VERSION "HNNBNNNYNNNNNNNNNNNNNNNNNNNNNNNNNNNNNNNNNN/4/%%%/4/'%**4NNN///"

NS_ :

BS_:

BU_: ABT_1_MIB_ab_Gen3 ABT_1_MQB BAP_Tester BT_1_MQB DU_1_MQB DU_2 DU_3 DU_4 ExBox Kombi_TT3 LSR_1 SCC1 SCC2 SDC1 SDC2 SFA TVTuner_ab_Gen3_JPN WLC_01 WLC_02 ZR_Entry ZR_High ZR_High_Korea ZR_High_TT3 ZR_MIB_OPTION_ab_Gen3 ZR_MIB_TOP_ab_Gen3 ZR_Standard

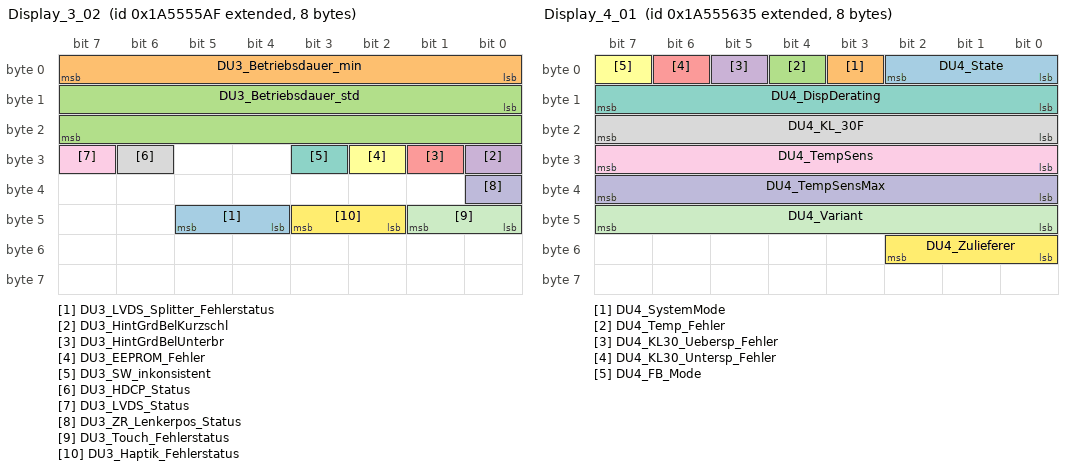
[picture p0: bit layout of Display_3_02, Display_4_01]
BO_ 2589283759 Display_3_02: 8 DU_3
 SG_ DU3_LVDS_Splitter_Fehlerstatus : 44|2@1+ (1,0) [0|3] ""  ZR_High,ZR_MIB_OPTION_ab_Gen3,ZR_MIB_TOP_ab_Gen3,ZR_Standard
 SG_ DU3_Betriebsdauer_min : 0|8@1+ (1,0) [0|59] "Unit_Minut"  ZR_High,ZR_MIB_TOP_ab_Gen3
 SG_ DU3_Betriebsdauer_std : 8|16@1+ (1,0) [0|65533] "Unit_Hours"  ZR_High,ZR_MIB_TOP_ab_Gen3
 SG_ DU3_HintGrdBelKurzschl : 24|1@1+ (1,0) [0|1] ""  ZR_High,ZR_MIB_TOP_ab_Gen3
 SG_ DU3_HintGrdBelUnterbr : 25|1@1+ (1,0) [0|1] ""  ZR_High,ZR_MIB_TOP_ab_Gen3
 SG_ DU3_EEPROM_Fehler : 26|1@1+ (1,0) [0|1] ""  ZR_High,ZR_MIB_TOP_ab_Gen3
 SG_ DU3_SW_inkonsistent : 27|1@1+ (1,0) [0|1] ""  ZR_High,ZR_MIB_TOP_ab_Gen3
 SG_ DU3_HDCP_Status : 30|1@1+ (1,0) [0|1] ""  ZR_High,ZR_MIB_TOP_ab_Gen3
 SG_ DU3_LVDS_Status : 31|1@1+ (1,0) [0|1] ""  ZR_High,ZR_MIB_TOP_ab_Gen3
 SG_ DU3_ZR_Lenkerpos_Status : 32|1@1+ (1,0) [0|1] ""  ZR_High,ZR_MIB_TOP_ab_Gen3
 SG_ DU3_Touch_Fehlerstatus : 40|2@1+ (1,0) [0|3] ""  ZR_High,ZR_MIB_TOP_ab_Gen3
 SG_ DU3_Haptik_Fehlerstatus : 42|2@1+ (1,0) [0|3] ""  ZR_High,ZR_MIB_TOP_ab_Gen3

BO_ 2589283893 Display_4_01: 8 DU_4
 SG_ DU4_State : 0|3@1+ (1,0) [0|7] ""  ZR_High,ZR_MIB_TOP_ab_Gen3
 SG_ DU4_SystemMode : 3|1@1+ (1,0) [0|1] ""  ZR_High,ZR_MIB_TOP_ab_Gen3
 SG_ DU4_Temp_Fehler : 4|1@1+ (1,0) [0|1] ""  ZR_High,ZR_MIB_TOP_ab_Gen3
 SG_ DU4_KL30_Uebersp_Fehler : 5|1@1+ (1,0) [0|1] ""  ZR_High,ZR_MIB_TOP_ab_Gen3
 SG_ DU4_KL30_Untersp_Fehler : 6|1@1+ (1,0) [0|1] ""  ZR_High,ZR_MIB_TOP_ab_Gen3
 SG_ DU4_FB_Mode : 7|1@1+ (1,0) [0|1] ""  ZR_High,ZR_MIB_TOP_ab_Gen3
 SG_ DU4_DispDerating : 8|8@1+ (1,0) [0|100] "Unit_PerCent"  ZR_High,ZR_MIB_TOP_ab_Gen3
 SG_ DU4_KL_30F : 16|8@1+ (0.1,0) [0|25.3] "Unit_Volt"  ZR_High,ZR_MIB_TOP_ab_Gen3
 SG_ DU4_TempSens : 24|8@1+ (1,-55) [-55|127] "Unit_DegreCelsi"  ZR_High,ZR_MIB_TOP_ab_Gen3
 SG_ DU4_TempSensMax : 32|8@1+ (1,-55) [-55|127] "Unit_DegreCelsi"  ZR_High,ZR_MIB_TOP_ab_Gen3
 SG_ DU4_Variant : 40|8@1+ (1,0) [0|253] ""  ZR_High,ZR_MIB_TOP_ab_Gen3
 SG_ DU4_Zulieferer : 48|3@1+ (1,0) [0|7] ""  ZR_High,ZR_MIB_TOP_ab_Gen3

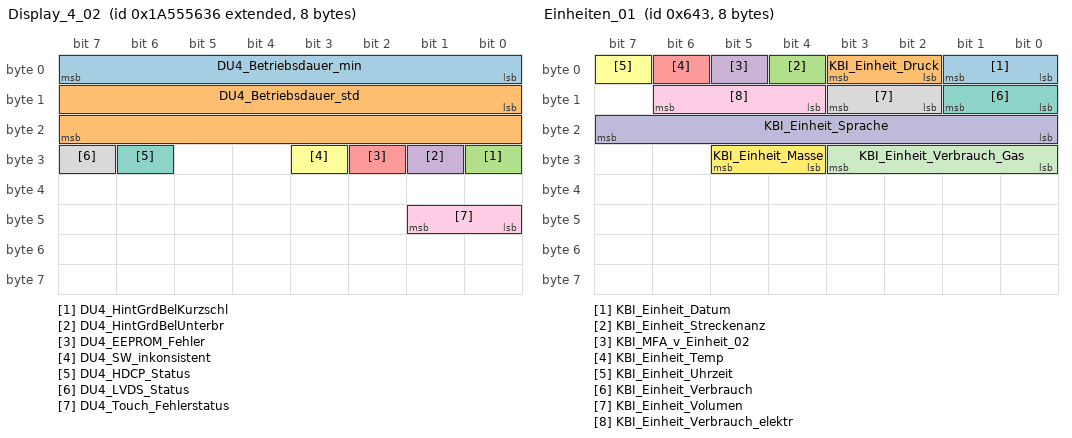
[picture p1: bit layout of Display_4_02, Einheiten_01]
BO_ 2589283894 Display_4_02: 8 DU_4
 SG_ DU4_Betriebsdauer_min : 0|8@1+ (1,0) [0|59] "Unit_Minut"  ZR_High,ZR_MIB_TOP_ab_Gen3
 SG_ DU4_Betriebsdauer_std : 8|16@1+ (1,0) [0|65533] "Unit_Hours"  ZR_High,ZR_MIB_TOP_ab_Gen3
 SG_ DU4_HintGrdBelKurzschl : 24|1@1+ (1,0) [0|1] ""  ZR_High,ZR_MIB_TOP_ab_Gen3
 SG_ DU4_HintGrdBelUnterbr : 25|1@1+ (1,0) [0|1] ""  ZR_High,ZR_MIB_TOP_ab_Gen3
 SG_ DU4_EEPROM_Fehler : 26|1@1+ (1,0) [0|1] ""  ZR_High,ZR_MIB_TOP_ab_Gen3
 SG_ DU4_SW_inkonsistent : 27|1@1+ (1,0) [0|1] ""  ZR_High,ZR_MIB_TOP_ab_Gen3
 SG_ DU4_HDCP_Status : 30|1@1+ (1,0) [0|1] ""  ZR_High,ZR_MIB_TOP_ab_Gen3
 SG_ DU4_LVDS_Status : 31|1@1+ (1,0) [0|1] ""  ZR_High,ZR_MIB_TOP_ab_Gen3
 SG_ DU4_Touch_Fehlerstatus : 40|2@1+ (1,0) [0|3] ""  ZR_High,ZR_MIB_TOP_ab_Gen3

BO_ 2583753221 DU_1_SWDL_Req: 8 DU_1_MQB
 SG_ DU_1_SWDL_Req_Data : 0|64@1+ (1,0) [0|1.84467440737096E+019] ""  ZR_Entry,ZR_High,ZR_High_Korea,ZR_High_TT3,ZR_MIB_OPTION_ab_Gen3,ZR_MIB_TOP_ab_Gen3,ZR_Standard

BO_ 2583884293 DU_1_SWDL_Resp: 8 ZR_Entry
 SG_ DU_1_SWDL_Resp_Data : 0|64@1+ (1,0) [0|1.84467440737096E+019] ""  DU_1_MQB

BO_ 2583753989 DU_2_SWDL_Req: 8 DU_2
 SG_ DU_2_SWDL_Req_Data : 0|64@1+ (1,0) [0|1.84467440737096E+019] ""  ZR_High,ZR_MIB_OPTION_ab_Gen3,ZR_MIB_TOP_ab_Gen3,ZR_Standard

BO_ 2583885061 DU_2_SWDL_Resp: 8 ZR_High
 SG_ DU_2_SWDL_Resp_Data : 0|64@1+ (1,0) [0|1.84467440737096E+019] ""  DU_2

BO_ 2583756293 DU_3_SWDL_Req: 8 DU_3
 SG_ DU_3_SWDL_Req_Data : 0|64@1+ (1,0) [0|1.84467440737096E+019] ""  ZR_High,ZR_MIB_TOP_ab_Gen3

BO_ 2583887365 DU_3_SWDL_Resp: 8 ZR_High
 SG_ DU_3_SWDL_Resp_Data : 0|64@1+ (1,0) [0|1.84467440737096E+019] ""  DU_3

BO_ 2583753733 DU_4_SWDL_Req: 8 DU_4
 SG_ DU_4_SWDL_Req_Data : 0|64@1+ (1,0) [0|1.84467440737096E+019] ""  ZR_High,ZR_MIB_TOP_ab_Gen3

BO_ 2583884805 DU_4_SWDL_Resp: 8 ZR_High
 SG_ DU_4_SWDL_Resp_Data : 0|64@1+ (1,0) [0|1.84467440737096E+019] ""  DU_4

BO_ 1603 Einheiten_01: 8 ZR_High_Korea
 SG_ KBI_Einheit_Datum : 0|2@1+ (1,0) [0|3] ""  ExBox
 SG_ KBI_Einheit_Druck : 2|2@1+ (1,0) [0|3] "" Vector__XXX
 SG_ KBI_Einheit_Streckenanz : 4|1@1+ (1,0) [0|1] ""  ExBox
 SG_ KBI_MFA_v_Einheit_02 : 5|1@1+ (1,0) [0|1] ""  ExBox
 SG_ KBI_Einheit_Temp : 6|1@1+ (1,0) [0|1] ""  ExBox
 SG_ KBI_Einheit_Uhrzeit : 7|1@1+ (1,0) [0|1] ""  ExBox
 SG_ KBI_Einheit_Verbrauch : 8|2@1+ (1,0) [0|3] ""  ExBox
 SG_ KBI_Einheit_Volumen : 10|2@1+ (1,0) [0|3] ""  ExBox
 SG_ KBI_Einheit_Verbrauch_elektr : 12|3@1+ (1,0) [0|7] "" Vector__XXX
 SG_ KBI_Einheit_Sprache : 16|8@1+ (1,0) [0|255] ""  ExBox
 SG_ KBI_Einheit_Verbrauch_Gas : 24|4@1+ (1,0) [0|15] "" Vector__XXX
 SG_ KBI_Einheit_Masse : 28|2@1+ (1,0) [0|3] "" Vector__XXX

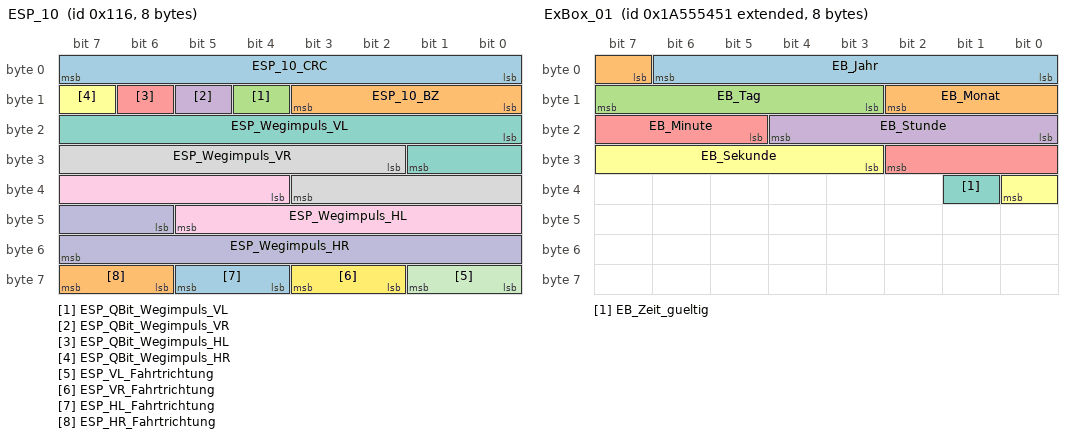
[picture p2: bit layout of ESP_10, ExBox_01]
BO_ 278 ESP_10: 8 ZR_High_Korea
 SG_ ESP_10_CRC : 0|8@1+ (1,0) [0|255] "" Vector__XXX
 SG_ ESP_10_BZ : 8|4@1+ (1,0) [0|15] ""  ExBox
 SG_ ESP_QBit_Wegimpuls_VL : 12|1@1+ (1,0) [0|1] ""  ExBox
 SG_ ESP_QBit_Wegimpuls_VR : 13|1@1+ (1,0) [0|1] ""  ExBox
 SG_ ESP_QBit_Wegimpuls_HL : 14|1@1+ (1,0) [0|1] ""  ExBox
 SG_ ESP_QBit_Wegimpuls_HR : 15|1@1+ (1,0) [0|1] ""  ExBox
 SG_ ESP_Wegimpuls_VL : 16|10@1+ (1,0) [0|1000] ""  ExBox
 SG_ ESP_Wegimpuls_VR : 26|10@1+ (1,0) [0|1000] ""  ExBox
 SG_ ESP_Wegimpuls_HL : 36|10@1+ (1,0) [0|1000] ""  ExBox
 SG_ ESP_Wegimpuls_HR : 46|10@1+ (1,0) [0|1000] ""  ExBox
 SG_ ESP_VL_Fahrtrichtung : 56|2@1+ (1,0) [0|3] ""  ExBox
 SG_ ESP_VR_Fahrtrichtung : 58|2@1+ (1,0) [0|3] ""  ExBox
 SG_ ESP_HL_Fahrtrichtung : 60|2@1+ (1,0) [0|3] ""  ExBox
 SG_ ESP_HR_Fahrtrichtung : 62|2@1+ (1,0) [0|3] ""  ExBox

BO_ 1629 ESP_20: 8 ZR_High_Korea
 SG_ ESP_20_CRC : 0|8@1+ (1,0) [0|255] "" Vector__XXX
 SG_ ESP_20_BZ : 8|4@1+ (1,0) [0|15] "" Vector__XXX
 SG_ BR_Systemart : 12|2@1+ (1,0) [0|3] "" Vector__XXX
 SG_ ESP_SpannungsAnf_02 : 14|2@1+ (1,0) [0|3] "" Vector__XXX
 SG_ ESP_Zaehnezahl : 16|8@1+ (1,0) [0|255] ""  ExBox
 SG_ ESP_Charisma_FahrPr : 24|4@1+ (1,0) [0|15] "" Vector__XXX
 SG_ ESP_Charisma_Status : 28|2@1+ (1,0) [0|3] "" Vector__XXX
 SG_ ESP_Wiederstart_Anz_01 : 30|1@1+ (1,0) [0|1] "" Vector__XXX
 SG_ ESP_Wiederstart_Anz_02 : 31|1@1+ (1,0) [0|1] "" Vector__XXX
 SG_ ESP_Wiederstart_Anz_03 : 32|1@1+ (1,0) [0|1] "" Vector__XXX
 SG_ ESP_Wiederstart_Anz_04 : 33|1@1+ (1,0) [0|1] "" Vector__XXX
 SG_ ESP_Stoppverbot_Anz_01 : 34|1@1+ (1,0) [0|1] "" Vector__XXX
 SG_ ESP_Stoppverbot_Anz_02 : 35|1@1+ (1,0) [0|1] "" Vector__XXX
 SG_ ESP_Stoppverbot_Anz_03 : 36|1@1+ (1,0) [0|1] "" Vector__XXX
 SG_ ESP_Stoppverbot_Anz_04 : 37|1@1+ (1,0) [0|1] "" Vector__XXX
 SG_ ESP_Stoppverbot_Anz_05 : 38|1@1+ (1,0) [0|1] "" Vector__XXX
 SG_ ESP_Stoppverbot_Anz_06 : 39|1@1+ (1,0) [0|1] "" Vector__XXX
 SG_ ESP_Stoppverbot_Anz_07 : 40|1@1+ (1,0) [0|1] "" Vector__XXX
 SG_ ESP_Stoppverbot_Anz_Std : 41|1@1+ (1,0) [0|1] "" Vector__XXX
 SG_ ESP_Dachrelingsensor : 42|2@1+ (1,0) [0|3] "" Vector__XXX
 SG_ ESP_Stoppverbot_Anz_08 : 44|1@1+ (1,0) [0|1] "" Vector__XXX
 SG_ HDC_Charisma_FahrPr : 45|4@1+ (1,0) [0|15] "" Vector__XXX
 SG_ HDC_Charisma_Status : 49|2@1+ (1,0) [0|3] "" Vector__XXX
 SG_ BR_QBit_Reifenumfang : 51|1@1+ (1,0) [0|1] "" Vector__XXX
 SG_ BR_Reifenumfang : 52|12@1+ (1,0) [0|4095] "Unit_MilliMeter" Vector__XXX

BO_ 795 ESP_24: 8 ZR_High_Korea
 SG_ ESP_24_CRC : 0|8@1+ (1,0) [0|255] "" Vector__XXX
 SG_ ESP_24_BZ : 8|4@1+ (1,0) [0|15] "" Vector__XXX
 SG_ ESP_Lampe : 12|1@1+ (1,0) [0|1] "" Vector__XXX
 SG_ ABS_Lampe : 13|1@1+ (1,0) [0|1] "" Vector__XXX
 SG_ BK_Lampe_02 : 14|2@1+ (1,0) [0|3] "" Vector__XXX
 SG_ TC_Lampe : 16|1@1+ (1,0) [0|1] "" Vector__XXX
 SG_ ESP_m_Raddrehz : 17|15@1+ (0.002,0) [0|65.278] "Unit_Hertz" Vector__XXX
 SG_ ESP_Textanzeigen_03 : 32|5@1+ (1,0) [0|31] "" Vector__XXX
 SG_ ESP_Meldungen : 37|3@1+ (1,0) [0|7] "" Vector__XXX
 SG_ ESP_Wegimp_VA : 40|11@1+ (1,0) [0|2047] ""  ExBox
 SG_ ESP_Fehlerstatus_Wegimp : 51|1@1+ (1,0) [0|1] ""  ExBox
 SG_ ESP_Wegimp_Ueberlauf : 52|1@1+ (1,0) [0|1] ""  ExBox
 SG_ ESP_QBit_Wegimp_VA : 53|1@1+ (1,0) [0|1] ""  ExBox
 SG_ ESP_HDC_FktLampe : 54|1@1+ (1,0) [0|1] "" Vector__XXX
 SG_ ESP_Off_Lampe : 55|1@1+ (1,0) [0|1] "" Vector__XXX
 SG_ ESP_HDC_Regelgeschw : 56|7@1+ (0.32,0) [0.32|39.68] "Unit_KiloMeterPerHour" Vector__XXX
 SG_ ESP_BKV_Warnung : 63|1@1+ (1,0) [0|1] "" Vector__XXX

BO_ 2589283409 ExBox_01: 8 ExBox
 SG_ EB_Jahr : 0|7@1+ (1,2000) [2000|2127] "Unit_Year"  ZR_High_Korea
 SG_ EB_Monat : 7|4@1+ (1,0) [1|12] "Unit_Month"  ZR_High_Korea
 SG_ EB_Tag : 11|5@1+ (1,0) [1|31] "Unit_Day"  ZR_High_Korea
 SG_ EB_Stunde : 16|5@1+ (1,0) [0|23] "Unit_Hours"  ZR_High_Korea
 SG_ EB_Minute : 21|6@1+ (1,0) [0|59] "Unit_Minut"  ZR_High_Korea
 SG_ EB_Sekunde : 27|6@1+ (1,0) [0|59] "Unit_Secon"  ZR_High_Korea
 SG_ EB_Zeit_gueltig : 33|1@1+ (1,0) [0|1] ""  ZR_High_Korea

BO_ 986 Gateway_71: 8 ZR_High_Korea
 SG_ ESP_05_alt : 0|1@1+ (1,0) [0|1] "" Vector__XXX
 SG_ EPB_01_alt : 1|1@1+ (1,0) [0|1] "" Vector__XXX
 SG_ ESP_21_alt : 2|1@1+ (1,0) [0|1] ""  ExBox
 SG_ LWI_01_alt : 3|1@1+ (1,0) [0|1] ""  ExBox
 SG_ Parkhilfe_01_alt : 4|1@1+ (1,0) [0|1] "" Vector__XXX
 SG_ Kamera_Status_alt : 5|1@1+ (1,0) [0|1] "" Vector__XXX
 SG_ ESP_HDC_Standby : 6|1@1+ (1,0) [0|1] "" Vector__XXX
 SG_ ECD_Bremslicht : 8|1@1+ (1,0) [0|1] "" Vector__XXX
 SG_ EPB_Status : 9|2@1+ (1,0) [0|3] "" Vector__XXX
 SG_ EPB_QBit_Pedalweg_Kuppl : 11|1@1+ (1,0) [0|1] "" Vector__XXX
 SG_ ESP_QBit_v_Signal : 12|1@1+ (1,0) [0|1] ""  ExBox
 SG_ ABS_Bremsung : 13|1@1+ (1,0) [0|1] "" Vector__XXX
 SG_ ESP_Eingriff : 14|1@1+ (1,0) [0|1] "" Vector__XXX
 SG_ Kamera_FSH_aktiv : 15|1@1+ (1,0) [0|1] "" Vector__XXX
 SG_ EPB_Pedalweg_Kuppl : 16|8@1+ (0.4,0) [8|92] "Unit_PerCent" Vector__XXX
 SG_ ESP_v_Signal : 24|16@1+ (0.01,0) [0|655.32] "Unit_KiloMeterPerHour"  ExBox
 SG_ LWI_QBit_Lenkradwinkel : 40|1@1+ (1,0) [0|1] ""  ExBox
 SG_ LWI_Sensorstatus : 41|1@1+ (1,0) [0|1] ""  ExBox
 SG_ LWI_VZ_Lenkradwinkel : 42|1@1+ (1,0) [0|1] ""  ExBox
 SG_ LWI_Lenkradwinkel : 43|13@1+ (0.1,0) [0|800] "Unit_DegreOfArc"  ExBox
 SG_ PH_Anf_Audioabsenkung : 56|1@1+ (1,0) [0|1] "" Vector__XXX
 SG_ PH_Systemzustand : 57|3@1+ (1,0) [0|7] "" Vector__XXX
 SG_ PH_Taster : 60|2@1+ (1,0) [0|3] "" Vector__XXX
 SG_ ESP_MKB_Abbruch_Geschw : 62|1@1+ (1,0) [0|1] "" Vector__XXX
 SG_ PLA_Anf_Aufschaltung_RVC : 63|1@1+ (1,0) [0|1] "" Vector__XXX

BO_ 987 Gateway_72: 8 ZR_High_Korea
 SG_ BCM_01_alt : 0|1@1+ (1,0) [0|1] "" Vector__XXX
 SG_ SMLS_01_alt : 1|1@1+ (1,0) [0|1] ""  ExBox
 SG_ ZV_02_alt : 2|1@1+ (1,0) [0|1] "" Vector__XXX
 SG_ Wischer_01_alt : 3|1@1+ (1,0) [0|1] "" Vector__XXX
 SG_ Anhaenger_01_alt : 4|1@1+ (1,0) [0|1] ""  ExBox
 SG_ Klima_Sensor_02_alt : 5|1@1+ (1,0) [0|1] "" Vector__XXX
 SG_ Verdeck_01_alt : 6|1@1+ (1,0) [0|1] "" Vector__XXX
 SG_ Klima_11_alt : 7|1@1+ (1,0) [0|1] "" Vector__XXX
 SG_ WFS_01_alt : 8|1@1+ (1,0) [0|1] "" Vector__XXX
 SG_ Licht_Anf_01_alt : 9|1@1+ (1,0) [0|1] ""  ExBox
 SG_ ZV_verriegelt_extern_soll : 10|1@1+ (1,0) [0|1] "" Vector__XXX
 SG_ BH_Lichthupe : 11|1@1+ (1,0) [0|1] "" Vector__XXX
 SG_ WFS_Klemmenfreigabe : 12|1@1+ (1,0) [0|1] "" Vector__XXX
 SG_ ZV_Tankklappe_offen : 13|1@1+ (1,0) [0|1] "" Vector__XXX
 SG_ AAG_Anhaenger_abgesteckt : 14|1@1+ (1,0) [0|1] "" Vector__XXX
 SG_ BCM1_LDS_Stellung : 15|3@1+ (1,0) [0|7] "" Vector__XXX
 SG_ VS_Verdeck_Anf : 18|1@1+ (1,0) [0|1] "" Vector__XXX
 SG_ VS_VD_entriegelt : 19|1@1+ (1,0) [0|1] "" Vector__XXX
 SG_ ZV_HFS_offen : 20|1@1+ (1,0) [0|1] "" Vector__XXX
 SG_ ZV_HBFS_offen : 21|1@1+ (1,0) [0|1] "" Vector__XXX
 SG_ VS_VD_offen_ver : 22|1@1+ (1,0) [0|1] "" Vector__XXX
 SG_ VS_VD_zu_ver : 23|1@1+ (1,0) [0|1] "" Vector__XXX
 SG_ ZV_BT_offen : 24|1@1+ (1,0) [0|1] "" Vector__XXX
 SG_ BCM1_Rueckfahrlicht_Schalter : 25|1@1+ (1,0) [0|1] "" Vector__XXX
 SG_ ZV_FT_offen : 26|1@1+ (1,0) [0|1] "" Vector__XXX
 SG_ Wischer_vorne_aktiv : 27|1@1+ (1,0) [0|1] "" Vector__XXX
 SG_ AAG_Anhaenger_erkannt : 28|1@1+ (1,0) [0|1] ""  ExBox
 SG_ BCM1_MH_Schalter : 29|1@1+ (1,0) [0|1] "" Vector__XXX
 SG_ ZV_HD_offen : 30|1@1+ (1,0) [0|1] "" Vector__XXX
 SG_ Waschen_vorne_aktiv : 31|1@1+ (1,0) [0|1] "" Vector__XXX
 SG_ KL_Thermomanagement : 32|2@1+ (1,0) [0|3] "" Vector__XXX
 SG_ WFS_Schluessel_Fahrberecht : 34|4@1+ (1,0) [0|15] "" Vector__XXX
 SG_ BCM_Rueckfahrlicht_Anf : 38|1@1+ (1,0) [0|1] ""  ExBox
 SG_ WWSs_01_alt : 39|1@1+ (1,0) [0|1] "" Vector__XXX
 SG_ BCM_Tankklappensteller_Fehler : 40|1@1+ (1,0) [0|1] "" Vector__XXX
 SG_ AAG_LED_aktiv : 41|1@1+ (1,0) [0|1] "" Vector__XXX
 SG_ ZV_verriegelt_soll : 42|2@1+ (1,0) [0|3] "" Vector__XXX
 SG_ ZV_Schluessel_Zugang : 44|4@1+ (1,0) [0|15] "" Vector__XXX
 SG_ WFS_ID_Geb_autorisiert_in_Kl15 : 48|1@1+ (1,0) [0|1] "" Vector__XXX
 SG_ BH_Fernlicht : 49|1@1+ (1,0) [0|1] "" Vector__XXX
 SG_ BH_Blinker_li : 50|1@1+ (1,0) [0|1] ""  ExBox
 SG_ BH_Blinker_re : 51|1@1+ (1,0) [0|1] ""  ExBox
 SG_ BCM1_OBD_FStatus_ATemp : 52|4@1+ (1,0) [0|15] "" Vector__XXX
 SG_ BCM1_Aussen_Temp_ungef : 56|8@1+ (0.5,-50) [-50|76] "Unit_DegreCelsi"  WLC_01,WLC_02

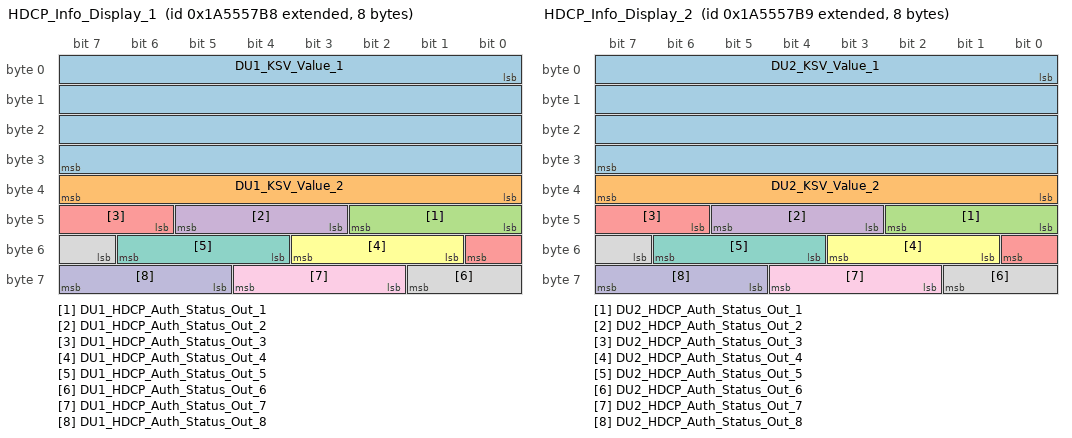
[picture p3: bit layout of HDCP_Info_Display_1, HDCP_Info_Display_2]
BO_ 2589284280 HDCP_Info_Display_1: 8 DU_1_MQB
 SG_ DU1_KSV_Value_1 : 0|32@1+ (1,0) [0|4294967295] ""  ZR_Entry,ZR_High,ZR_High_Korea,ZR_High_TT3,ZR_MIB_OPTION_ab_Gen3,ZR_MIB_TOP_ab_Gen3,ZR_Standard
 SG_ DU1_KSV_Value_2 : 32|8@1+ (1,0) [0|255] ""  ZR_Entry,ZR_High,ZR_High_Korea,ZR_High_TT3,ZR_MIB_OPTION_ab_Gen3,ZR_MIB_TOP_ab_Gen3,ZR_Standard
 SG_ DU1_HDCP_Auth_Status_Out_1 : 40|3@1+ (1,0) [0|7] ""  ZR_Entry,ZR_High,ZR_High_Korea,ZR_High_TT3,ZR_MIB_OPTION_ab_Gen3,ZR_MIB_TOP_ab_Gen3,ZR_Standard
 SG_ DU1_HDCP_Auth_Status_Out_2 : 43|3@1+ (1,0) [0|7] ""  ZR_Entry,ZR_High,ZR_High_Korea,ZR_High_TT3,ZR_MIB_OPTION_ab_Gen3,ZR_MIB_TOP_ab_Gen3,ZR_Standard
 SG_ DU1_HDCP_Auth_Status_Out_3 : 46|3@1+ (1,0) [0|7] ""  ZR_Entry,ZR_High,ZR_High_Korea,ZR_High_TT3,ZR_MIB_OPTION_ab_Gen3,ZR_MIB_TOP_ab_Gen3,ZR_Standard
 SG_ DU1_HDCP_Auth_Status_Out_4 : 49|3@1+ (1,0) [0|7] ""  ZR_Entry,ZR_High,ZR_High_Korea,ZR_High_TT3,ZR_MIB_OPTION_ab_Gen3,ZR_MIB_TOP_ab_Gen3,ZR_Standard
 SG_ DU1_HDCP_Auth_Status_Out_5 : 52|3@1+ (1,0) [0|7] ""  ZR_Entry,ZR_High,ZR_High_Korea,ZR_High_TT3,ZR_MIB_OPTION_ab_Gen3,ZR_MIB_TOP_ab_Gen3,ZR_Standard
 SG_ DU1_HDCP_Auth_Status_Out_6 : 55|3@1+ (1,0) [0|7] ""  ZR_Entry,ZR_High,ZR_High_Korea,ZR_High_TT3,ZR_MIB_OPTION_ab_Gen3,ZR_MIB_TOP_ab_Gen3,ZR_Standard
 SG_ DU1_HDCP_Auth_Status_Out_7 : 58|3@1+ (1,0) [0|7] ""  ZR_Entry,ZR_High,ZR_High_Korea,ZR_High_TT3,ZR_MIB_OPTION_ab_Gen3,ZR_MIB_TOP_ab_Gen3,ZR_Standard
 SG_ DU1_HDCP_Auth_Status_Out_8 : 61|3@1+ (1,0) [0|7] ""  ZR_Entry,ZR_High,ZR_High_Korea,ZR_High_TT3,ZR_MIB_OPTION_ab_Gen3,ZR_MIB_TOP_ab_Gen3,ZR_Standard

BO_ 2589284281 HDCP_Info_Display_2: 8 DU_2
 SG_ DU2_KSV_Value_1 : 0|32@1+ (1,0) [0|4294967295] ""  ZR_High,ZR_MIB_OPTION_ab_Gen3,ZR_MIB_TOP_ab_Gen3,ZR_Standard
 SG_ DU2_KSV_Value_2 : 32|8@1+ (1,0) [0|255] ""  ZR_High,ZR_MIB_OPTION_ab_Gen3,ZR_MIB_TOP_ab_Gen3,ZR_Standard
 SG_ DU2_HDCP_Auth_Status_Out_1 : 40|3@1+ (1,0) [0|7] ""  ZR_High,ZR_MIB_OPTION_ab_Gen3,ZR_MIB_TOP_ab_Gen3,ZR_Standard
 SG_ DU2_HDCP_Auth_Status_Out_2 : 43|3@1+ (1,0) [0|7] ""  ZR_High,ZR_MIB_OPTION_ab_Gen3,ZR_MIB_TOP_ab_Gen3,ZR_Standard
 SG_ DU2_HDCP_Auth_Status_Out_3 : 46|3@1+ (1,0) [0|7] ""  ZR_High,ZR_MIB_OPTION_ab_Gen3,ZR_MIB_TOP_ab_Gen3,ZR_Standard
 SG_ DU2_HDCP_Auth_Status_Out_4 : 49|3@1+ (1,0) [0|7] ""  ZR_High,ZR_MIB_OPTION_ab_Gen3,ZR_MIB_TOP_ab_Gen3,ZR_Standard
 SG_ DU2_HDCP_Auth_Status_Out_5 : 52|3@1+ (1,0) [0|7] ""  ZR_High,ZR_MIB_OPTION_ab_Gen3,ZR_MIB_TOP_ab_Gen3,ZR_Standard
 SG_ DU2_HDCP_Auth_Status_Out_6 : 55|3@1+ (1,0) [0|7] ""  ZR_High,ZR_MIB_OPTION_ab_Gen3,ZR_MIB_TOP_ab_Gen3,ZR_Standard
 SG_ DU2_HDCP_Auth_Status_Out_7 : 58|3@1+ (1,0) [0|7] ""  ZR_High,ZR_MIB_OPTION_ab_Gen3,ZR_MIB_TOP_ab_Gen3,ZR_Standard
 SG_ DU2_HDCP_Auth_Status_Out_8 : 61|3@1+ (1,0) [0|7] ""  ZR_High,ZR_MIB_OPTION_ab_Gen3,ZR_MIB_TOP_ab_Gen3,ZR_Standard

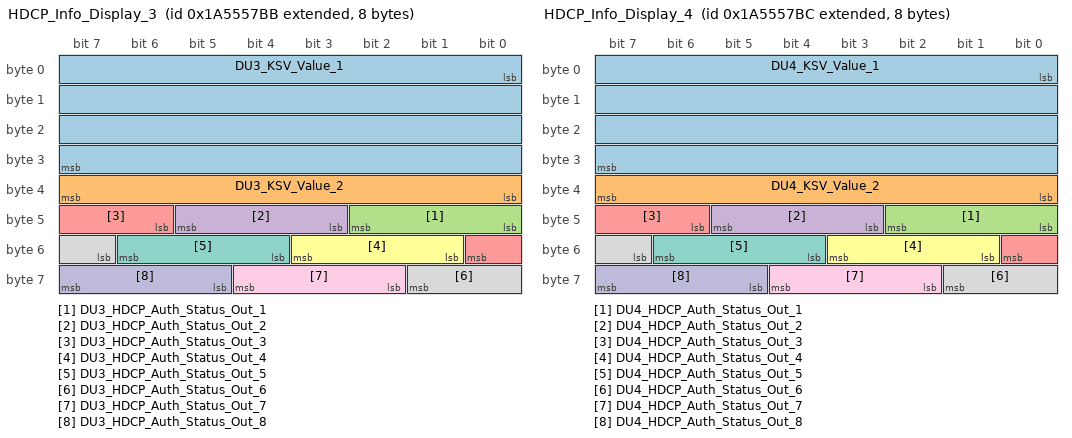
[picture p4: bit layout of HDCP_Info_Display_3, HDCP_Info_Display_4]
BO_ 2589284283 HDCP_Info_Display_3: 8 DU_3
 SG_ DU3_KSV_Value_1 : 0|32@1+ (1,0) [0|4294967295] ""  ZR_High,ZR_MIB_TOP_ab_Gen3
 SG_ DU3_KSV_Value_2 : 32|8@1+ (1,0) [0|255] ""  ZR_High,ZR_MIB_TOP_ab_Gen3
 SG_ DU3_HDCP_Auth_Status_Out_1 : 40|3@1+ (1,0) [0|7] ""  ZR_High,ZR_MIB_TOP_ab_Gen3
 SG_ DU3_HDCP_Auth_Status_Out_2 : 43|3@1+ (1,0) [0|7] ""  ZR_High,ZR_MIB_TOP_ab_Gen3
 SG_ DU3_HDCP_Auth_Status_Out_3 : 46|3@1+ (1,0) [0|7] ""  ZR_High,ZR_MIB_TOP_ab_Gen3
 SG_ DU3_HDCP_Auth_Status_Out_4 : 49|3@1+ (1,0) [0|7] ""  ZR_High,ZR_MIB_TOP_ab_Gen3
 SG_ DU3_HDCP_Auth_Status_Out_5 : 52|3@1+ (1,0) [0|7] ""  ZR_High,ZR_MIB_TOP_ab_Gen3
 SG_ DU3_HDCP_Auth_Status_Out_6 : 55|3@1+ (1,0) [0|7] ""  ZR_High,ZR_MIB_TOP_ab_Gen3
 SG_ DU3_HDCP_Auth_Status_Out_7 : 58|3@1+ (1,0) [0|7] ""  ZR_High,ZR_MIB_TOP_ab_Gen3
 SG_ DU3_HDCP_Auth_Status_Out_8 : 61|3@1+ (1,0) [0|7] ""  ZR_High,ZR_MIB_TOP_ab_Gen3

BO_ 2589284284 HDCP_Info_Display_4: 8 DU_4
 SG_ DU4_KSV_Value_1 : 0|32@1+ (1,0) [0|4294967295] ""  ZR_High,ZR_MIB_TOP_ab_Gen3
 SG_ DU4_KSV_Value_2 : 32|8@1+ (1,0) [0|255] ""  ZR_High,ZR_MIB_TOP_ab_Gen3
 SG_ DU4_HDCP_Auth_Status_Out_1 : 40|3@1+ (1,0) [0|7] ""  ZR_High,ZR_MIB_TOP_ab_Gen3
 SG_ DU4_HDCP_Auth_Status_Out_2 : 43|3@1+ (1,0) [0|7] ""  ZR_High,ZR_MIB_TOP_ab_Gen3
 SG_ DU4_HDCP_Auth_Status_Out_3 : 46|3@1+ (1,0) [0|7] ""  ZR_High,ZR_MIB_TOP_ab_Gen3
 SG_ DU4_HDCP_Auth_Status_Out_4 : 49|3@1+ (1,0) [0|7] ""  ZR_High,ZR_MIB_TOP_ab_Gen3
 SG_ DU4_HDCP_Auth_Status_Out_5 : 52|3@1+ (1,0) [0|7] ""  ZR_High,ZR_MIB_TOP_ab_Gen3
 SG_ DU4_HDCP_Auth_Status_Out_6 : 55|3@1+ (1,0) [0|7] ""  ZR_High,ZR_MIB_TOP_ab_Gen3
 SG_ DU4_HDCP_Auth_Status_Out_7 : 58|3@1+ (1,0) [0|7] ""  ZR_High,ZR_MIB_TOP_ab_Gen3
 SG_ DU4_HDCP_Auth_Status_Out_8 : 61|3@1+ (1,0) [0|7] ""  ZR_High,ZR_MIB_TOP_ab_Gen3

BO_ 2549674355 HID_ABT_1_ZR_Req: 8 ABT_1_MIB_ab_Gen3
 SG_ HID_ABT_1_ZR_Req_Data : 0|64@1+ (1,0) [0|1.84467440737096E+019] ""  ExBox,SFA,ZR_High,ZR_High_Korea,ZR_High_TT3,ZR_MIB_OPTION_ab_Gen3,ZR_MIB_TOP_ab_Gen3,ZR_Standard

BO_ 2549773297 HID_ABT_1_ZR_Resp: 8 ZR_High
 SG_ HID_ABT_1_ZR_Resp_Data : 0|64@1+ (1,0) [0|1.84467440737096E+019] ""  ABT_1_MIB_ab_Gen3,ABT_1_MQB

BO_ 2549674099 HID_BT_1_ZR_Req: 8 BT_1_MQB
 SG_ HID_BT_1_ZR_Req_Data : 0|64@1+ (1,0) [0|1.84467440737096E+019] ""  Kombi_TT3,ZR_Entry,ZR_High,ZR_High_Korea,ZR_High_TT3,ZR_MIB_OPTION_ab_Gen3,ZR_MIB_TOP_ab_Gen3,ZR_Standard

BO_ 2549773296 HID_BT_1_ZR_Resp: 8 ZR_Entry
 SG_ HID_BT_1_ZR_Resp_Data : 0|64@1+ (1,0) [0|1.84467440737096E+019] ""  BT_1_MQB

BO_ 2549674611 HID_DU_1_ZR_Req: 8 DU_1_MQB
 SG_ HID_DU_1_ZR_Req_Data : 0|64@1+ (1,0) [0|1.84467440737096E+019] ""  ZR_Entry,ZR_High,ZR_High_Korea,ZR_High_TT3,ZR_MIB_OPTION_ab_Gen3,ZR_MIB_TOP_ab_Gen3,ZR_Standard

BO_ 2549773298 HID_DU_1_ZR_Resp: 8 ZR_Entry
 SG_ HID_DU_1_ZR_Resp_Data : 0|64@1+ (1,0) [0|1.84467440737096E+019] ""  DU_1_MQB

BO_ 2549675379 HID_DU_2_ZR_Req: 8 DU_2
 SG_ HID_DU_2_ZR_Req_Data : 0|64@1+ (1,0) [0|1.84467440737096E+019] ""  ZR_High,ZR_MIB_OPTION_ab_Gen3,ZR_MIB_TOP_ab_Gen3,ZR_Standard

BO_ 2549773301 HID_DU_2_ZR_Resp: 8 ZR_High
 SG_ HID_DU_2_ZR_Resp_Data : 0|64@1+ (1,0) [0|1.84467440737096E+019] ""  DU_2

BO_ 2549677683 HID_DU_3_ZR_Req: 8 DU_3
 SG_ HID_DU_3_ZR_Req_Data : 0|64@1+ (1,0) [0|1.84467440737096E+019] ""  ZR_High,ZR_MIB_TOP_ab_Gen3

BO_ 2549808755 HID_DU_3_ZR_Resp: 8 ZR_High
 SG_ HID_DU_3_ZR_Resp_Data : 0|64@1+ (1,0) [0|1.84467440737096E+019] ""  DU_3

BO_ 2549675123 HID_DU_4_ZR_Req: 8 DU_4
 SG_ HID_DU_4_ZR_Req_Data : 0|64@1+ (1,0) [0|1.84467440737096E+019] ""  ZR_High,ZR_MIB_TOP_ab_Gen3

BO_ 2549773300 HID_DU_4_ZR_Resp: 8 ZR_High
 SG_ HID_DU_4_ZR_Resp_Data : 0|64@1+ (1,0) [0|1.84467440737096E+019] ""  DU_4

BO_ 2549675635 HID_LSR_1_ZR_Req: 8 LSR_1
 SG_ HID_LSR_1_ZR_Req : 0|64@1+ (1,0) [0|1.84467440737096E+019] ""  ZR_High,ZR_MIB_OPTION_ab_Gen3,ZR_MIB_TOP_ab_Gen3,ZR_Standard

BO_ 2549773302 HID_LSR_1_ZR_Resp: 8 ZR_High
 SG_ HID_LSR_1_ZR_Resp : 0|64@1+ (1,0) [0|1.84467440737096E+019] ""  LSR_1

BO_ 2549656179 HID_SCC1_ZR_Req: 8 SCC1
 SG_ HID_SCC1_ZR_Req_Data : 0|64@1+ (1,0) [0|1.84467440737096E+019] ""  ZR_High

BO_ 2549787251 HID_SCC1_ZR_Resp: 8 ZR_High
 SG_ HID_SCC1_ZR_Resp_Data : 0|64@1+ (1,0) [0|1.84467440737096E+019] ""  SCC1

BO_ 2549656435 HID_SCC2_ZR_Req: 8 SCC2
 SG_ HID_SCC2_ZR_Req_Data : 0|64@1+ (1,0) [0|1.84467440737096E+019] ""  ZR_High

BO_ 2549787507 HID_SCC2_ZR_Resp: 8 ZR_High
 SG_ HID_SCC2_ZR_Resp_Data : 0|64@1+ (1,0) [0|1.84467440737096E+019] ""  SCC2

BO_ 2549655411 HID_SDC1_ZR_Req: 8 SDC1
 SG_ HID_SDC1_ZR_Req_Data : 0|64@1+ (1,0) [0|1.84467440737096E+019] ""  ZR_High

BO_ 2549786483 HID_SDC1_ZR_Resp: 8 ZR_High
 SG_ HID_SDC1_ZR_Resp_Data : 0|64@1+ (1,0) [0|1.84467440737096E+019] ""  SDC1

BO_ 2549655667 HID_SDC2_ZR_Req: 8 SDC2
 SG_ HID_SDC2_ZR_Req_Data : 0|64@1+ (1,0) [0|1.84467440737096E+019] ""  ZR_High

BO_ 2549786739 HID_SDC2_ZR_Resp: 8 ZR_High
 SG_ HID_SDC2_ZR_Resp_Data : 0|64@1+ (1,0) [0|1.84467440737096E+019] ""  SDC2

BO_ 2549642225 HID_ZR_ABT_1_Req: 8 ZR_High
 SG_ HID_ZR_ABT_1_Req_Data : 0|64@1+ (1,0) [0|1.84467440737096E+019] ""  ABT_1_MIB_ab_Gen3,ABT_1_MQB

BO_ 2549805427 HID_ZR_ABT_1_Resp: 8 ABT_1_MIB_ab_Gen3
 SG_ HID_ZR_ABT_1_Resp_Data : 0|64@1+ (1,0) [0|1.84467440737096E+019] ""  ZR_High,ZR_High_Korea,ZR_High_TT3,ZR_MIB_OPTION_ab_Gen3,ZR_MIB_TOP_ab_Gen3,ZR_Standard

BO_ 2549642224 HID_ZR_BT_1_Req: 8 ZR_Entry
 SG_ HID_ZR_BT_1_Req_Data : 0|64@1+ (1,0) [0|1.84467440737096E+019] ""  BT_1_MQB

BO_ 2549805171 HID_ZR_BT_1_Resp: 8 BT_1_MQB
 SG_ HID_ZR_BT_1_Resp_Data : 0|64@1+ (1,0) [0|1.84467440737096E+019] ""  ZR_Entry,ZR_High,ZR_High_Korea,ZR_High_TT3,ZR_MIB_OPTION_ab_Gen3,ZR_MIB_TOP_ab_Gen3,ZR_Standard

BO_ 2549642226 HID_ZR_DU_1_Req: 8 ZR_Entry
 SG_ HID_ZR_DU_1_Req_Data : 0|64@1+ (1,0) [0|1.84467440737096E+019] ""  DU_1_MQB

BO_ 2549805683 HID_ZR_DU_1_Resp: 8 DU_1_MQB
 SG_ HID_ZR_DU_1_Resp_Data : 0|64@1+ (1,0) [0|1.84467440737096E+019] ""  ZR_Entry,ZR_High,ZR_High_Korea,ZR_High_TT3,ZR_MIB_OPTION_ab_Gen3,ZR_MIB_TOP_ab_Gen3,ZR_Standard

BO_ 2549642229 HID_ZR_DU_2_Req: 8 ZR_High
 SG_ HID_ZR_DU_2_Req_Data : 0|64@1+ (1,0) [0|1.84467440737096E+019] ""  DU_2

BO_ 2549806451 HID_ZR_DU_2_Resp: 8 DU_2
 SG_ HID_ZR_DU_2_Resp_Data : 0|64@1+ (1,0) [0|1.84467440737096E+019] ""  ZR_High,ZR_MIB_OPTION_ab_Gen3,ZR_MIB_TOP_ab_Gen3,ZR_Standard

BO_ 2549642238 HID_ZR_DU_3_Req: 8 ZR_High
 SG_ HID_ZR_DU_3_Req_Data : 0|64@1+ (1,0) [0|1.84467440737096E+019] ""  DU_3

BO_ 2549773310 HID_ZR_DU_3_Resp: 8 DU_3
 SG_ HID_ZR_DU_3_Resp_Data : 0|64@1+ (1,0) [0|1.84467440737096E+019] ""  ZR_High,ZR_MIB_TOP_ab_Gen3

BO_ 2549642228 HID_ZR_DU_4_Req: 8 ZR_High
 SG_ HID_ZR_DU_4_Req_Data : 0|64@1+ (1,0) [0|1.84467440737096E+019] ""  DU_4

BO_ 2549806195 HID_ZR_DU_4_Resp: 8 DU_4
 SG_ HID_ZR_DU_4_Resp_Data : 0|64@1+ (1,0) [0|1.84467440737096E+019] ""  ZR_High,ZR_MIB_TOP_ab_Gen3

BO_ 2549642230 HID_ZR_LSR_1_Req: 8 ZR_High
 SG_ HID_ZR_LSR_1_Req : 0|64@1+ (1,0) [0|1.84467440737096E+019] ""  LSR_1

BO_ 2549806707 HID_ZR_LSR_1_Resp: 8 LSR_1
 SG_ HID_ZR_LSR_1_Resp : 0|64@1+ (1,0) [0|1.84467440737096E+019] ""  ZR_High,ZR_MIB_OPTION_ab_Gen3,ZR_MIB_TOP_ab_Gen3,ZR_Standard

BO_ 2549642154 HID_ZR_SCC1_Req: 8 ZR_High
 SG_ HID_ZR_SCC_01_Req_Data : 0|64@1+ (1,0) [0|1.84467440737096E+019] ""  SCC1

BO_ 2549773226 HID_ZR_SCC1_Resp: 8 SCC1
 SG_ HID_ZR_SCC_01_Resp_Data : 0|64@1+ (1,0) [0|1.84467440737096E+019] ""  ZR_High

BO_ 2549642155 HID_ZR_SCC2_Req: 8 ZR_High
 SG_ HID_ZR_SCC_02_Req_Data : 0|64@1+ (1,0) [0|1.84467440737096E+019] ""  SCC2

BO_ 2549773227 HID_ZR_SCC2_Resp: 8 SCC2
 SG_ HID_ZR_SCC_02_Resp_Data : 0|64@1+ (1,0) [0|1.84467440737096E+019] ""  ZR_High

BO_ 2549642151 HID_ZR_SDC1_Req: 8 ZR_High
 SG_ HID_ZR_SDC1_Req_Data : 0|64@1+ (1,0) [0|1.84467440737096E+019] ""  SDC1

BO_ 2549773223 HID_ZR_SDC1_Resp: 8 SDC1
 SG_ HID_ZR_SDC1_Resp_Data : 0|64@1+ (1,0) [0|1.84467440737096E+019] ""  ZR_High

BO_ 2549642152 HID_ZR_SDC2_Req: 8 ZR_High
 SG_ HID_ZR_SDC2_Req_Data : 0|64@1+ (1,0) [0|1.84467440737096E+019] ""  SDC2

BO_ 2549773224 HID_ZR_SDC2_Resp: 8 SDC2
 SG_ HID_ZR_SDC2_Resp_Data : 0|64@1+ (1,0) [0|1.84467440737096E+019] ""  ZR_High

BO_ 1792 ISO_Funktionaler_Req_All: 8 ZR_Entry
 SG_ ISO_ALL_01_Req_Data : 0|64@1+ (1,0) [0|1.84467440737096E+019] ""  SCC1,SCC2,SDC1,SDC2,WLC_01,WLC_02

BO_ 2549874858 ISOx_SCC1_Req: 8 ZR_High
 SG_ ISOx_SCC1_Req_Data : 0|64@1+ (1,0) [0|1.84467440737096E+019] ""  SCC1

BO_ 2550005930 ISOx_SCC1_Resp: 8 SCC1
 SG_ ISOx_SCC1_Resp_Data : 0|64@1+ (1,0) [0|1.84467440737096E+019] ""  ZR_High

BO_ 2549874859 ISOx_SCC2_Req: 8 ZR_High
 SG_ ISOx_SCC2_Req_Data : 0|64@1+ (1,0) [0|1.84467440737096E+019] ""  SCC2

BO_ 2550005931 ISOx_SCC2_Resp: 8 SCC2
 SG_ ISOx_SCC2_Resp_Data : 0|64@1+ (1,0) [0|1.84467440737096E+019] ""  ZR_High

BO_ 2549874855 ISOx_SDC1_Req: 8 ZR_High
 SG_ ISOx_SDC1_Req_Data : 0|64@1+ (1,0) [0|1.84467440737096E+019] ""  SDC1

BO_ 2550005927 ISOx_SDC1_Resp: 8 SDC1
 SG_ ISOx_SDC1_Resp_Data : 0|64@1+ (1,0) [0|1.84467440737096E+019] ""  ZR_High

BO_ 2549874856 ISOx_SDC2_Req: 8 ZR_High
 SG_ ISOx_SDC2_Req_Data : 0|64@1+ (1,0) [0|1.84467440737096E+019] ""  SDC2

BO_ 2550005928 ISOx_SDC2_Resp: 8 SDC2
 SG_ ISOx_SDC2_Resp_Data : 0|64@1+ (1,0) [0|1.84467440737096E+019] ""  ZR_High

BO_ 2549874853 ISOx_WLC1_Req: 8 ZR_Entry
 SG_ ISOx_WLC1_Req_Data : 0|64@1+ (1,0) [0|1.84467440737096E+019] "Unit_None"  WLC_01

BO_ 2550005925 ISOx_WLC1_Resp: 8 WLC_01
 SG_ ISOx_WLC1_Resp_Data : 0|64@1+ (1,0) [0|1.84467440737096E+019] "Unit_None"  ZR_Entry,ZR_High,ZR_High_Korea,ZR_High_TT3,ZR_MIB_OPTION_ab_Gen3,ZR_MIB_TOP_ab_Gen3,ZR_Standard

BO_ 2549874854 ISOx_WLC2_Req: 8 ZR_High
 SG_ ISOx_WLC2_Req_Data : 0|64@1+ (1,0) [0|1.84467440737096E+019] "Unit_None"  WLC_02

BO_ 2550005926 ISOx_WLC2_Resp: 8 WLC_02
 SG_ ISOx_WLC2_Resp_Data : 0|64@1+ (1,0) [0|1.84467440737096E+019] "Unit_None"  ZR_High,ZR_High_Korea,ZR_MIB_OPTION_ab_Gen3,ZR_MIB_TOP_ab_Gen3,ZR_Standard

BO_ 960 Klemmen_Status_01: 4 ZR_Entry
 SG_ Klemmen_Status_01_CRC : 0|8@1+ (1,0) [0|255] "" Vector__XXX
 SG_ Klemmen_Status_01_BZ : 8|4@1+ (1,0) [0|15] "" Vector__XXX
 SG_ RSt_Fahrerhinweise : 12|4@1+ (1,0) [0|15] "" Vector__XXX
 SG_ ZAS_Kl_S : 16|1@1+ (1,0) [0|1] ""  ExBox,SCC1,SCC2,SDC1,SDC2,WLC_01,WLC_02
 SG_ ZAS_Kl_15 : 17|1@1+ (1,0) [0|1] ""  ABT_1_MIB_ab_Gen3,ABT_1_MQB,BT_1_MQB,DU_1_MQB,DU_2,DU_3,DU_4,ExBox,LSR_1,SCC1,SCC2,SDC1,SDC2,WLC_01,WLC_02
 SG_ ZAS_Kl_X : 18|1@1+ (1,0) [0|1] "" Vector__XXX
 SG_ ZAS_Kl_50_Startanforderung : 19|1@1+ (1,0) [0|1] ""  BT_1_MQB
 SG_ BCM_Remotestart_Betrieb : 20|1@1+ (1,0) [0|1] "" Vector__XXX
 SG_ ZAS_Kl_Infotainment : 21|1@1+ (1,0) [0|1] "" Vector__XXX
 SG_ BCM_Remotestart_KL15_Anf : 22|1@1+ (1,0) [0|1] "" Vector__XXX
 SG_ BCM_Remotestart_MO_Start : 23|1@1+ (1,0) [0|1] "" Vector__XXX
 SG_ KST_Warn_P1_ZST_def : 24|1@1+ (1,0) [0|1] "" Vector__XXX
 SG_ KST_Warn_P2_ZST_def : 25|1@1+ (1,0) [0|1] "" Vector__XXX
 SG_ KST_Fahrerhinweis_1 : 26|1@1+ (1,0) [0|1] "" Vector__XXX
 SG_ KST_Fahrerhinweis_2 : 27|1@1+ (1,0) [0|1] "" Vector__XXX
 SG_ BCM_Ausparken_Betrieb : 28|1@1+ (1,0) [0|1] "" Vector__XXX
 SG_ KST_Fahrerhinweis_4 : 29|1@1+ (1,0) [0|1] "" Vector__XXX
 SG_ KST_Fahrerhinweis_5 : 30|1@1+ (1,0) [0|1] "" Vector__XXX
 SG_ KST_Fahrerhinweis_6 : 31|1@1+ (1,0) [0|1] "" Vector__XXX

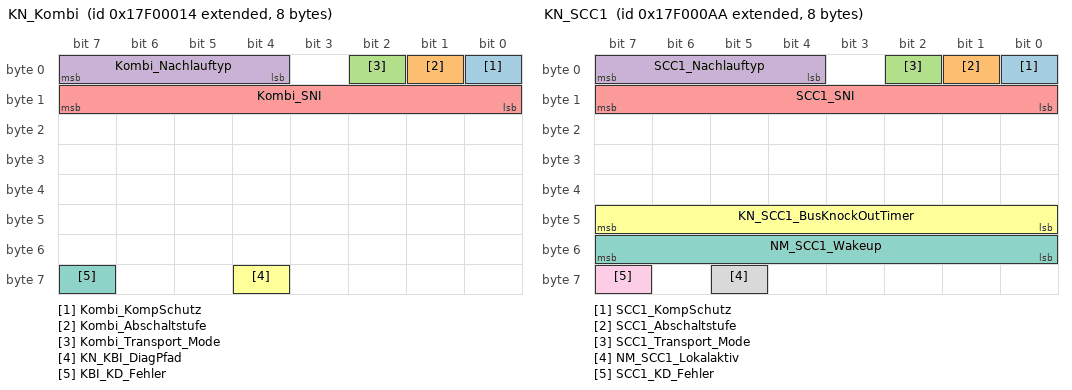
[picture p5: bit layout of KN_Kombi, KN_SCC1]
BO_ 2549088276 KN_Kombi: 8 Kombi_TT3
 SG_ Kombi_KompSchutz : 0|1@1+ (1,0) [0|1] "" Vector__XXX
 SG_ Kombi_Abschaltstufe : 1|1@1+ (1,0) [0|1] "" Vector__XXX
 SG_ Kombi_Transport_Mode : 2|1@1+ (1,0) [0|1] "" Vector__XXX
 SG_ Kombi_Nachlauftyp : 4|4@1+ (1,0) [0|15] "" Vector__XXX
 SG_ Kombi_SNI : 8|8@1+ (1,0) [0|255] "" Vector__XXX
 SG_ KN_KBI_DiagPfad : 60|1@1+ (1,0) [0|1] "" Vector__XXX
 SG_ KBI_KD_Fehler : 63|1@1+ (1,0) [0|1] ""  ZR_High_TT3

BO_ 2549088426 KN_SCC1: 8 SCC1
 SG_ SCC1_KompSchutz : 0|1@1+ (1,0) [0|1] "" Vector__XXX
 SG_ SCC1_Abschaltstufe : 1|1@1+ (1,0) [0|1] "" Vector__XXX
 SG_ SCC1_Transport_Mode : 2|1@1+ (1,0) [0|1] "" Vector__XXX
 SG_ SCC1_Nachlauftyp : 4|4@1+ (1,0) [0|15] ""  ZR_High
 SG_ SCC1_SNI : 8|8@1+ (1,0) [0|255] ""  ZR_High
 SG_ KN_SCC1_BusKnockOutTimer : 40|8@1+ (1,0) [0|254] "" Vector__XXX
 SG_ NM_SCC1_Wakeup : 48|8@1+ (1,0) [0|255] ""  ZR_High
 SG_ NM_SCC1_Lokalaktiv : 61|1@1+ (1,0) [0|1] ""  ZR_High
 SG_ SCC1_KD_Fehler : 63|1@1+ (1,0) [0|1] ""  ZR_High

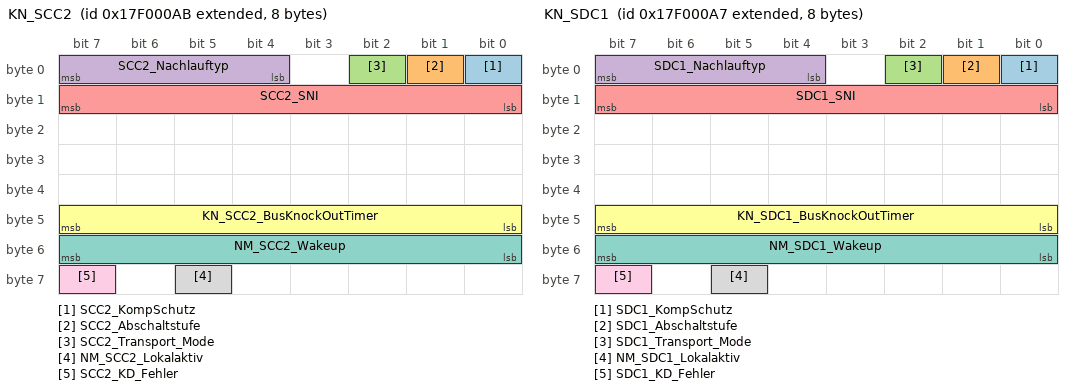
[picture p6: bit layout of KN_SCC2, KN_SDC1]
BO_ 2549088427 KN_SCC2: 8 SCC2
 SG_ SCC2_KompSchutz : 0|1@1+ (1,0) [0|1] "" Vector__XXX
 SG_ SCC2_Abschaltstufe : 1|1@1+ (1,0) [0|1] "" Vector__XXX
 SG_ SCC2_Transport_Mode : 2|1@1+ (1,0) [0|1] "" Vector__XXX
 SG_ SCC2_Nachlauftyp : 4|4@1+ (1,0) [0|15] ""  ZR_High
 SG_ SCC2_SNI : 8|8@1+ (1,0) [0|255] ""  ZR_High
 SG_ KN_SCC2_BusKnockOutTimer : 40|8@1+ (1,0) [0|254] "" Vector__XXX
 SG_ NM_SCC2_Wakeup : 48|8@1+ (1,0) [0|255] "" Vector__XXX
 SG_ NM_SCC2_Lokalaktiv : 61|1@1+ (1,0) [0|1] ""  ZR_High
 SG_ SCC2_KD_Fehler : 63|1@1+ (1,0) [0|1] ""  ZR_High

BO_ 2549088423 KN_SDC1: 8 SDC1
 SG_ SDC1_KompSchutz : 0|1@1+ (1,0) [0|1] "" Vector__XXX
 SG_ SDC1_Abschaltstufe : 1|1@1+ (1,0) [0|1] "" Vector__XXX
 SG_ SDC1_Transport_Mode : 2|1@1+ (1,0) [0|1] "" Vector__XXX
 SG_ SDC1_Nachlauftyp : 4|4@1+ (1,0) [0|15] ""  ZR_High
 SG_ SDC1_SNI : 8|8@1+ (1,0) [0|255] ""  ZR_High
 SG_ KN_SDC1_BusKnockOutTimer : 40|8@1+ (1,0) [0|254] "" Vector__XXX
 SG_ NM_SDC1_Wakeup : 48|8@1+ (1,0) [0|255] "" Vector__XXX
 SG_ NM_SDC1_Lokalaktiv : 61|1@1+ (1,0) [0|1] ""  ZR_High
 SG_ SDC1_KD_Fehler : 63|1@1+ (1,0) [0|1] ""  ZR_High

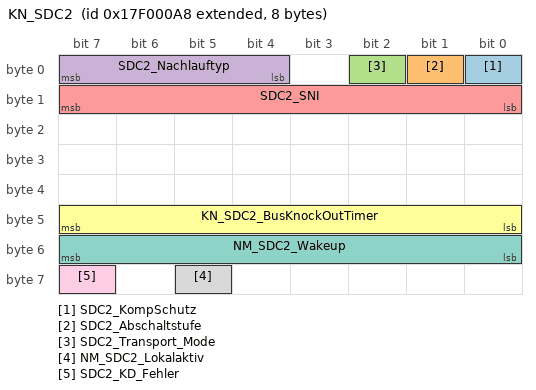
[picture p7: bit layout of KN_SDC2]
BO_ 2549088424 KN_SDC2: 8 SDC2
 SG_ SDC2_KompSchutz : 0|1@1+ (1,0) [0|1] "" Vector__XXX
 SG_ SDC2_Abschaltstufe : 1|1@1+ (1,0) [0|1] "" Vector__XXX
 SG_ SDC2_Transport_Mode : 2|1@1+ (1,0) [0|1] "" Vector__XXX
 SG_ SDC2_Nachlauftyp : 4|4@1+ (1,0) [0|15] ""  ZR_High
 SG_ SDC2_SNI : 8|8@1+ (1,0) [0|255] ""  ZR_High
 SG_ KN_SDC2_BusKnockOutTimer : 40|8@1+ (1,0) [0|254] "" Vector__XXX
 SG_ NM_SDC2_Wakeup : 48|8@1+ (1,0) [0|255] "" Vector__XXX
 SG_ NM_SDC2_Lokalaktiv : 61|1@1+ (1,0) [0|1] ""  ZR_High
 SG_ SDC2_KD_Fehler : 63|1@1+ (1,0) [0|1] ""  ZR_High

BO_TX_BU_ 2583884293 : ZR_Entry,ZR_High,ZR_High_Korea,ZR_High_TT3,ZR_MIB_OPTION_ab_Gen3,ZR_MIB_TOP_ab_Gen3,ZR_Standard;
BO_TX_BU_ 2583885061 : ZR_High,ZR_MIB_OPTION_ab_Gen3,ZR_MIB_TOP_ab_Gen3,ZR_Standard;
BO_TX_BU_ 2583887365 : ZR_High,ZR_MIB_TOP_ab_Gen3;
BO_TX_BU_ 987 : ZR_MIB_TOP_ab_Gen3,ZR_High,ZR_High_Korea;
BO_TX_BU_ 2549674355 : ABT_1_MIB_ab_Gen3,ABT_1_MQB;
BO_TX_BU_ 2549773297 : ZR_High,ZR_High_Korea,ZR_High_TT3,ZR_MIB_OPTION_ab_Gen3,ZR_MIB_TOP_ab_Gen3,ZR_Standard;
BO_TX_BU_ 2549773296 : ZR_Entry,ZR_High,ZR_High_Korea,ZR_High_TT3,ZR_MIB_OPTION_ab_Gen3,ZR_MIB_TOP_ab_Gen3,ZR_Standard;
BO_TX_BU_ 2549773298 : ZR_Entry,ZR_High,ZR_High_Korea,ZR_High_TT3,ZR_MIB_OPTION_ab_Gen3,ZR_MIB_TOP_ab_Gen3,ZR_Standard;
BO_TX_BU_ 2549773301 : ZR_High,ZR_MIB_OPTION_ab_Gen3,ZR_MIB_TOP_ab_Gen3,ZR_Standard;
BO_TX_BU_ 2549808755 : ZR_High,ZR_MIB_TOP_ab_Gen3;
BO_TX_BU_ 2549773302 : ZR_High,ZR_MIB_OPTION_ab_Gen3,ZR_MIB_TOP_ab_Gen3,ZR_Standard;
BO_TX_BU_ 2549642225 : ZR_High,ZR_High_Korea,ZR_High_TT3,ZR_MIB_OPTION_ab_Gen3,ZR_MIB_TOP_ab_Gen3,ZR_Standard;
BO_TX_BU_ 2549805427 : ABT_1_MIB_ab_Gen3,ABT_1_MQB;
BO_TX_BU_ 2549642224 : ZR_Entry,ZR_High,ZR_High_Korea,ZR_High_TT3,ZR_MIB_OPTION_ab_Gen3,ZR_MIB_TOP_ab_Gen3,ZR_Standard;
BO_TX_BU_ 2549642226 : ZR_Entry,ZR_High,ZR_High_Korea,ZR_High_TT3,ZR_MIB_OPTION_ab_Gen3,ZR_MIB_TOP_ab_Gen3,ZR_Standard;
BO_TX_BU_ 2549642229 : ZR_High,ZR_MIB_OPTION_ab_Gen3,ZR_MIB_TOP_ab_Gen3,ZR_Standard;
BO_TX_BU_ 2549642238 : ZR_High,ZR_MIB_TOP_ab_Gen3;
BO_TX_BU_ 2549642230 : ZR_High,ZR_MIB_OPTION_ab_Gen3,ZR_MIB_TOP_ab_Gen3,ZR_Standard;
BO_TX_BU_ 1792 : ZR_Entry,ZR_High,ZR_High_Korea,ZR_High_TT3,ZR_MIB_OPTION_ab_Gen3,ZR_MIB_TOP_ab_Gen3,ZR_Standard;
BO_TX_BU_ 2549874853 : ZR_Entry,ZR_High,ZR_High_Korea,ZR_High_TT3,ZR_MIB_OPTION_ab_Gen3,ZR_MIB_TOP_ab_Gen3,ZR_Standard;
BO_TX_BU_ 2549874854 : ZR_High,ZR_High_Korea,ZR_MIB_OPTION_ab_Gen3,ZR_MIB_TOP_ab_Gen3,ZR_Standard;
BO_TX_BU_ 960 : ZR_Entry,ZR_High,ZR_High_Korea,ZR_High_TT3,ZR_MIB_OPTION_ab_Gen3,ZR_MIB_TOP_ab_Gen3,ZR_Standard;
CM_ SG_ 2589283759 DU3_LVDS_Splitter_Fehlerstatus "LVDS_Splitter_Fehlerstatus = 0 kein Fehler erkannt
LVDS_Splitter_Fehlerstatus = 1 SW Fehler erkannt
LVDS_Splitter_Fehlerstatus = 2 HW Fehler erkannt";
CM_ SG_ 2589283759 DU3_Betriebsdauer_min "Display Betriebsdauer Minutenanteil";
CM_ SG_ 2589283759 DU3_Betriebsdauer_std "Display Betriebsdauer Stundenanteil";
CM_ SG_ 2589283759 DU3_HintGrdBelKurzschl "Hintergrundbeleuchtung hat einen Kurzschluß.";
CM_ SG_ 2589283759 DU3_HintGrdBelUnterbr "Ueber Strommessungen, mindestens ein LED Strang unterbrochen.";
CM_ SG_ 2589283759 DU3_EEPROM_Fehler "EEPROM Defekt erkannt.";
CM_ SG_ 2589283759 DU3_SW_inkonsistent "SW_inkonsistent= 1 SW Status ist inkonsistent - Fehler
SW_inkonsistent = 0 kien Fehler - SW ist konsistent";
CM_ SG_ 2589283759 DU3_HDCP_Status "Aktueller HDCP Status";
CM_ SG_ 2589283759 DU3_LVDS_Status "LVDS_Lock= 1 Statussignal in der DU Ein valides Videosignal zum Anzeigen liegt an 
LVDS_Unlocked = 0 kein Videosignal liegt an";
CM_ SG_ 2589283759 DU3_ZR_Lenkerpos_Status "Im ABT gespeicherte Lenkradposition. Die Lenkradposition wird wie im Signal ZR_Lenkerposition gesendet nach einer Qualifizierungszeit von voraussichtlich 10 Botschaften übernommen.";
CM_ SG_ 2589283759 DU3_Touch_Fehlerstatus "Touch_Fehlerstatus = 0 kein Fehler erkannt
Touch_Fehlerstatus = 1 SW Fehler erkannt
Touch_Fehlerstatus = 2 HW Fehler erkannt";
CM_ SG_ 2589283759 DU3_Haptik_Fehlerstatus "Haptik_Fehlerstatus = 0 kein Fehler erkannt
Haptik_Fehlerstatus = 1 SW Fehler erkannt
Haptik_Fehlerstatus = 2 HW Fehler erkannt";
CM_ SG_ 2583753221 DU_1_SWDL_Req_Data "Softwaredownload über ISO TP.";
CM_ SG_ 2583884293 DU_1_SWDL_Resp_Data "Softwaredownload über ISO TP.";
CM_ SG_ 2583753989 DU_2_SWDL_Req_Data "Softwaredownload über ISO TP.";
CM_ SG_ 2583885061 DU_2_SWDL_Resp_Data "Softwaredownload über ISO TP.";
CM_ SG_ 2583756293 DU_3_SWDL_Req_Data "Softwaredownload über ISO TP.";
CM_ SG_ 2583887365 DU_3_SWDL_Resp_Data "Softwaredownload über ISO TP.";
CM_ SG_ 2583753733 DU_4_SWDL_Req_Data "Softwaredownload über ISO TP.";
CM_ SG_ 2583884805 DU_4_SWDL_Resp_Data "Softwaredownload über ISO TP.";
CM_ BO_ 1603 "ab MQB mit 8 Byte";
CM_ SG_ 1603 KBI_Einheit_Datum "Anzeigevariante des Datums";
CM_ SG_ 1603 KBI_Einheit_Druck "Einheit des Druckes";
CM_ SG_ 1603 KBI_Einheit_Streckenanz "Einheit der Streckenanzeige";
CM_ SG_ 1603 KBI_MFA_v_Einheit_02 "Einheit der Geschwindigkeit, die vom Fahrer im Car-Menü gewählt wurde. Veränderliche Grösse, im Gegensatz zur Einheit des Tachokranzes.

Redundant in der Einheiten_01 Botschaft definiert, um Konsistenz zur BAP-Festlegung zu haben.";
CM_ SG_ 1603 KBI_Einheit_Temp "Einheit der Temperatur";
CM_ SG_ 1603 KBI_Einheit_Uhrzeit "Anzeigevariante der Uhrzeit";
CM_ SG_ 1603 KBI_Einheit_Verbrauch "Einheit der Verbrauchs";
CM_ SG_ 1603 KBI_Einheit_Volumen "Einheit des Volumens";
CM_ SG_ 1603 KBI_Einheit_Verbrauch_elektr "Einheit elektrischer Verbrauch";
CM_ SG_ 1603 KBI_Einheit_Sprache "Siehe BAP-Datenfestlegung UnitMaster";
CM_ SG_ 1603 KBI_Einheit_Verbrauch_Gas "Unterscheidung zwischen M3/h und kg/h für Komfortverbrauchsberechnung.";
CM_ SG_ 1603 KBI_Einheit_Masse "Einheit der Masse (Verwendung z.B. ASTA)";
CM_ SG_ 278 ESP_10_CRC "Für MLB:
'Berechnung siehe Lastenheft 'Kommunikationsabsicherung für FlexRay und CAN''

Ab MQB und MLBevo:
'Berechnung siehe Lastenheft 'End-to-End Kommunikationsabsicherung''

Endwerte siehe Begleitdokument 'S-PDU Kennungsfolgen'

Wird im Projekt";
CM_ SG_ 278 ESP_10_BZ "Botschaftszähler

																											

																		   
													 

																											

																		   
																		

																		   
																		

Wird im Projekt D4 und D4Hybrid nicht verwendet!  Wird im D4 PA verwendet";
CM_ SG_ 278 ESP_QBit_Wegimpuls_VL "Qualifizierungsbit Wegimpulszähler VL

Wird im Projekt D4 und D4Hybrid nicht verwendet!  Wird im D4 PA verwendet";
CM_ SG_ 278 ESP_QBit_Wegimpuls_VR "Qualifizierungsbit Wegimpulszähler VR

Wird im Projekt D4 und D4Hybrid nicht verwendet!  Wird im D4 PA verwendet";
CM_ SG_ 278 ESP_QBit_Wegimpuls_HL "Qualifizierungsbit Wegimpulszähler HL

																											

Wird im Projekt D4 und D4Hybrid nicht verwendet!  Wird im D4 PA verwendet";
CM_ SG_ 278 ESP_QBit_Wegimpuls_HR "Qualifizierungsbit Wegimpulszähler HR

																											

Wird im Projekt D4 und D4Hybrid nicht verwendet!  Wird im D4 PA verwendet";
CM_ SG_ 278 ESP_Wegimpuls_VL "Wegimpulszähler VL.
Anzahl der Wegimpulse Vorderrad links (steigende und fallende Flanke)
Zähler läuft grundsätzlich vorwärts, auch bei Rückwärtsfahrt.
Nach SG-Reset ist immer, ohne Ausnahme, 1mal der Init Wert 1021 zu senden.

Wird im Projekt D4 und";
CM_ SG_ 278 ESP_Wegimpuls_VR "Wegimpulszähler VR.
Anzahl der Wegimpulse Vorderrad rechts (steigende und fallende Flanke)
Zähler läuft grundsätzlich vorwärts, auch bei Rückwärtsfahrt.
Nach SG-Reset ist immer, ohne Ausnahme, 1mal der Init Wert 1021 zu senden.

Wird im Projekt D4 un";
CM_ SG_ 278 ESP_Wegimpuls_HL "Wegimpulszähler HL.
Anzahl der Wegimpulse Hinterrad links (steigende und fallende Flanke)
Zähler läuft grundsätzlich vorwärts, auch bei Rückwärtsfahrt.
Nach SG-Reset ist immer, ohne Ausnahme, 1mal der Init Wert 1021 zu senden.

Wird im Projekt D4 und";
CM_ SG_ 278 ESP_Wegimpuls_HR "Wegimpulszähler HR.
Anzahl der Wegimpulse Hinterrad rechts (steigende und fallende Flanke)
Zähler läuft grundsätzlich vorwärts, auch bei Rückwärtsfahrt.
Nach SG-Reset ist immer, ohne Ausnahme, 1mal der Init Wert 1021 zu senden.

Wird im Projekt D4 un";
CM_ SG_ 278 ESP_VL_Fahrtrichtung "Drehrichtung Rad VL

Weiterführende Informationen im Lastenheft spezifiziert und in der entsprechenden Fachabteilung zu erfragen.

Wird im Projekt D4 und D4Hybrid nicht verwendet!  Wird im D4 PA verwendet";
CM_ SG_ 278 ESP_VR_Fahrtrichtung "Drehrichtung Rad VR

Weiterführende Informationen im Lastenheft spezifiziert und in der entsprechenden Fachabteilung zu erfragen.

Wird im Projekt D4 und D4Hybrid nicht verwendet!  Wird im D4 PA verwendet";
CM_ SG_ 278 ESP_HL_Fahrtrichtung "Drehrichtung Rad HL

Weiterführende Informationen im Lastenheft spezifiziert und in der entsprechenden Fachabteilung zu erfragen.

Wird im Projekt D4 und D4Hybrid nicht verwendet!  Wird im D4 PA verwendet";
CM_ SG_ 278 ESP_HR_Fahrtrichtung "Drehrichtung Rad HR

Weiterführende Informationen im Lastenheft spezifiziert und in der entsprechenden Fachabteilung zu erfragen.
																	

Wird im Projekt D4 und D4Hybrid nicht verwendet!  Wird im D4 PA verwendet";
CM_ BO_ 1629 "neu im MQB";
CM_ SG_ 1629 ESP_20_CRC "Für MLB:
'Berechnung siehe Lastenheft 'Kommunikationsabsicherung für FlexRay und CAN''

Ab MQB und MLBevo:
'Berechnung siehe Lastenheft 'End-to-End Kommunikationsabsicherung''

Endwerte siehe Begleitdokument 'S-PDU Kennungsfolgen'";
CM_ SG_ 1629 BR_Systemart "Identifikation des verbauten Bremssystems

Dient dem Kombi zur Plausibilisierung";
CM_ SG_ 1629 ESP_SpannungsAnf_02 "Forderung des ESP-SG's zur Spannungsanhebung.";
CM_ SG_ 1629 ESP_Zaehnezahl "Konstanter Wert der Zähnezahl des verwendeten Impulsrades wird ausgegeben, jeder Empfänger der Wegimpulse muss die Zähnezahl einlesen, um eine volle Umdrehung des Rades zu erkennen. 

Weiterführende Informationen im Lastenheft spezifiziert und in der en";
CM_ SG_ 1629 ESP_Charisma_FahrPr "MLBevo: Aktuelles Fahrprogramm des Charisma-Teilnehmers (siehe Systemlastenheft Drive Select)
MQB: Istwert der Kennlinie (siehe Systemlastenheft MQB FPA)";
CM_ SG_ 1629 ESP_Charisma_Status "Systemstatus des Charismateilnehmers

Wert 0x3 ist nur für Fahrzeuge ab MQB relevant";
CM_ SG_ 1629 ESP_Wiederstart_Anz_01 "Dieses Signal gibt die detaillierte Begründung für einen Wiederstart vom Bremsensteuergerät an. ";
CM_ SG_ 1629 ESP_Wiederstart_Anz_02 "Dieses Signal gibt die detaillierte Begründung für einen Wiederstart vom Bremsensteuergerät an. ";
CM_ SG_ 1629 ESP_Wiederstart_Anz_03 "Dieses Signal gibt die detaillierte Begründung für einen Wiederstart vom Bremsensteuergerät an. ";
CM_ SG_ 1629 ESP_Wiederstart_Anz_04 "Dieses Signal gibt die detaillierte Begründung für einen Wiederstart vom Bremsensteuergerät an.";
CM_ SG_ 1629 ESP_Stoppverbot_Anz_01 "Dieses Signal gibt die detaillierte Begründung für ein Stoppverbot vom Bremsensteuergerät an.";
CM_ SG_ 1629 ESP_Stoppverbot_Anz_02 "Dieses Signal gibt die detaillierte Begründung für ein Stoppverbot vom Bremsensteuergerät an.";
CM_ SG_ 1629 ESP_Stoppverbot_Anz_03 "Dieses Signal gibt die detaillierte Begründung für ein Stoppverbot vom Bremsensteuergerät an.";
CM_ SG_ 1629 ESP_Stoppverbot_Anz_04 "Dieses Signal gibt die detaillierte Begründung für ein Stoppverbot vom Bremsensteuergerät an.";
CM_ SG_ 1629 ESP_Stoppverbot_Anz_05 "Dieses Signal gibt die detaillierte Begründung für ein Stoppverbot vom Bremsensteuergerät an.";
CM_ SG_ 1629 ESP_Stoppverbot_Anz_06 "Dieses Signal gibt die detaillierte Begründung für ein Stoppverbot vom Bremsensteuergerät an.";
CM_ SG_ 1629 ESP_Stoppverbot_Anz_07 "Dieses Signal gibt die detaillierte Begründung für ein Stoppverbot vom Bremsensteuergerät an.";
CM_ SG_ 1629 ESP_Stoppverbot_Anz_Std "Dieses Signal gibt die detaillierte Begründung für ein Stoppverbot vom Bremsensteuergerät an.";
CM_ SG_ 1629 ESP_Dachrelingsensor "Erkennung auf Verbau des Dachrelingsensors und Dachquerträger.";
CM_ SG_ 1629 ESP_Stoppverbot_Anz_08 "Dieses Signal gibt die detaillierte Begründung für ein Stoppverbot vom Bremsensteuergerät an.";
CM_ SG_ 1629 HDC_Charisma_FahrPr "MLBevo: Aktuelles Fahrprogramm des Charisma-Teilnehmers (siehe Systemlastenheft Drive Select)
MQB: Istwert der Kennlinie (siehe Systemlastenheft MQB FPA)";
CM_ SG_ 1629 HDC_Charisma_Status "Systemstatus des Charismateilnehmers

Wert 0x3 ist nur für Fahrzeuge ab MQB relevant";
CM_ SG_ 1629 BR_QBit_Reifenumfang "Gesetzt bei Ersatzwert, Init oder Fehler.";
CM_ SG_ 1629 BR_Reifenumfang "Mittlerer Radumfang gerechnet in Millimeter.
Von der Bremse plausibilisierter Wert (Kopie von KBI_Reifenumfang wenn dieser plausibel) oder Ersatzwert aus Bremse wenn KBI_Reifenumfang unplausibel. Bitte das QBit beachten!

Im MEB wird das Signal KBI_Rei";
CM_ BO_ 795 "neu für MQB wg. Absicherung
Entstanden aus ESP_04";
CM_ SG_ 795 ESP_24_CRC "Für MLB:
'Berechnung siehe Lastenheft 'Kommunikationsabsicherung für FlexRay und CAN''

Ab MQB und MLBevo:
'Berechnung siehe Lastenheft 'End-to-End Kommunikationsabsicherung''

Endwerte siehe Begleitdokument 'S-PDU Kennungsfolgen'";
CM_ SG_ 795 ESP_Lampe "Zustand der Fahrdynamikregelungslampe (MLB: ASR und/oder ESP, MQB: nur ESP)

Weiterführende Informationen im Lastenheft spezifiziert und in der entsprechenden Fachabteilung zu erfragen.";
CM_ SG_ 795 ABS_Lampe "Sicherheitswarnlampe

											
  
Weiterführende Informationen im Lastenheft spezifiziert und in der entsprechenden Fachabteilung zu erfragen.";
CM_ SG_ 795 BK_Lampe_02 "Sicherheitswarnlampe signalisiert EBV-Ausfall

MQB: wird auch bei HBV-Ausfall verwendet.

Weiterführende Informationen im Lastenheft spezifiziert und in der entsprechenden Fachabteilung zu erfragen.";
CM_ SG_ 795 TC_Lampe "M-ABS Lampe (separate Lampe für M-ABS-Systeme Markt Brasilien)
								   
																		   
				   
																			   
																		
									 
																								  

Weiterführende Informationen im Lastenheft spezifiziert und in der entsprechenden Fachabteilung zu erfragen.";
CM_ SG_ 795 ESP_m_Raddrehz "Radumdrehungen pro Sekunde sind Eingangsgröße für die Geschwindigkeitsberechnung im Kombi. Aus dieser Raddrehzahl und dem Radumfang wird die Fahrzeuggeschwindigkeit errechnet.

MLB: Exklusiver Empfänger ist das Kombiinstrument!
MQB: Bei Frontantrieb un";
CM_ SG_ 795 ESP_Textanzeigen_03 "Textanzeigen der Fahrdynamikregelung im Kombiinstrument

Weiterführende Informationen im Lastenheft spezifiziert und in der entsprechenden Fachabteilung zu erfragen.

Der Signalwert 24 wird nur im BY736 verwendet.";
CM_ SG_ 795 ESP_Meldungen "ESP sendet im Hinweis- /Störungsfall an das Kombi Informationen zum Anzeigen

Weiterführende Informationen im Lastenheft spezifiziert und in der entsprechenden Fachabteilung zu erfragen.
Ergänzender Hinweis:
1 = Autohold_Hinweis_1 (Anfahrassistent: nu";
CM_ SG_ 795 ESP_Wegimp_VA "Weiterführende Informationen im Lastenheft spezifiziert und in der entsprechenden Fachabteilung zu erfragen.

MLB: Die Wegimpulse Vorderachse sind die gemittelten Werte (reine mathematische Operation: Addition und Division durch zwei, keine Filterung) d";
CM_ SG_ 795 ESP_Fehlerstatus_Wegimp "Weiterführende Informationen im Lastenheft spezifiziert und in der entsprechenden Fachabteilung zu erfragen.
																		   
																						

MLB: Fehler wird gesetzt, wenn beide ESP-Drehzahlfühler an der Vorderachse defekt sind.

MQB: Fehler wird gesetzt, wenn beide Raddrehzahlfühl";
CM_ SG_ 795 ESP_Wegimp_Ueberlauf "Der Wegimpulszähler ist pro Zündungslauf mindestens einmal übergelaufen

Weiterführende Informationen im Lastenheft spezifiziert und in der entsprechenden Fachabteilung zu erfragen.";
CM_ SG_ 795 ESP_QBit_Wegimp_VA "Gesetzt bei Ersatzwert, Init oder Fehler.";
CM_ SG_ 795 ESP_HDC_FktLampe "Funktionslampe Bergabfahrassistent.
(Sender blinkt mit dem Bit 3,3Hz)";
CM_ SG_ 795 ESP_Off_Lampe "Bit zur Ansteuerung der separaten ESP-off-Lampe im Kombi (Gesetzesforderung USA)

MLB:
Verwendung/Bedienung ab D4";
CM_ SG_ 795 ESP_HDC_Regelgeschw "Verwendung/Bedienung nur im AU57x Allroad:
HDC-Geschwindigkeit
Dient der Anzeige der HDC-Geschwindigkeit und eines Bergabfahrsymbols im Kombi.
HDC-Standby wird gesetzt sobald der Fahrer den HDC-Taster aktiviert hat.
Bei HDC-Off oder während der Initia";
CM_ SG_ 795 ESP_BKV_Warnung "ESP sendet im Hinweis- /Störungsfall an das Kombi Informationen zum Anzeigen (Text + Akustik)

Im MQB wird dieses Signal nicht unterstützt!
";
CM_ BO_ 2589283409 "Statusbotschaft der ExBox.";
CM_ SG_ 2589283409 EB_Jahr "von der ExBox gesendete Jahresinformation";
CM_ SG_ 2589283409 EB_Monat "0x0D, 0xF =  Werte ungültig
0x0E = reserviert (nur VW)";
CM_ SG_ 2589283409 EB_Tag "0x0: reserviert bei VW";
CM_ SG_ 2589283409 EB_Stunde "0x18 - 0x1F = Werte ungültig";
CM_ SG_ 2589283409 EB_Minute "0x3C- 0x3f = Werte ungültig";
CM_ SG_ 2589283409 EB_Sekunde "0x3C- 0x3f = Werte ungültig";
CM_ SG_ 2589283409 EB_Zeit_gueltig "Gültigkeit der Zeitangabe vom GPS Empfänger";
CM_ BO_ 986 "Fahrwerk, Extended -> Komfort, Infotainment";
CM_ SG_ 986 ESP_HDC_Standby "Verwendung/Bedienung im MQB und AU57x Allroad:
Flag wird vom ESP gesetzt, wenn über den HDC-Taster die HDC-Funktion eingeschalten wurde";
CM_ SG_ 986 ECD_Bremslicht "Bremslichtansteuerung durch ECD-Funktion";
CM_ SG_ 986 EPB_Status "Gibt den Zustand der EPB-Aktuatoren an.

Nur VW526/PAG E2: Wert 0x3 bedeutet 'unbekannt'

";
CM_ SG_ 986 ESP_QBit_v_Signal "Geschwindigkeit wird vom ABS/ASR oder ESP aus Ersatzwerten errechnet, wenn Bit gesetzt ist. Güte des Signals ist verändert.";
CM_ SG_ 986 ABS_Bremsung "Antiblockiersystem, Bit zeigt auch Druckabbau an (z.B. ESP hat zuviel Druck aufgebaut oder ungebremste Regelung auf Bahnübergang)
Weiterführende Informationen im Lastenheft spezifiziert und in der entsprechenden Fachabteilung zu erfragen.";
CM_ SG_ 986 ESP_Eingriff "Eingriff des Fahrdynamikreglers";
CM_ SG_ 986 Kamera_FSH_aktiv "Bei aktivierter (lokaler) Frontscheibenheizung wird die Scheibentemperaturmessung des Klimafeuchtesensors beeinflusst. Über das Signal wird dem Klima-SG mitgeteilt, dass die lokale Scheibenheizung aktiviert ist, um entsprechende Korrekturwerte bei der Sch";
CM_ SG_ 986 EPB_Pedalweg_Kuppl "Signal entspricht Tastverhältnis des PWM. Gesamtweg Kupplungspedal 10% bis 90%, damit zu erwartende Werte 25 bis 225. 25 bei Kupplungspedal nicht getreten, 225 bei Kupplungspedal voll durchgetreten.
2% Toleranz wird im Wertebereich ermöglicht (8%-92%).
";
CM_ SG_ 986 ESP_v_Signal "Geschwindigkeitssignal vom ABS/ASR oder ESP. Mittelwert der angetriebenen Räder.
Bei MSR oder ABS Eingriffen wird die ABS-Referenzgeschwindigkeit für >= 200ms eingespiegelt (Zeit wird mit Aktiv-Flanke der Funktionsbits getriggert)

MQB: Bei Frontantrie";
CM_ SG_ 986 LWI_QBit_Lenkradwinkel "Das QBit wird auch bei nicht abgeglichenem Lenkradwinkelsensor gesetzt";
CM_ SG_ 986 LWI_VZ_Lenkradwinkel "Vorzeichen Lenkradwinkel gemäss DIN70000; 
Nullstellung = +0";
CM_ SG_ 986 LWI_Lenkradwinkel "Wertebereich = +/- 800 Grad
Auflösung = 0,1 Grad
ACHTUNG: spezifizierte Interne Auflösung des Sensors beträgt aber nur Schrittweite 0,5 Grad!

Hinweis:
MLB: Zusätzlich gestellte Winkel bei Dynamiklenkung beachten !
MQB: Nicht konstante Lenkübersetzu";
CM_ SG_ 986 PH_Anf_Audioabsenkung "Es gibt zwei unterschiedliche Nachlauftimer für dieses Bit:
1. normale Funktion
2. Demotonausgabe";
CM_ SG_ 986 PH_Systemzustand "Aktivierungsursache wird für die Dauer der Aktivierung gemeldet.
Im Fehlerfall bei atkviem System wechselt das Signal auf '7'
(siehe auch 'Abschaltursache')";
CM_ SG_ 986 PH_Taster "Taster Status (für RVC/TopView)";
CM_ SG_ 986 ESP_MKB_Abbruch_Geschw "Im Falle einer Multikollisionsbremsung teilt das ESP den Abbruch der MKB aufgrund der unteren Geschwindigkeitsschwelle mit.";
CM_ SG_ 986 PLA_Anf_Aufschaltung_RVC "Anforderung der Aufschaltung RVC durch PLA";
CM_ BO_ 987 "Komfort -> Antrieb, Extended, Fahrwerk, Infotainment";
CM_ SG_ 987 ZV_verriegelt_extern_soll "Sollzustand: Verriegelung Fahrzeug aussen
";
CM_ SG_ 987 BH_Lichthupe "Betaetigung Lichthupe
";
CM_ SG_ 987 WFS_Klemmenfreigabe "Freigabe von der WFS zum Einschalten der Klemme 15 und Klemme S";
CM_ SG_ 987 ZV_Tankklappe_offen "Öffnungsstatus der Tankklappe";
CM_ SG_ 987 AAG_Anhaenger_abgesteckt "Anhaenger wurde bei Kl. 15 aus abgesteckt";
CM_ SG_ 987 BCM1_LDS_Stellung "Das Signal wird vom AFS / LWR Steuergerät empfangen und dient der Verifizierung der Lichtdrehschalterstellung. Intelligente Lichtfunktionen wie dyn. KL und gleitende Leuchtweite (GLW) nur bei LDS = 'AUTO'.";
CM_ SG_ 987 VS_Verdeck_Anf "



																				 
														 
																								  
											
																				  
  
																																																											  
												  
																								  
  
															   
																																														 
																			 
																																						   
																								 
													  
  
													   
  
											   
";
CM_ SG_ 987 VS_VD_entriegelt "

";
CM_ SG_ 987 ZV_HFS_offen "gespiegeltes Bit HFS_Tuer_geoeffnet TSG_HFS_1 Botschaft";
CM_ SG_ 987 ZV_HBFS_offen "gespiegeltes Bit HBFS_Tuer_geoeffnet TSG_HBFS_1 Botschaft";
CM_ SG_ 987 VS_VD_offen_ver "Zustand des Verdecks verriegelt und offen";
CM_ SG_ 987 VS_VD_zu_ver "
";
CM_ SG_ 987 ZV_BT_offen "gespiegeltes Bit BT_Tuer_geoeffnet TSG_BT_1 Botschaft";
CM_ SG_ 987 BCM1_Rueckfahrlicht_Schalter "Rückfahrlichtschalter
ab MQB/ MLBevo: Die Ganginformation wird unentprellt übertragen, im AT-Getriebe wird evtl. kurzzeitig der R-Gang angezeigt. Eine Entprellung muß im Empfänger erfolgen (typisch 400ms).";
CM_ SG_ 987 ZV_FT_offen "gespiegeltes Bit FT_Tuer_geoeffnet TSG_FT_1 Botschaft";
CM_ SG_ 987 Wischer_vorne_aktiv "Status: Wischer vorne ";
CM_ SG_ 987 AAG_Anhaenger_erkannt "Erkennung Anhaenger ";
CM_ SG_ 987 BCM1_MH_Schalter "Motorhaubenkontakt";
CM_ SG_ 987 ZV_HD_offen "Status Heckdeckel
";
CM_ SG_ 987 Waschen_vorne_aktiv "Status: Waschen vorne aktiv 
";
CM_ SG_ 987 KL_Thermomanagement "Stufen des Thermomanagements;
Bei Klemme 15 AUS und erkannten Timeout zum Klimabedienteil (z.B. Klimabedienteil während des Motorsteuergeräte-Kommunikations-Nachlaufs bereits im NM-Zustand ¿Bus Sleep¿)
erfolgt keine Ansteuerung der Wasserpumpe durch die";
CM_ SG_ 987 WFS_Schluessel_Fahrberecht "Schlüsselnummer Fahrberechtigung
0 = ungueltig, xxxx = Schluessel-Nr.";
CM_ SG_ 987 BCM_Rueckfahrlicht_Anf "Anforderung Rückfahrlicht (Sollzustand). 
Das Signal wird entprellt (typisch 400ms) und bei KL15EIN gesendet. Das Signal ist unabhängig von der Position des Heckdeckels (kein Überhitzungsschutz).";
CM_ SG_ 987 WWSs_01_alt "Veraltet Bit für die LIN-Botschaft WWSs_01.

Betroffene Signale:

Wischer_vorne_aktiv";
CM_ SG_ 987 BCM_Tankklappensteller_Fehler "Fehler: nicht Funktionalität des Tankklappenstellers";
CM_ SG_ 987 AAG_LED_aktiv "Dieses Signal sendet der Beleuchtungsart des Anhängers (LED oder Lampe)
Bei LED aktiv erfolgt kein Kaltüberwachung";
CM_ SG_ 987 ZV_verriegelt_soll "Fahrzeug Gesamtverriegelungsstatus Sollzustand für Ladestecker- und Ladeklappenverriegelung. ";
CM_ SG_ 987 ZV_Schluessel_Zugang "aktuelle Funkschlüsselnummer";
CM_ SG_ 987 WFS_ID_Geb_autorisiert_in_Kl15 "Authorisierung des Schlüssels im aktiven Klemme-15-Zyklus";
CM_ SG_ 987 BH_Fernlicht "Betaetigung Fernlicht
";
CM_ SG_ 987 BH_Blinker_li "Blinkerhebel Richtung links
";
CM_ SG_ 987 BH_Blinker_re "Blinkerhebel Richtung rechts
";
CM_ SG_ 987 BCM1_OBD_FStatus_ATemp "Fehlerstatus Umgebungstemperatursensor (OBD relevanter Sensor)
";
CM_ SG_ 987 BCM1_Aussen_Temp_ungef "ungefilterter Wert des Aussentemperatursensors
																
																
																				
";
CM_ BO_ 2589284280 "HDCP Status Botschaft DU1";
CM_ SG_ 2589284280 DU1_KSV_Value_1 "Aktueller KSV Wert (Key selection vector)";
CM_ SG_ 2589284280 DU1_KSV_Value_2 "Aktueller KSV Wert (Key selection vector)";
CM_ SG_ 2589284280 DU1_HDCP_Auth_Status_Out_1 "Authentifizierungsstatus zwischen Sendegerät und angeschlossenes Gerät auf FPD Link Out 1";
CM_ SG_ 2589284280 DU1_HDCP_Auth_Status_Out_2 "Authentifizierungsstatus zwischen Sendegerät und angeschlossenes Gerät auf FPD Link Out 2";
CM_ SG_ 2589284280 DU1_HDCP_Auth_Status_Out_3 "Authentifizierungsstatus zwischen Sendegerät und angeschlossenes Gerät auf FPD Link Out 3";
CM_ SG_ 2589284280 DU1_HDCP_Auth_Status_Out_4 "Authentifizierungsstatus zwischen Sendegerät und angeschlossenes Gerät auf FPD Link Out 4";
CM_ SG_ 2589284280 DU1_HDCP_Auth_Status_Out_5 "Authentifizierungsstatus zwischen Sendegerät und angeschlossenes Gerät auf FPD Link Out 5";
CM_ SG_ 2589284280 DU1_HDCP_Auth_Status_Out_6 "Authentifizierungsstatus zwischen Sendegerät und angeschlossenes Gerät auf FPD Link Out 6";
CM_ SG_ 2589284280 DU1_HDCP_Auth_Status_Out_7 "Authentifizierungsstatus zwischen Sendegerät und angeschlossenes Gerät auf FPD Link Out 7";
CM_ SG_ 2589284280 DU1_HDCP_Auth_Status_Out_8 "Authentifizierungsstatus zwischen Sendegerät und angeschlossenes Gerät auf FPD Link Out 8";
CM_ BO_ 2589284281 "HDCP Status Botschaft DU2";
CM_ SG_ 2589284281 DU2_KSV_Value_1 "Aktueller KSV Wert (Key selection vector)";
CM_ SG_ 2589284281 DU2_KSV_Value_2 "Aktueller KSV Wert (Key selection vector)";
CM_ SG_ 2589284281 DU2_HDCP_Auth_Status_Out_1 "Authentifizierungsstatus zwischen Sendegerät und angeschlossenes Gerät auf FPD Link Out 1";
CM_ SG_ 2589284281 DU2_HDCP_Auth_Status_Out_2 "Authentifizierungsstatus zwischen Sendegerät und angeschlossenes Gerät auf FPD Link Out 2";
CM_ SG_ 2589284281 DU2_HDCP_Auth_Status_Out_3 "Authentifizierungsstatus zwischen Sendegerät und angeschlossenes Gerät auf FPD Link Out 3";
CM_ SG_ 2589284281 DU2_HDCP_Auth_Status_Out_4 "Authentifizierungsstatus zwischen Sendegerät und angeschlossenes Gerät auf FPD Link Out 4";
CM_ SG_ 2589284281 DU2_HDCP_Auth_Status_Out_5 "Authentifizierungsstatus zwischen Sendegerät und angeschlossenes Gerät auf FPD Link Out 5";
CM_ SG_ 2589284281 DU2_HDCP_Auth_Status_Out_6 "Authentifizierungsstatus zwischen Sendegerät und angeschlossenes Gerät auf FPD Link Out 6";
CM_ SG_ 2589284281 DU2_HDCP_Auth_Status_Out_7 "Authentifizierungsstatus zwischen Sendegerät und angeschlossenes Gerät auf FPD Link Out 7";
CM_ SG_ 2589284281 DU2_HDCP_Auth_Status_Out_8 "Authentifizierungsstatus zwischen Sendegerät und angeschlossenes Gerät auf FPD Link Out 8";
CM_ BO_ 2589284283 "HDCP Status Botschaft DU3";
CM_ SG_ 2589284283 DU3_KSV_Value_1 "Aktueller KSV Wert (Key selection vector). Teil 1";
CM_ SG_ 2589284283 DU3_KSV_Value_2 "Aktueller KSV Wert (Key selection vector). Teil 2";
CM_ SG_ 2589284283 DU3_HDCP_Auth_Status_Out_1 "Authentifizierungsstatus zwischen Sendegerät und angeschlossenes Gerät auf FPD Link Out 1";
CM_ SG_ 2589284283 DU3_HDCP_Auth_Status_Out_2 "Authentifizierungsstatus zwischen Sendegerät und angeschlossenes Gerät auf FPD Link Out 2";
CM_ SG_ 2589284283 DU3_HDCP_Auth_Status_Out_3 "Authentifizierungsstatus zwischen Sendegerät und angeschlossenes Gerät auf FPD Link Out 3";
CM_ SG_ 2589284283 DU3_HDCP_Auth_Status_Out_4 "Authentifizierungsstatus zwischen Sendegerät und angeschlossenes Gerät auf FPD Link Out 4";
CM_ SG_ 2589284283 DU3_HDCP_Auth_Status_Out_5 "Authentifizierungsstatus zwischen Sendegerät und angeschlossenes Gerät auf FPD Link Out 5";
CM_ SG_ 2589284283 DU3_HDCP_Auth_Status_Out_6 "Authentifizierungsstatus zwischen Sendegerät und angeschlossenes Gerät auf FPD Link Out 6";
CM_ SG_ 2589284283 DU3_HDCP_Auth_Status_Out_7 "Authentifizierungsstatus zwischen Sendegerät und angeschlossenes Gerät auf FPD Link Out 7";
CM_ SG_ 2589284283 DU3_HDCP_Auth_Status_Out_8 "Authentifizierungsstatus zwischen Sendegerät und angeschlossenes Gerät auf FPD Link Out 8";
CM_ SG_ 2549674355 HID_ABT_1_ZR_Req_Data "Human Interface Device Kommunikation über ISO TP";
CM_ SG_ 2549773297 HID_ABT_1_ZR_Resp_Data "Human Interface Device Kommunikation über ISO TP";
CM_ SG_ 2549674099 HID_BT_1_ZR_Req_Data "Human Interface Device Kommunikation über ISO TP.";
CM_ SG_ 2549773296 HID_BT_1_ZR_Resp_Data "Human Interface Device Kommunikation über ISO TP.";
CM_ SG_ 2549674611 HID_DU_1_ZR_Req_Data "Human Interface Device Kommunikation über ISO TP.";
CM_ SG_ 2549773298 HID_DU_1_ZR_Resp_Data "Human Interface Device Kommunikation über ISO TP.";
CM_ SG_ 2549675379 HID_DU_2_ZR_Req_Data "Human Interface Device Kommunikation über ISO TP.";
CM_ SG_ 2549773301 HID_DU_2_ZR_Resp_Data "Human Interface Device Kommunikation über ISO TP.";
CM_ SG_ 2549677683 HID_DU_3_ZR_Req_Data "Human Interface Device Kommunikation über ISO TP";
CM_ SG_ 2549808755 HID_DU_3_ZR_Resp_Data "Human Interface Device Kommunikation über ISO TP";
CM_ SG_ 2549675123 HID_DU_4_ZR_Req_Data "Human Interface Device Kommunikation über ISO TP";
CM_ SG_ 2549773300 HID_DU_4_ZR_Resp_Data "Human Interface Device Kommunikation über ISO TP";
CM_ SG_ 2549675635 HID_LSR_1_ZR_Req "Human Interface Device Kommunikation über ISO TP.";
CM_ SG_ 2549773302 HID_LSR_1_ZR_Resp "Human Interface Device Kommunikation über ISO TP.";
CM_ SG_ 2549656179 HID_SCC1_ZR_Req_Data "Human Interface Device Kommunikation über ISO TP.";
CM_ SG_ 2549787251 HID_SCC1_ZR_Resp_Data "Human Interface Device Kommunikation über ISO TP.";
CM_ SG_ 2549656435 HID_SCC2_ZR_Req_Data "Human Interface Device Kommunikation über ISO TP.";
CM_ SG_ 2549787507 HID_SCC2_ZR_Resp_Data "Human Interface Device Kommunikation über ISO TP.";
CM_ SG_ 2549655411 HID_SDC1_ZR_Req_Data "Human Interface Device Kommunikation über ISO TP.";
CM_ SG_ 2549786483 HID_SDC1_ZR_Resp_Data "Human Interface Device Kommunikation über ISO TP.";
CM_ SG_ 2549655667 HID_SDC2_ZR_Req_Data "Human Interface Device Kommunikation über ISO TP.";
CM_ SG_ 2549786739 HID_SDC2_ZR_Resp_Data "Human Interface Device Kommunikation über ISO TP.";
CM_ SG_ 2549642225 HID_ZR_ABT_1_Req_Data "Human Interface Device Kommunikation über ISO TP";
CM_ SG_ 2549805427 HID_ZR_ABT_1_Resp_Data "Human Interface Device Kommunikation über ISO TP";
CM_ SG_ 2549642224 HID_ZR_BT_1_Req_Data "Human Interface Device Kommunikation über ISO TP.";
CM_ SG_ 2549805171 HID_ZR_BT_1_Resp_Data "Human Interface Device Kommunikation über ISO TP.";
CM_ SG_ 2549642226 HID_ZR_DU_1_Req_Data "Human Interface Device Kommunikation über ISO TP.";
CM_ SG_ 2549805683 HID_ZR_DU_1_Resp_Data "Human Interface Device Kommunikation über ISO TP.";
CM_ SG_ 2549642229 HID_ZR_DU_2_Req_Data "Human Interface Device Kommunikation über ISO TP.";
CM_ SG_ 2549806451 HID_ZR_DU_2_Resp_Data "Human Interface Device Kommunikation über ISO TP.";
CM_ SG_ 2549642238 HID_ZR_DU_3_Req_Data "Human Interface Device Kommunikation über ISO TP";
CM_ SG_ 2549773310 HID_ZR_DU_3_Resp_Data "Human Interface Device Kommunikation über ISO TP";
CM_ SG_ 2549642228 HID_ZR_DU_4_Req_Data "Human Interface Device Kommunikation über ISO TP";
CM_ SG_ 2549806195 HID_ZR_DU_4_Resp_Data "Human Interface Device Kommunikation über ISO TP";
CM_ SG_ 2549642230 HID_ZR_LSR_1_Req "Human Interface Device Kommunikation über ISO TP.";
CM_ SG_ 2549806707 HID_ZR_LSR_1_Resp "Human Interface Device Kommunikation über ISO TP.";
CM_ SG_ 2549642154 HID_ZR_SCC_01_Req_Data "Human Interface Device Kommunikation über ISO TP.";
CM_ SG_ 2549773226 HID_ZR_SCC_01_Resp_Data "Human Interface Device Kommunikation über ISO TP.";
CM_ SG_ 2549642155 HID_ZR_SCC_02_Req_Data "Human Interface Device Kommunikation über ISO TP.";
CM_ SG_ 2549773227 HID_ZR_SCC_02_Resp_Data "Human Interface Device Kommunikation über ISO TP.";
CM_ SG_ 2549642151 HID_ZR_SDC1_Req_Data "Human Interface Device Kommunikation über ISO TP.";
CM_ SG_ 2549773223 HID_ZR_SDC1_Resp_Data "Human Interface Device Kommunikation über ISO TP.";
CM_ SG_ 2549642152 HID_ZR_SDC2_Req_Data "Human Interface Device Kommunikation über ISO TP.";
CM_ SG_ 2549773224 HID_ZR_SDC2_Resp_Data "Human Interface Device Kommunikation über ISO TP.";
CM_ SG_ 1792 ISO_ALL_01_Req_Data "Funktionaler Request ALL";
CM_ SG_ 2549874858 ISOx_SCC1_Req_Data "Diagnose Request SDC1";
CM_ SG_ 2550005930 ISOx_SCC1_Resp_Data "Diagnose Response SDC1";
CM_ SG_ 2549874859 ISOx_SCC2_Req_Data "Diagnose Request SDC1";
CM_ SG_ 2550005931 ISOx_SCC2_Resp_Data "Diagnose Response SDC1";
CM_ SG_ 2549874855 ISOx_SDC1_Req_Data "Diagnose Request SDC1";
CM_ SG_ 2550005927 ISOx_SDC1_Resp_Data "Diagnose Response SDC1";
CM_ SG_ 2549874856 ISOx_SDC2_Req_Data "Diagnose Request SDC2";
CM_ SG_ 2550005928 ISOx_SDC2_Resp_Data "Diagnose Response SDC2";
CM_ SG_ 2549874853 ISOx_WLC1_Req_Data "Diagnose über ISO TP zum WLC1";
CM_ SG_ 2550005925 ISOx_WLC1_Resp_Data "Diagnose über ISO TP zum WLC1";
CM_ SG_ 2549874854 ISOx_WLC2_Req_Data "Diagnose über ISO TP zum WLC2";
CM_ SG_ 2550005926 ISOx_WLC2_Resp_Data "Diagnose über ISO TP zum WLC2";
CM_ BO_ 960 "MQB";
CM_ SG_ 960 Klemmen_Status_01_CRC "Für MLB:
'Berechnung siehe Lastenheft 'Kommunikationsabsicherung für FlexRay und CAN''

Ab MQB und MLBevo:
'Berechnung siehe Lastenheft 'End-to-End Kommunikationsabsicherung''

Endwerte siehe Begleitdokument 'S-PDU Kennungsfolgen'";
CM_ SG_ 960 Klemmen_Status_01_BZ "4bit Botschaftszaehler; wird in jeder Sendebotschaft inkrementiert";
CM_ SG_ 960 RSt_Fahrerhinweise "Über das Signal fordert das BCM Fahrerhinweise im Kombi für die Funktion RemoteStart an.";
CM_ SG_ 960 ZAS_Kl_S "Klemme S: S-Kontakt (Schluessel steckt)
																
																																									 
																	 
									   
																	
				  
";
CM_ SG_ 960 ZAS_Kl_15 "Klemme 15: Zuendung (SW-Kl.15)
";
CM_ SG_ 960 ZAS_Kl_X "Klemme 75
";
CM_ SG_ 960 ZAS_Kl_50_Startanforderung "Klemme 50: Startwunsch Fahrer
";
CM_ SG_ 960 BCM_Remotestart_Betrieb "Zeigt den Status des RemoteStarts an, d.h. KL15_RSt ist aktiviert und der Motorlauf ist im RSt-Betrieb aktiv.";
CM_ SG_ 960 ZAS_Kl_Infotainment "Separate Klemmeninformation für das Infotainment. Signal entspricht im wesentlichen einer Klemme S Information, kann aber über einen Vor - bzw. Nachlauf zu Klemme S verfügen. 
Ein konkreter Anwendungsfall für einen Nachlauf ist die Abschaltung der Klemme";
CM_ SG_ 960 BCM_Remotestart_KL15_Anf "Zeigt den Status der Aktivierung der KL15_RST durch das BCM an.";
CM_ SG_ 960 BCM_Remotestart_MO_Start "Nachdem das BCM die Remotestart MSG Freigabe sicher erkannt hat, fordert das BCM wiederum über dieses Signal vom MSG einen Motorstart durchzuführen.";
CM_ SG_ 960 KST_Warn_P1_ZST_def "Kombi Prio Warnung Klemmensteuerung 
Zündschloß defekt, Service aufsuchen!";
CM_ SG_ 960 KST_Warn_P2_ZST_def "Kombi Prio Warnung Klemmensteuerung
Zündschloß defekt!
";
CM_ SG_ 960 KST_Fahrerhinweis_1 "Signalisierung Fahrerhinweis 1 der Klemmensteuerung an das Kombi";
CM_ SG_ 960 KST_Fahrerhinweis_2 "Signalisierung Fahrerhinweis 2 der Klemmensteuerung an das Kombi";
CM_ SG_ 960 BCM_Ausparken_Betrieb "Anforderung zur erneuten Lampenaufprüfung und Anzeige von Warnhinweisen nach einem pilotierten Ausparkvorgang (Trigger: fallende Flanke)";
CM_ SG_ 960 KST_Fahrerhinweis_4 "Signalisierung Fahrerhinweis 4 der Klemmensteuerung an das Kombi";
CM_ SG_ 960 KST_Fahrerhinweis_5 "Anzeigesignal für RemoteStart";
CM_ SG_ 960 KST_Fahrerhinweis_6 "Signal aktiviert die Kombi-Anzeigeinstrumente (Drehzahl, Tankinhalt, Kühlmitteltemperatur) während aktiviertem RemoteStart-Betrieb";
CM_ SG_ 2549088276 Kombi_KompSchutz "Funktionseinschränkung aufgrund Komponentenschutz aktiv";
CM_ SG_ 2549088276 Kombi_Abschaltstufe "Funktionseinschränkung aufgrund aktiver Abschaltstufe";
CM_ SG_ 2549088276 Kombi_Transport_Mode "Funktionseinschränkung aufgrund aktivem Transport Mode und/oder Transport Schutz";
CM_ SG_ 2549088276 Kombi_Nachlauftyp "Abgebildet wird die von der Hardware vorgegebene Möglichkeit, die Kommunikation nach Klemme 15 = AUS aufrecht zu erhalten. Es wird ein Init-Wert gesendet.
0 = Kommunikation nur bei KL15=EIN (kein Nachlauf, nicht weckfähig)
1 = Kommunikation nach KL15=AU";
CM_ SG_ 2549088276 Kombi_SNI "Das Signal beinhaltet den Source Node Identifier (Knotenadresse, die auch in der Abbildungsvorschrift zur CAN-ID für die NM-High Botschaft verwendet wird).";
CM_ SG_ 2549088276 KN_KBI_DiagPfad "Kennzeichnung der Diagnosefähigkeit des BusInterfaces eines Steuergerätes (Knoten)
Umfang LAH 80127

Bei Nutzung des Signal explizit pro angebundenem BusInterface zu setzen:

MLBevoGen1 auf I-CAN = 0 (aktiv)
MLBevoGen2 auf D-CAN = 0 (aktiv)
MQB auf";
CM_ SG_ 2549088426 SCC1_KompSchutz "Funktionseinschränkung aufgrund Komponentenschutz aktiv";
CM_ SG_ 2549088426 SCC1_Abschaltstufe "Funktionseinschränkung aufgrund aktiver Abschaltstufe";
CM_ SG_ 2549088426 SCC1_Transport_Mode "Funktionseinschränkung aufgrund aktivem Transport Mode und/oder Transport Schutz";
CM_ SG_ 2549088426 SCC1_Nachlauftyp "Abgebildet wird die von der Hardware vorgegebene Möglichkeit, die Kommunikation nach Klemme 15 = AUS aufrecht zu erhalten. Es wird ein Init-Wert gesendet.
0 = Kommunikation nur bei KL15=EIN (kein Nachlauf, nicht weckfähig)
1 = Kommunikation nach KL15=AU";
CM_ SG_ 2549088426 SCC1_SNI "Das Signal beinhaltet den Source Node Identifier (Knotenadresse, die auch in der Abbildungsvorschrift zur CAN-ID für die NM-High Botschaft verwendet wird).";
CM_ SG_ 2549088426 KN_SCC1_BusKnockOutTimer "Ausgabe des BusKnockOut-Timer in der Knotenbotschaft";
CM_ SG_ 2549088426 NM_SCC1_Wakeup "enthält die Weckursache; stehen mehrere Weckursachen parallel an, dann muss der kleinste Wert übertragen werden
  ";
CM_ SG_ 2549088426 NM_SCC1_Lokalaktiv "Zeigt an ob das SG nach Klemme15 AUS und nach entsprechender MAX Aktivzeit noch aktiv war";
CM_ SG_ 2549088427 SCC2_KompSchutz "Funktionseinschränkung aufgrund Komponentenschutz aktiv";
CM_ SG_ 2549088427 SCC2_Abschaltstufe "Funktionseinschränkung aufgrund aktiver Abschaltstufe";
CM_ SG_ 2549088427 SCC2_Transport_Mode "Funktionseinschränkung aufgrund aktivem Transport Mode und/oder Transport Schutz";
CM_ SG_ 2549088427 SCC2_Nachlauftyp "Abgebildet wird die von der Hardware vorgegebene Möglichkeit, die Kommunikation nach Klemme 15 = AUS aufrecht zu erhalten. Es wird ein Init-Wert gesendet.
0 = Kommunikation nur bei KL15=EIN (kein Nachlauf, nicht weckfähig)
1 = Kommunikation nach KL15=AU";
CM_ SG_ 2549088427 SCC2_SNI "Das Signal beinhaltet den Source Node Identifier (Knotenadresse, die auch in der Abbildungsvorschrift zur CAN-ID für die NM-High Botschaft verwendet wird).";
CM_ SG_ 2549088427 KN_SCC2_BusKnockOutTimer "Ausgabe des BusKnockOut-Timer in der Knotenbotschaft";
CM_ SG_ 2549088427 NM_SCC2_Wakeup "enthält die Weckursache; stehen mehrere Weckursachen parallel an, dann muss der kleinste Wert übertragen werden

																								   
																																  
								   
																				
												 
  ";
CM_ SG_ 2549088427 NM_SCC2_Lokalaktiv "Zeigt an ob das SG nach Klemme15 AUS und nach entsprechender MAX Aktivzeit noch aktiv war";
CM_ SG_ 2549088423 SDC1_KompSchutz "Funktionseinschränkung aufgrund Komponentenschutz aktiv";
CM_ SG_ 2549088423 SDC1_Abschaltstufe "Funktionseinschränkung aufgrund aktiver Abschaltstufe";
CM_ SG_ 2549088423 SDC1_Transport_Mode "Funktionseinschränkung aufgrund aktivem Transport Mode und/oder Transport Schutz";
CM_ SG_ 2549088423 SDC1_Nachlauftyp "Abgebildet wird die von der Hardware vorgegebene Möglichkeit, die Kommunikation nach Klemme 15 = AUS aufrecht zu erhalten. Es wird ein Init-Wert gesendet.
0 = Kommunikation nur bei KL15=EIN (kein Nachlauf, nicht weckfähig)
1 = Kommunikation nach KL15=AU";
CM_ SG_ 2549088423 SDC1_SNI "Das Signal beinhaltet den Source Node Identifier (Knotenadresse, die auch in der Abbildungsvorschrift zur CAN-ID für die NM-High Botschaft verwendet wird).";
CM_ SG_ 2549088423 KN_SDC1_BusKnockOutTimer "Ausgabe des BusKnockOut-Timer in der Knotenbotschaft";
CM_ SG_ 2549088423 NM_SDC1_Wakeup "
    enth&#228;lt die Weckursache; stehen mehrere Weckursachen parallel an, dann 
    muss der kleinste Wert &#252;bertragen werden
  ";
CM_ SG_ 2549088423 NM_SDC1_Lokalaktiv "Zeigt an ob das SG nach Klemme15 AUS und nach entsprechender MAX Aktivzeit noch aktiv war";
CM_ SG_ 2549088424 SDC2_KompSchutz "Funktionseinschränkung aufgrund Komponentenschutz aktiv";
CM_ SG_ 2549088424 SDC2_Abschaltstufe "Funktionseinschränkung aufgrund aktiver Abschaltstufe";
CM_ SG_ 2549088424 SDC2_Transport_Mode "Funktionseinschränkung aufgrund aktivem Transport Mode und/oder Transport Schutz";
CM_ SG_ 2549088424 SDC2_Nachlauftyp "Abgebildet wird die von der Hardware vorgegebene Möglichkeit, die Kommunikation nach Klemme 15 = AUS aufrecht zu erhalten. Es wird ein Init-Wert gesendet.
0 = Kommunikation nur bei KL15=EIN (kein Nachlauf, nicht weckfähig)
1 = Kommunikation nach KL15=AU";
CM_ SG_ 2549088424 SDC2_SNI "Das Signal beinhaltet den Source Node Identifier (Knotenadresse, die auch in der Abbildungsvorschrift zur CAN-ID für die NM-High Botschaft verwendet wird).";
CM_ SG_ 2549088424 KN_SDC2_BusKnockOutTimer "Ausgabe des BusKnockOut-Timer in der Knotenbotschaft";
CM_ SG_ 2549088424 NM_SDC2_Wakeup "enthält die Weckursache; stehen mehrere Weckursachen parallel an, dann muss der kleinste Wert übertragen werden";
CM_ SG_ 2549088424 NM_SDC2_Lokalaktiv "Zeigt an ob das SG nach Klemme15 AUS und nach entsprechender MAX Aktivzeit noch aktiv war";
BA_DEF_ BO_  "DiagRequest" ENUM  "No","Yes";
BA_DEF_ BO_  "DiagResponse" ENUM  "No","Yes";
BA_DEF_ BO_  "DiagState" ENUM  "No","Yes";
BA_DEF_ BO_  "GenMsgChkConstant" HEX 0 4095;
BA_DEF_ BO_  "GenMsgCycleTime" INT 0 65535;
BA_DEF_ BO_  "GenMsgCycleTimeFast" INT 0 65535;
BA_DEF_ BO_  "GenMsgDelayTime" INT 0 100000;
BA_DEF_ BO_  "GenMsgILSupport" ENUM  "No","Yes";
BA_DEF_ BO_  "GenMsgNrOfRepetition" INT 0 100;
BA_DEF_ BO_  "GenMsgPDUConstants" STRING ;
BA_DEF_ BO_  "GenMsgSendType" ENUM  "Cyclic","not_used","not_used","not_used","not_used","not_used","not_used","IfActive","NoMsgSendType";
BA_DEF_ BO_  "GenMsgStartDelayTime" INT 0 100000;
BA_DEF_ BO_  "NmMessage" ENUM  "No","Yes";
BA_DEF_ BO_  "NmhMessage" ENUM  "No","Yes";
BA_DEF_ BO_  "MsgType" ENUM  "Application","NM ","NMH","TP2.0","ISO-TP ","BAP","EID","KS";
BA_DEF_ BO_  "VAGTP20_API" HEX 0 255;
BA_DEF_ BO_  "VAGTP20_DynConnection" ENUM  "No","Yes";
BA_DEF_ BO_  "VAGTP20_DynSetup" ENUM  "No","Yes";
BA_DEF_ BO_  "VAGTP20_StatConnection" ENUM  "No","Yes";
BA_DEF_ SG_  "GenSigActiveRepetitions" INT -2147483648 2147483647;
BA_DEF_ SG_  "GenSigInactiveValue" INT -2147483648 2147483647;
BA_DEF_ SG_  "GenSigSendType" ENUM  "Cyclic","OnWrite","OnWriteWithRepetition","OnChange","OnChangeWithRepetition","IfActive","IfActiveWithRepetition","NoSigSendType","OnChangeAndIfActive","OnChangeAndIfActiveWithRepetition";
BA_DEF_ SG_  "GenSigStartValue" INT -2147483648 2147483647;
BA_DEF_ SG_  "NWM-WakeupAllowed" ENUM  "No","Yes";
BA_DEF_ SG_  "GenSigFuncType" ENUM  "NoFunction","MsgCounter","CRC-8","XOR","XOR-2","DatedBit","SW-Kl15","CHK","Constant","Protocol","CRC-8-SAE_J1850","CRC-32","DataLength","DataID","MsgCounter16","SOK-Signatur";
BA_DEF_ SG_  "GenSigSwitchedByIgnition" ENUM  "No","Yes";
BA_DEF_ SG_  "Fehlerwert" HEX 0 2147483647;
BA_DEF_ SG_  "GenSigMissingSourceValue" HEX 0 2147483647;
BA_DEF_REL_ BU_SG_REL_  "GenSigTimeoutTime" INT 0 65535;
BA_DEF_DEF_  "DiagRequest" "No";
BA_DEF_DEF_  "DiagResponse" "No";
BA_DEF_DEF_  "DiagState" "No";
BA_DEF_DEF_  "GenMsgChkConstant" 0;
BA_DEF_DEF_  "GenMsgCycleTime" 0;
BA_DEF_DEF_  "GenMsgCycleTimeFast" 0;
BA_DEF_DEF_  "GenMsgDelayTime" 0;
BA_DEF_DEF_  "GenMsgILSupport" "No";
BA_DEF_DEF_  "GenMsgNrOfRepetition" 0;
BA_DEF_DEF_  "GenMsgPDUConstants" "";
BA_DEF_DEF_  "GenMsgSendType" "NoMsgSendType";
BA_DEF_DEF_  "GenMsgStartDelayTime" 0;
BA_DEF_DEF_  "NmMessage" "No";
BA_DEF_DEF_  "NmhMessage" "No";
BA_DEF_DEF_  "MsgType" "Application";
BA_DEF_DEF_  "VAGTP20_API" 0;
BA_DEF_DEF_  "VAGTP20_DynConnection" "No";
BA_DEF_DEF_  "VAGTP20_DynSetup" "No";
BA_DEF_DEF_  "VAGTP20_StatConnection" "No";
BA_DEF_DEF_  "GenSigActiveRepetitions" 0;
BA_DEF_DEF_  "GenSigInactiveValue" 0;
BA_DEF_DEF_  "GenSigSendType" "NoSigSendType";
BA_DEF_DEF_  "GenSigStartValue" 0;
BA_DEF_DEF_  "NWM-WakeupAllowed" "No";
BA_DEF_DEF_  "GenSigFuncType" "NoFunction";
BA_DEF_DEF_  "GenSigSwitchedByIgnition" "Yes";
BA_DEF_DEF_  "Fehlerwert" 0;
BA_DEF_DEF_  "GenSigMissingSourceValue" 0;
BA_DEF_DEF_REL_ "GenSigTimeoutTime" 0;
BA_ "GenMsgSendType" BO_ 2589283759 0;
BA_ "GenMsgILSupport" BO_ 2589283759 1;
BA_ "GenMsgDelayTime" BO_ 2589283759 40;
BA_ "GenMsgCycleTime" BO_ 2589283759 1000;
BA_ "MsgType" BO_ 2583753221 4;
BA_ "MsgType" BO_ 2583884293 4;
BA_ "MsgType" BO_ 2583753989 4;
BA_ "MsgType" BO_ 2583885061 4;
BA_ "MsgType" BO_ 2583756293 4;
BA_ "MsgType" BO_ 2583887365 4;
BA_ "GenMsgSendType" BO_ 1603 0;
BA_ "GenMsgILSupport" BO_ 1603 1;
BA_ "GenMsgDelayTime" BO_ 1603 100;
BA_ "GenMsgCycleTime" BO_ 1603 1000;
BA_ "GenMsgSendType" BO_ 278 0;
BA_ "GenMsgPDUConstants" BO_ 278 "0xac,0xac,0xac,0xac,0xac,0xac,0xac,0xac,0xac,0xac,0xac,0xac,0xac,0xac,0xac,0xac";
BA_ "GenMsgILSupport" BO_ 278 1;
BA_ "GenMsgCycleTime" BO_ 278 200;
BA_ "GenMsgChkConstant" BO_ 278 172;
BA_ "GenMsgSendType" BO_ 1629 0;
BA_ "GenMsgPDUConstants" BO_ 1629 "0xac,0xb3,0xab,0xeb,0x7a,0xe1,0x3b,0xf7,0x73,0xba,0x7c,0x9e,0x06,0x5f,0x02,0xd9";
BA_ "GenMsgILSupport" BO_ 1629 1;
BA_ "GenMsgDelayTime" BO_ 1629 200;
BA_ "GenMsgCycleTime" BO_ 1629 1000;
BA_ "GenMsgSendType" BO_ 795 0;
BA_ "GenMsgPDUConstants" BO_ 795 "0x67,0x8a,0xae,0x22,0x4d,0xd0,0x51,0x80,0x5c,0xb9,0xce,0x1e,0xdf,0x02,0x2d,0xd4";
BA_ "GenMsgILSupport" BO_ 795 1;
BA_ "GenMsgCycleTime" BO_ 795 50;
BA_ "GenMsgSendType" BO_ 2589283409 0;
BA_ "GenMsgILSupport" BO_ 2589283409 1;
BA_ "GenMsgCycleTime" BO_ 2589283409 1000;
BA_ "GenMsgSendType" BO_ 986 0;
BA_ "GenMsgILSupport" BO_ 986 1;
BA_ "GenMsgDelayTime" BO_ 986 10;
BA_ "GenMsgCycleTime" BO_ 986 100;
BA_ "GenMsgSendType" BO_ 987 0;
BA_ "GenMsgILSupport" BO_ 987 1;
BA_ "GenMsgDelayTime" BO_ 987 10;
BA_ "GenMsgCycleTime" BO_ 987 100;
BA_ "GenMsgSendType" BO_ 2589284280 0;
BA_ "GenMsgILSupport" BO_ 2589284280 1;
BA_ "GenMsgDelayTime" BO_ 2589284280 100;
BA_ "GenMsgCycleTime" BO_ 2589284280 1000;
BA_ "GenMsgSendType" BO_ 2589284281 0;
BA_ "GenMsgILSupport" BO_ 2589284281 1;
BA_ "GenMsgDelayTime" BO_ 2589284281 100;
BA_ "GenMsgCycleTime" BO_ 2589284281 1000;
BA_ "GenMsgSendType" BO_ 2589284283 0;
BA_ "GenMsgILSupport" BO_ 2589284283 1;
BA_ "GenMsgDelayTime" BO_ 2589284283 100;
BA_ "GenMsgCycleTime" BO_ 2589284283 1000;
BA_ "MsgType" BO_ 2549674355 4;
BA_ "MsgType" BO_ 2549773297 4;
BA_ "MsgType" BO_ 2549674099 4;
BA_ "MsgType" BO_ 2549773296 4;
BA_ "MsgType" BO_ 2549674611 4;
BA_ "MsgType" BO_ 2549773298 4;
BA_ "MsgType" BO_ 2549675379 4;
BA_ "MsgType" BO_ 2549773301 4;
BA_ "MsgType" BO_ 2549677683 4;
BA_ "MsgType" BO_ 2549808755 4;
BA_ "MsgType" BO_ 2549675635 4;
BA_ "MsgType" BO_ 2549773302 4;
BA_ "MsgType" BO_ 2549656179 4;
BA_ "MsgType" BO_ 2549787251 4;
BA_ "MsgType" BO_ 2549656435 4;
BA_ "MsgType" BO_ 2549787507 4;
BA_ "MsgType" BO_ 2549655411 4;
BA_ "MsgType" BO_ 2549786483 4;
BA_ "MsgType" BO_ 2549655667 4;
BA_ "MsgType" BO_ 2549786739 4;
BA_ "MsgType" BO_ 2549642225 4;
BA_ "MsgType" BO_ 2549805427 4;
BA_ "MsgType" BO_ 2549642224 4;
BA_ "MsgType" BO_ 2549805171 4;
BA_ "MsgType" BO_ 2549642226 4;
BA_ "MsgType" BO_ 2549805683 4;
BA_ "MsgType" BO_ 2549642229 4;
BA_ "MsgType" BO_ 2549806451 4;
BA_ "MsgType" BO_ 2549642238 4;
BA_ "MsgType" BO_ 2549773310 4;
BA_ "MsgType" BO_ 2549642230 4;
BA_ "MsgType" BO_ 2549806707 4;
BA_ "MsgType" BO_ 2549642154 4;
BA_ "MsgType" BO_ 2549773226 4;
BA_ "MsgType" BO_ 2549642155 4;
BA_ "MsgType" BO_ 2549773227 4;
BA_ "MsgType" BO_ 2549642151 4;
BA_ "MsgType" BO_ 2549773223 4;
BA_ "MsgType" BO_ 2549642152 4;
BA_ "MsgType" BO_ 2549773224 4;
BA_ "MsgType" BO_ 1792 4;
BA_ "DiagState" BO_ 1792 1;
BA_ "MsgType" BO_ 2549874858 4;
BA_ "DiagRequest" BO_ 2549874858 1;
BA_ "MsgType" BO_ 2550005930 4;
BA_ "DiagResponse" BO_ 2550005930 1;
BA_ "MsgType" BO_ 2549874859 4;
BA_ "DiagRequest" BO_ 2549874859 1;
BA_ "MsgType" BO_ 2550005931 4;
BA_ "DiagResponse" BO_ 2550005931 1;
BA_ "MsgType" BO_ 2549874855 4;
BA_ "DiagRequest" BO_ 2549874855 1;
BA_ "MsgType" BO_ 2550005927 4;
BA_ "DiagResponse" BO_ 2550005927 1;
BA_ "MsgType" BO_ 2549874856 4;
BA_ "DiagRequest" BO_ 2549874856 1;
BA_ "MsgType" BO_ 2550005928 4;
BA_ "DiagResponse" BO_ 2550005928 1;
BA_ "MsgType" BO_ 2549874853 4;
BA_ "DiagRequest" BO_ 2549874853 1;
BA_ "MsgType" BO_ 2550005925 4;
BA_ "DiagResponse" BO_ 2550005925 1;
BA_ "MsgType" BO_ 2549874854 4;
BA_ "DiagRequest" BO_ 2549874854 1;
BA_ "MsgType" BO_ 2550005926 4;
BA_ "DiagResponse" BO_ 2550005926 1;
BA_ "GenMsgSendType" BO_ 960 0;
BA_ "GenMsgPDUConstants" BO_ 960 "0xc3,0xc3,0xc3,0xc3,0xc3,0xc3,0xc3,0xc3,0xc3,0xc3,0xc3,0xc3,0xc3,0xc3,0xc3,0xc3";
BA_ "GenMsgILSupport" BO_ 960 1;
BA_ "GenMsgDelayTime" BO_ 960 10;
BA_ "GenMsgCycleTime" BO_ 960 100;
BA_ "GenMsgChkConstant" BO_ 960 195;
BA_ "GenMsgSendType" BO_ 2549088276 0;
BA_ "GenMsgILSupport" BO_ 2549088276 1;
BA_ "GenMsgCycleTime" BO_ 2549088276 500;
BA_ "GenMsgSendType" BO_ 2549088426 0;
BA_ "GenMsgILSupport" BO_ 2549088426 1;
BA_ "GenMsgCycleTime" BO_ 2549088426 500;
BA_ "GenMsgSendType" BO_ 2549088427 0;
BA_ "GenMsgILSupport" BO_ 2549088427 1;
BA_ "GenMsgCycleTime" BO_ 2549088427 500;
BA_ "GenMsgSendType" BO_ 2549088423 0;
BA_ "GenMsgILSupport" BO_ 2549088423 1;
BA_ "GenMsgCycleTime" BO_ 2549088423 500;
BA_ "GenMsgSendType" BO_ 2549088424 0;
BA_ "GenMsgILSupport" BO_ 2549088424 1;
BA_ "GenMsgCycleTime" BO_ 2549088424 500;
BA_ "GenSigSendType" SG_ 2589283759 DU3_LVDS_Splitter_Fehlerstatus 0;
BA_ "GenSigSwitchedByIgnition" SG_ 2589283759 DU3_LVDS_Splitter_Fehlerstatus 0;
BA_ "Fehlerwert" SG_ 2589283759 DU3_Betriebsdauer_min 255;
BA_ "GenSigSwitchedByIgnition" SG_ 2589283759 DU3_Betriebsdauer_min 0;
BA_ "GenSigStartValue" SG_ 2589283759 DU3_Betriebsdauer_min 254;
BA_ "GenSigSendType" SG_ 2589283759 DU3_Betriebsdauer_min 0;
BA_ "Fehlerwert" SG_ 2589283759 DU3_Betriebsdauer_std 65535;
BA_ "GenSigSwitchedByIgnition" SG_ 2589283759 DU3_Betriebsdauer_std 0;
BA_ "GenSigStartValue" SG_ 2589283759 DU3_Betriebsdauer_std 65534;
BA_ "GenSigSendType" SG_ 2589283759 DU3_Betriebsdauer_std 0;
BA_ "Fehlerwert" SG_ 2589283759 DU3_HintGrdBelKurzschl 1;
BA_ "GenSigSwitchedByIgnition" SG_ 2589283759 DU3_HintGrdBelKurzschl 0;
BA_ "GenSigSendType" SG_ 2589283759 DU3_HintGrdBelKurzschl 3;
BA_ "Fehlerwert" SG_ 2589283759 DU3_HintGrdBelUnterbr 1;
BA_ "GenSigSwitchedByIgnition" SG_ 2589283759 DU3_HintGrdBelUnterbr 0;
BA_ "GenSigSendType" SG_ 2589283759 DU3_HintGrdBelUnterbr 3;
BA_ "Fehlerwert" SG_ 2589283759 DU3_EEPROM_Fehler 1;
BA_ "GenSigSwitchedByIgnition" SG_ 2589283759 DU3_EEPROM_Fehler 0;
BA_ "GenSigSendType" SG_ 2589283759 DU3_EEPROM_Fehler 3;
BA_ "Fehlerwert" SG_ 2589283759 DU3_SW_inkonsistent 1;
BA_ "GenSigSwitchedByIgnition" SG_ 2589283759 DU3_SW_inkonsistent 0;
BA_ "GenSigSendType" SG_ 2589283759 DU3_SW_inkonsistent 0;
BA_ "Fehlerwert" SG_ 2589283759 DU3_HDCP_Status 1;
BA_ "GenSigSwitchedByIgnition" SG_ 2589283759 DU3_HDCP_Status 0;
BA_ "GenSigSendType" SG_ 2589283759 DU3_HDCP_Status 3;
BA_ "GenSigSwitchedByIgnition" SG_ 2589283759 DU3_LVDS_Status 0;
BA_ "GenSigSendType" SG_ 2589283759 DU3_LVDS_Status 3;
BA_ "GenSigSwitchedByIgnition" SG_ 2589283759 DU3_ZR_Lenkerpos_Status 0;
BA_ "GenSigSendType" SG_ 2589283759 DU3_ZR_Lenkerpos_Status 0;
BA_ "GenSigSwitchedByIgnition" SG_ 2589283759 DU3_Touch_Fehlerstatus 0;
BA_ "GenSigSendType" SG_ 2589283759 DU3_Touch_Fehlerstatus 0;
BA_ "GenSigSwitchedByIgnition" SG_ 2589283759 DU3_Haptik_Fehlerstatus 0;
BA_ "GenSigSendType" SG_ 2589283759 DU3_Haptik_Fehlerstatus 0;
BA_ "GenSigSwitchedByIgnition" SG_ 2583753221 DU_1_SWDL_Req_Data 0;
BA_ "GenSigSwitchedByIgnition" SG_ 2583884293 DU_1_SWDL_Resp_Data 0;
BA_ "GenSigSwitchedByIgnition" SG_ 2583753989 DU_2_SWDL_Req_Data 0;
BA_ "GenSigSwitchedByIgnition" SG_ 2583885061 DU_2_SWDL_Resp_Data 0;
BA_ "GenSigSwitchedByIgnition" SG_ 2583756293 DU_3_SWDL_Req_Data 0;
BA_ "GenSigSwitchedByIgnition" SG_ 2583887365 DU_3_SWDL_Resp_Data 0;
BA_ "GenSigSwitchedByIgnition" SG_ 2583753733 DU_4_SWDL_Req_Data 0;
BA_ "GenSigSendType" SG_ 2583753733 DU_4_SWDL_Req_Data 3;
BA_ "GenSigSwitchedByIgnition" SG_ 2583884805 DU_4_SWDL_Resp_Data 0;
BA_ "GenSigSendType" SG_ 2583884805 DU_4_SWDL_Resp_Data 3;
BA_ "GenSigSwitchedByIgnition" SG_ 1603 KBI_Einheit_Datum 0;
BA_ "GenSigSendType" SG_ 1603 KBI_Einheit_Datum 3;
BA_ "GenSigSwitchedByIgnition" SG_ 1603 KBI_Einheit_Druck 0;
BA_ "GenSigSendType" SG_ 1603 KBI_Einheit_Druck 3;
BA_ "GenSigSwitchedByIgnition" SG_ 1603 KBI_Einheit_Streckenanz 0;
BA_ "GenSigSendType" SG_ 1603 KBI_Einheit_Streckenanz 3;
BA_ "GenSigSwitchedByIgnition" SG_ 1603 KBI_MFA_v_Einheit_02 0;
BA_ "GenSigSendType" SG_ 1603 KBI_MFA_v_Einheit_02 3;
BA_ "GenSigSwitchedByIgnition" SG_ 1603 KBI_Einheit_Temp 0;
BA_ "GenSigSendType" SG_ 1603 KBI_Einheit_Temp 3;
BA_ "GenSigSwitchedByIgnition" SG_ 1603 KBI_Einheit_Uhrzeit 0;
BA_ "GenSigSendType" SG_ 1603 KBI_Einheit_Uhrzeit 3;
BA_ "GenSigSwitchedByIgnition" SG_ 1603 KBI_Einheit_Verbrauch 0;
BA_ "GenSigSendType" SG_ 1603 KBI_Einheit_Verbrauch 3;
BA_ "GenSigSwitchedByIgnition" SG_ 1603 KBI_Einheit_Volumen 0;
BA_ "GenSigSendType" SG_ 1603 KBI_Einheit_Volumen 3;
BA_ "GenSigSwitchedByIgnition" SG_ 1603 KBI_Einheit_Verbrauch_elektr 0;
BA_ "GenSigSendType" SG_ 1603 KBI_Einheit_Verbrauch_elektr 3;
BA_ "GenSigSwitchedByIgnition" SG_ 1603 KBI_Einheit_Sprache 0;
BA_ "GenSigSendType" SG_ 1603 KBI_Einheit_Sprache 3;
BA_ "GenSigSwitchedByIgnition" SG_ 1603 KBI_Einheit_Verbrauch_Gas 0;
BA_ "GenSigSendType" SG_ 1603 KBI_Einheit_Verbrauch_Gas 3;
BA_ "GenSigSwitchedByIgnition" SG_ 1603 KBI_Einheit_Masse 0;
BA_ "GenSigSendType" SG_ 1603 KBI_Einheit_Masse 3;
BA_ "GenSigSwitchedByIgnition" SG_ 278 ESP_10_CRC 0;
BA_ "GenSigFuncType" SG_ 278 ESP_10_CRC 2;
BA_ "GenSigSendType" SG_ 278 ESP_10_CRC 0;
BA_ "GenSigSwitchedByIgnition" SG_ 278 ESP_10_BZ 0;
BA_ "GenSigFuncType" SG_ 278 ESP_10_BZ 1;
BA_ "GenSigSendType" SG_ 278 ESP_10_BZ 0;
BA_ "GenSigSwitchedByIgnition" SG_ 278 ESP_QBit_Wegimpuls_VL 0;
BA_ "GenSigStartValue" SG_ 278 ESP_QBit_Wegimpuls_VL 1;
BA_ "GenSigSendType" SG_ 278 ESP_QBit_Wegimpuls_VL 0;
BA_ "GenSigSwitchedByIgnition" SG_ 278 ESP_QBit_Wegimpuls_VR 0;
BA_ "GenSigStartValue" SG_ 278 ESP_QBit_Wegimpuls_VR 1;
BA_ "GenSigSendType" SG_ 278 ESP_QBit_Wegimpuls_VR 0;
BA_ "GenSigSwitchedByIgnition" SG_ 278 ESP_QBit_Wegimpuls_HL 0;
BA_ "GenSigStartValue" SG_ 278 ESP_QBit_Wegimpuls_HL 1;
BA_ "GenSigSendType" SG_ 278 ESP_QBit_Wegimpuls_HL 0;
BA_ "GenSigSwitchedByIgnition" SG_ 278 ESP_QBit_Wegimpuls_HR 0;
BA_ "GenSigStartValue" SG_ 278 ESP_QBit_Wegimpuls_HR 1;
BA_ "GenSigSendType" SG_ 278 ESP_QBit_Wegimpuls_HR 0;
BA_ "Fehlerwert" SG_ 278 ESP_Wegimpuls_VL 1023;
BA_ "GenSigSwitchedByIgnition" SG_ 278 ESP_Wegimpuls_VL 0;
BA_ "GenSigStartValue" SG_ 278 ESP_Wegimpuls_VL 1021;
BA_ "GenSigSendType" SG_ 278 ESP_Wegimpuls_VL 0;
BA_ "Fehlerwert" SG_ 278 ESP_Wegimpuls_VR 1023;
BA_ "GenSigSwitchedByIgnition" SG_ 278 ESP_Wegimpuls_VR 0;
BA_ "GenSigStartValue" SG_ 278 ESP_Wegimpuls_VR 1021;
BA_ "GenSigSendType" SG_ 278 ESP_Wegimpuls_VR 0;
BA_ "Fehlerwert" SG_ 278 ESP_Wegimpuls_HL 1023;
BA_ "GenSigSwitchedByIgnition" SG_ 278 ESP_Wegimpuls_HL 0;
BA_ "GenSigStartValue" SG_ 278 ESP_Wegimpuls_HL 1021;
BA_ "GenSigSendType" SG_ 278 ESP_Wegimpuls_HL 0;
BA_ "Fehlerwert" SG_ 278 ESP_Wegimpuls_HR 1023;
BA_ "GenSigSwitchedByIgnition" SG_ 278 ESP_Wegimpuls_HR 0;
BA_ "GenSigStartValue" SG_ 278 ESP_Wegimpuls_HR 1021;
BA_ "GenSigSendType" SG_ 278 ESP_Wegimpuls_HR 0;
BA_ "GenSigSwitchedByIgnition" SG_ 278 ESP_VL_Fahrtrichtung 0;
BA_ "GenSigStartValue" SG_ 278 ESP_VL_Fahrtrichtung 2;
BA_ "GenSigSendType" SG_ 278 ESP_VL_Fahrtrichtung 0;
BA_ "GenSigSwitchedByIgnition" SG_ 278 ESP_VR_Fahrtrichtung 0;
BA_ "GenSigStartValue" SG_ 278 ESP_VR_Fahrtrichtung 2;
BA_ "GenSigSendType" SG_ 278 ESP_VR_Fahrtrichtung 0;
BA_ "GenSigSwitchedByIgnition" SG_ 278 ESP_HL_Fahrtrichtung 0;
BA_ "GenSigStartValue" SG_ 278 ESP_HL_Fahrtrichtung 2;
BA_ "GenSigSendType" SG_ 278 ESP_HL_Fahrtrichtung 0;
BA_ "GenSigSwitchedByIgnition" SG_ 278 ESP_HR_Fahrtrichtung 0;
BA_ "GenSigStartValue" SG_ 278 ESP_HR_Fahrtrichtung 2;
BA_ "GenSigSendType" SG_ 278 ESP_HR_Fahrtrichtung 0;
BA_ "GenSigSwitchedByIgnition" SG_ 1629 ESP_20_CRC 0;
BA_ "GenSigFuncType" SG_ 1629 ESP_20_CRC 2;
BA_ "GenSigSendType" SG_ 1629 ESP_20_CRC 0;
BA_ "GenSigSwitchedByIgnition" SG_ 1629 ESP_20_BZ 0;
BA_ "GenSigFuncType" SG_ 1629 ESP_20_BZ 1;
BA_ "GenSigSendType" SG_ 1629 ESP_20_BZ 0;
BA_ "GenSigSwitchedByIgnition" SG_ 1629 BR_Systemart 0;
BA_ "GenSigFuncType" SG_ 1629 BR_Systemart 8;
BA_ "GenSigSendType" SG_ 1629 BR_Systemart 0;
BA_ "GenSigSwitchedByIgnition" SG_ 1629 ESP_SpannungsAnf_02 0;
BA_ "GenSigSendType" SG_ 1629 ESP_SpannungsAnf_02 3;
BA_ "GenSigSwitchedByIgnition" SG_ 1629 ESP_Zaehnezahl 0;
BA_ "GenSigFuncType" SG_ 1629 ESP_Zaehnezahl 8;
BA_ "GenSigSendType" SG_ 1629 ESP_Zaehnezahl 0;
BA_ "GenSigSwitchedByIgnition" SG_ 1629 ESP_Charisma_FahrPr 0;
BA_ "GenSigSendType" SG_ 1629 ESP_Charisma_FahrPr 3;
BA_ "GenSigSwitchedByIgnition" SG_ 1629 ESP_Charisma_Status 0;
BA_ "GenSigSendType" SG_ 1629 ESP_Charisma_Status 3;
BA_ "GenSigSwitchedByIgnition" SG_ 1629 ESP_Wiederstart_Anz_01 0;
BA_ "GenSigSendType" SG_ 1629 ESP_Wiederstart_Anz_01 3;
BA_ "GenSigSwitchedByIgnition" SG_ 1629 ESP_Wiederstart_Anz_02 0;
BA_ "GenSigSendType" SG_ 1629 ESP_Wiederstart_Anz_02 3;
BA_ "GenSigSwitchedByIgnition" SG_ 1629 ESP_Wiederstart_Anz_03 0;
BA_ "GenSigSendType" SG_ 1629 ESP_Wiederstart_Anz_03 3;
BA_ "GenSigSwitchedByIgnition" SG_ 1629 ESP_Wiederstart_Anz_04 0;
BA_ "GenSigSendType" SG_ 1629 ESP_Wiederstart_Anz_04 3;
BA_ "GenSigSwitchedByIgnition" SG_ 1629 ESP_Stoppverbot_Anz_01 0;
BA_ "GenSigSendType" SG_ 1629 ESP_Stoppverbot_Anz_01 3;
BA_ "GenSigSwitchedByIgnition" SG_ 1629 ESP_Stoppverbot_Anz_02 0;
BA_ "GenSigSendType" SG_ 1629 ESP_Stoppverbot_Anz_02 3;
BA_ "GenSigSwitchedByIgnition" SG_ 1629 ESP_Stoppverbot_Anz_03 0;
BA_ "GenSigSendType" SG_ 1629 ESP_Stoppverbot_Anz_03 3;
BA_ "GenSigSwitchedByIgnition" SG_ 1629 ESP_Stoppverbot_Anz_04 0;
BA_ "GenSigSendType" SG_ 1629 ESP_Stoppverbot_Anz_04 3;
BA_ "GenSigSwitchedByIgnition" SG_ 1629 ESP_Stoppverbot_Anz_05 0;
BA_ "GenSigSendType" SG_ 1629 ESP_Stoppverbot_Anz_05 3;
BA_ "GenSigSwitchedByIgnition" SG_ 1629 ESP_Stoppverbot_Anz_06 0;
BA_ "GenSigSendType" SG_ 1629 ESP_Stoppverbot_Anz_06 3;
BA_ "GenSigSwitchedByIgnition" SG_ 1629 ESP_Stoppverbot_Anz_07 0;
BA_ "GenSigSendType" SG_ 1629 ESP_Stoppverbot_Anz_07 3;
BA_ "GenSigSwitchedByIgnition" SG_ 1629 ESP_Stoppverbot_Anz_Std 0;
BA_ "GenSigSendType" SG_ 1629 ESP_Stoppverbot_Anz_Std 3;
BA_ "Fehlerwert" SG_ 1629 ESP_Dachrelingsensor 3;
BA_ "GenSigSwitchedByIgnition" SG_ 1629 ESP_Dachrelingsensor 0;
BA_ "GenSigSendType" SG_ 1629 ESP_Dachrelingsensor 0;
BA_ "GenSigSwitchedByIgnition" SG_ 1629 ESP_Stoppverbot_Anz_08 0;
BA_ "GenSigSendType" SG_ 1629 ESP_Stoppverbot_Anz_08 3;
BA_ "GenSigSwitchedByIgnition" SG_ 1629 HDC_Charisma_FahrPr 0;
BA_ "GenSigSendType" SG_ 1629 HDC_Charisma_FahrPr 3;
BA_ "GenSigSwitchedByIgnition" SG_ 1629 HDC_Charisma_Status 0;
BA_ "GenSigSendType" SG_ 1629 HDC_Charisma_Status 3;
BA_ "GenSigSwitchedByIgnition" SG_ 1629 BR_QBit_Reifenumfang 0;
BA_ "GenSigStartValue" SG_ 1629 BR_QBit_Reifenumfang 1;
BA_ "GenSigSendType" SG_ 1629 BR_QBit_Reifenumfang 0;
BA_ "GenSigSwitchedByIgnition" SG_ 1629 BR_Reifenumfang 0;
BA_ "GenSigSendType" SG_ 1629 BR_Reifenumfang 0;
BA_ "GenSigSwitchedByIgnition" SG_ 795 ESP_24_CRC 0;
BA_ "GenSigFuncType" SG_ 795 ESP_24_CRC 2;
BA_ "GenSigSendType" SG_ 795 ESP_24_CRC 0;
BA_ "GenSigSwitchedByIgnition" SG_ 795 ESP_24_BZ 0;
BA_ "GenSigFuncType" SG_ 795 ESP_24_BZ 1;
BA_ "GenSigSendType" SG_ 795 ESP_24_BZ 0;
BA_ "GenSigSwitchedByIgnition" SG_ 795 ESP_Lampe 0;
BA_ "GenSigStartValue" SG_ 795 ESP_Lampe 1;
BA_ "GenSigSendType" SG_ 795 ESP_Lampe 0;
BA_ "GenSigSwitchedByIgnition" SG_ 795 ABS_Lampe 0;
BA_ "GenSigStartValue" SG_ 795 ABS_Lampe 1;
BA_ "GenSigSendType" SG_ 795 ABS_Lampe 0;
BA_ "GenSigSwitchedByIgnition" SG_ 795 BK_Lampe_02 0;
BA_ "GenSigStartValue" SG_ 795 BK_Lampe_02 1;
BA_ "GenSigSendType" SG_ 795 BK_Lampe_02 0;
BA_ "GenSigSwitchedByIgnition" SG_ 795 TC_Lampe 0;
BA_ "GenSigSendType" SG_ 795 TC_Lampe 0;
BA_ "Fehlerwert" SG_ 795 ESP_m_Raddrehz 32767;
BA_ "GenSigSwitchedByIgnition" SG_ 795 ESP_m_Raddrehz 0;
BA_ "GenSigStartValue" SG_ 795 ESP_m_Raddrehz 32766;
BA_ "GenSigSendType" SG_ 795 ESP_m_Raddrehz 0;
BA_ "GenSigSwitchedByIgnition" SG_ 795 ESP_Textanzeigen_03 0;
BA_ "GenSigSendType" SG_ 795 ESP_Textanzeigen_03 0;
BA_ "GenSigSwitchedByIgnition" SG_ 795 ESP_Meldungen 0;
BA_ "GenSigSendType" SG_ 795 ESP_Meldungen 0;
BA_ "GenSigSwitchedByIgnition" SG_ 795 ESP_Wegimp_VA 0;
BA_ "GenSigSendType" SG_ 795 ESP_Wegimp_VA 0;
BA_ "GenSigSwitchedByIgnition" SG_ 795 ESP_Fehlerstatus_Wegimp 0;
BA_ "GenSigSendType" SG_ 795 ESP_Fehlerstatus_Wegimp 0;
BA_ "GenSigSwitchedByIgnition" SG_ 795 ESP_Wegimp_Ueberlauf 0;
BA_ "GenSigSendType" SG_ 795 ESP_Wegimp_Ueberlauf 0;
BA_ "GenSigSwitchedByIgnition" SG_ 795 ESP_QBit_Wegimp_VA 0;
BA_ "GenSigStartValue" SG_ 795 ESP_QBit_Wegimp_VA 1;
BA_ "GenSigSendType" SG_ 795 ESP_QBit_Wegimp_VA 0;
BA_ "GenSigSwitchedByIgnition" SG_ 795 ESP_HDC_FktLampe 0;
BA_ "GenSigSendType" SG_ 795 ESP_HDC_FktLampe 0;
BA_ "GenSigSwitchedByIgnition" SG_ 795 ESP_Off_Lampe 0;
BA_ "GenSigSendType" SG_ 795 ESP_Off_Lampe 0;
BA_ "Fehlerwert" SG_ 795 ESP_HDC_Regelgeschw 127;
BA_ "GenSigSwitchedByIgnition" SG_ 795 ESP_HDC_Regelgeschw 0;
BA_ "GenSigStartValue" SG_ 795 ESP_HDC_Regelgeschw 126;
BA_ "GenSigSendType" SG_ 795 ESP_HDC_Regelgeschw 0;
BA_ "GenSigSwitchedByIgnition" SG_ 795 ESP_BKV_Warnung 0;
BA_ "GenSigSendType" SG_ 795 ESP_BKV_Warnung 0;
BA_ "GenSigSwitchedByIgnition" SG_ 2589283409 EB_Jahr 0;
BA_ "GenSigSendType" SG_ 2589283409 EB_Jahr 0;
BA_ "Fehlerwert" SG_ 2589283409 EB_Monat 15;
BA_ "GenSigSwitchedByIgnition" SG_ 2589283409 EB_Monat 0;
BA_ "GenSigSendType" SG_ 2589283409 EB_Monat 0;
BA_ "GenSigSwitchedByIgnition" SG_ 2589283409 EB_Tag 0;
BA_ "GenSigSendType" SG_ 2589283409 EB_Tag 0;
BA_ "GenSigSwitchedByIgnition" SG_ 2589283409 EB_Stunde 0;
BA_ "GenSigSendType" SG_ 2589283409 EB_Stunde 0;
BA_ "GenSigSwitchedByIgnition" SG_ 2589283409 EB_Minute 0;
BA_ "GenSigSendType" SG_ 2589283409 EB_Minute 0;
BA_ "GenSigSwitchedByIgnition" SG_ 2589283409 EB_Sekunde 0;
BA_ "GenSigSendType" SG_ 2589283409 EB_Sekunde 0;
BA_ "GenSigSwitchedByIgnition" SG_ 2589283409 EB_Zeit_gueltig 0;
BA_ "GenSigSendType" SG_ 2589283409 EB_Zeit_gueltig 0;
BA_ "GenSigSwitchedByIgnition" SG_ 986 ESP_05_alt 0;
BA_ "GenSigFuncType" SG_ 986 ESP_05_alt 5;
BA_ "GenSigStartValue" SG_ 986 ESP_05_alt 1;
BA_ "GenSigSendType" SG_ 986 ESP_05_alt 0;
BA_ "GenSigSwitchedByIgnition" SG_ 986 EPB_01_alt 0;
BA_ "GenSigFuncType" SG_ 986 EPB_01_alt 5;
BA_ "GenSigStartValue" SG_ 986 EPB_01_alt 1;
BA_ "GenSigSendType" SG_ 986 EPB_01_alt 0;
BA_ "GenSigSwitchedByIgnition" SG_ 986 ESP_21_alt 0;
BA_ "GenSigFuncType" SG_ 986 ESP_21_alt 5;
BA_ "GenSigStartValue" SG_ 986 ESP_21_alt 1;
BA_ "GenSigSendType" SG_ 986 ESP_21_alt 0;
BA_ "GenSigSwitchedByIgnition" SG_ 986 LWI_01_alt 0;
BA_ "GenSigFuncType" SG_ 986 LWI_01_alt 5;
BA_ "GenSigStartValue" SG_ 986 LWI_01_alt 1;
BA_ "GenSigSendType" SG_ 986 LWI_01_alt 0;
BA_ "GenSigSwitchedByIgnition" SG_ 986 Parkhilfe_01_alt 0;
BA_ "GenSigFuncType" SG_ 986 Parkhilfe_01_alt 5;
BA_ "GenSigStartValue" SG_ 986 Parkhilfe_01_alt 1;
BA_ "GenSigSendType" SG_ 986 Parkhilfe_01_alt 0;
BA_ "GenSigSwitchedByIgnition" SG_ 986 Kamera_Status_alt 0;
BA_ "GenSigFuncType" SG_ 986 Kamera_Status_alt 5;
BA_ "GenSigStartValue" SG_ 986 Kamera_Status_alt 1;
BA_ "GenSigSendType" SG_ 986 Kamera_Status_alt 0;
BA_ "GenSigSwitchedByIgnition" SG_ 986 ESP_HDC_Standby 0;
BA_ "GenSigSwitchedByIgnition" SG_ 986 ECD_Bremslicht 0;
BA_ "GenSigSendType" SG_ 986 ECD_Bremslicht 3;
BA_ "GenSigSwitchedByIgnition" SG_ 986 EPB_Status 0;
BA_ "GenSigSendType" SG_ 986 EPB_Status 0;
BA_ "GenSigSwitchedByIgnition" SG_ 986 EPB_QBit_Pedalweg_Kuppl 0;
BA_ "GenSigStartValue" SG_ 986 EPB_QBit_Pedalweg_Kuppl 1;
BA_ "GenSigSendType" SG_ 986 EPB_QBit_Pedalweg_Kuppl 0;
BA_ "GenSigSwitchedByIgnition" SG_ 986 ESP_QBit_v_Signal 0;
BA_ "GenSigStartValue" SG_ 986 ESP_QBit_v_Signal 1;
BA_ "GenSigSendType" SG_ 986 ESP_QBit_v_Signal 0;
BA_ "GenSigSwitchedByIgnition" SG_ 986 ABS_Bremsung 0;
BA_ "GenSigSendType" SG_ 986 ABS_Bremsung 0;
BA_ "GenSigSwitchedByIgnition" SG_ 986 ESP_Eingriff 0;
BA_ "GenSigSendType" SG_ 986 ESP_Eingriff 0;
BA_ "GenSigSendType" SG_ 986 Kamera_FSH_aktiv 0;
BA_ "Fehlerwert" SG_ 986 EPB_Pedalweg_Kuppl 255;
BA_ "GenSigSwitchedByIgnition" SG_ 986 EPB_Pedalweg_Kuppl 0;
BA_ "GenSigSendType" SG_ 986 EPB_Pedalweg_Kuppl 0;
BA_ "GenSigMissingSourceValue" SG_ 986 ESP_v_Signal 65534;
BA_ "Fehlerwert" SG_ 986 ESP_v_Signal 65535;
BA_ "GenSigSwitchedByIgnition" SG_ 986 ESP_v_Signal 0;
BA_ "GenSigStartValue" SG_ 986 ESP_v_Signal 65534;
BA_ "GenSigSendType" SG_ 986 ESP_v_Signal 0;
BA_ "GenSigStartValue" SG_ 986 LWI_QBit_Lenkradwinkel 1;
BA_ "GenSigSendType" SG_ 986 LWI_QBit_Lenkradwinkel 0;
BA_ "GenSigSendType" SG_ 986 LWI_Sensorstatus 0;
BA_ "GenSigSendType" SG_ 986 LWI_VZ_Lenkradwinkel 0;
BA_ "Fehlerwert" SG_ 986 LWI_Lenkradwinkel 8191;
BA_ "GenSigStartValue" SG_ 986 LWI_Lenkradwinkel 8190;
BA_ "GenSigSendType" SG_ 986 LWI_Lenkradwinkel 0;
BA_ "GenSigSendType" SG_ 986 PH_Anf_Audioabsenkung 0;
BA_ "GenSigSendType" SG_ 986 PH_Systemzustand 0;
BA_ "Fehlerwert" SG_ 986 PH_Taster 3;
BA_ "GenSigSendType" SG_ 986 PH_Taster 3;
BA_ "GenSigSwitchedByIgnition" SG_ 986 ESP_MKB_Abbruch_Geschw 0;
BA_ "GenSigSendType" SG_ 986 ESP_MKB_Abbruch_Geschw 3;
BA_ "GenSigSendType" SG_ 986 PLA_Anf_Aufschaltung_RVC 3;
BA_ "GenSigSwitchedByIgnition" SG_ 987 BCM_01_alt 0;
BA_ "GenSigFuncType" SG_ 987 BCM_01_alt 5;
BA_ "GenSigStartValue" SG_ 987 BCM_01_alt 1;
BA_ "GenSigSendType" SG_ 987 BCM_01_alt 0;
BA_ "GenSigSwitchedByIgnition" SG_ 987 SMLS_01_alt 0;
BA_ "GenSigFuncType" SG_ 987 SMLS_01_alt 5;
BA_ "GenSigStartValue" SG_ 987 SMLS_01_alt 1;
BA_ "GenSigSendType" SG_ 987 SMLS_01_alt 0;
BA_ "GenSigSwitchedByIgnition" SG_ 987 ZV_02_alt 0;
BA_ "GenSigFuncType" SG_ 987 ZV_02_alt 5;
BA_ "GenSigStartValue" SG_ 987 ZV_02_alt 1;
BA_ "GenSigSendType" SG_ 987 ZV_02_alt 0;
BA_ "GenSigSwitchedByIgnition" SG_ 987 Wischer_01_alt 0;
BA_ "GenSigFuncType" SG_ 987 Wischer_01_alt 5;
BA_ "GenSigStartValue" SG_ 987 Wischer_01_alt 1;
BA_ "GenSigSendType" SG_ 987 Wischer_01_alt 0;
BA_ "GenSigSwitchedByIgnition" SG_ 987 Anhaenger_01_alt 0;
BA_ "GenSigFuncType" SG_ 987 Anhaenger_01_alt 5;
BA_ "GenSigStartValue" SG_ 987 Anhaenger_01_alt 1;
BA_ "GenSigSendType" SG_ 987 Anhaenger_01_alt 0;
BA_ "GenSigSwitchedByIgnition" SG_ 987 Klima_Sensor_02_alt 0;
BA_ "GenSigFuncType" SG_ 987 Klima_Sensor_02_alt 5;
BA_ "GenSigStartValue" SG_ 987 Klima_Sensor_02_alt 1;
BA_ "GenSigSendType" SG_ 987 Klima_Sensor_02_alt 0;
BA_ "GenSigSwitchedByIgnition" SG_ 987 Verdeck_01_alt 0;
BA_ "GenSigFuncType" SG_ 987 Verdeck_01_alt 5;
BA_ "GenSigStartValue" SG_ 987 Verdeck_01_alt 1;
BA_ "GenSigSendType" SG_ 987 Verdeck_01_alt 0;
BA_ "GenSigSwitchedByIgnition" SG_ 987 Klima_11_alt 0;
BA_ "GenSigFuncType" SG_ 987 Klima_11_alt 5;
BA_ "GenSigStartValue" SG_ 987 Klima_11_alt 1;
BA_ "GenSigSendType" SG_ 987 Klima_11_alt 0;
BA_ "GenSigSwitchedByIgnition" SG_ 987 WFS_01_alt 0;
BA_ "GenSigFuncType" SG_ 987 WFS_01_alt 5;
BA_ "GenSigStartValue" SG_ 987 WFS_01_alt 1;
BA_ "GenSigSendType" SG_ 987 WFS_01_alt 0;
BA_ "GenSigSwitchedByIgnition" SG_ 987 Licht_Anf_01_alt 0;
BA_ "GenSigFuncType" SG_ 987 Licht_Anf_01_alt 5;
BA_ "GenSigStartValue" SG_ 987 Licht_Anf_01_alt 1;
BA_ "GenSigSendType" SG_ 987 Licht_Anf_01_alt 0;
BA_ "GenSigSwitchedByIgnition" SG_ 987 ZV_verriegelt_extern_soll 0;
BA_ "GenSigSendType" SG_ 987 ZV_verriegelt_extern_soll 0;
BA_ "GenSigSwitchedByIgnition" SG_ 987 BH_Lichthupe 0;
BA_ "GenSigSendType" SG_ 987 BH_Lichthupe 3;
BA_ "GenSigSwitchedByIgnition" SG_ 987 WFS_Klemmenfreigabe 0;
BA_ "GenSigSendType" SG_ 987 WFS_Klemmenfreigabe 0;
BA_ "GenSigSwitchedByIgnition" SG_ 987 ZV_Tankklappe_offen 0;
BA_ "GenSigSendType" SG_ 987 ZV_Tankklappe_offen 0;
BA_ "GenSigSwitchedByIgnition" SG_ 987 AAG_Anhaenger_abgesteckt 0;
BA_ "GenSigSendType" SG_ 987 AAG_Anhaenger_abgesteckt 0;
BA_ "Fehlerwert" SG_ 987 BCM1_LDS_Stellung 7;
BA_ "GenSigSwitchedByIgnition" SG_ 987 BCM1_LDS_Stellung 0;
BA_ "GenSigSendType" SG_ 987 BCM1_LDS_Stellung 3;
BA_ "GenSigSwitchedByIgnition" SG_ 987 VS_Verdeck_Anf 0;
BA_ "GenSigSendType" SG_ 987 VS_Verdeck_Anf 0;
BA_ "GenSigSwitchedByIgnition" SG_ 987 VS_VD_entriegelt 0;
BA_ "GenSigSendType" SG_ 987 VS_VD_entriegelt 0;
BA_ "GenSigSwitchedByIgnition" SG_ 987 ZV_HFS_offen 0;
BA_ "GenSigSendType" SG_ 987 ZV_HFS_offen 3;
BA_ "GenSigSwitchedByIgnition" SG_ 987 ZV_HBFS_offen 0;
BA_ "GenSigSendType" SG_ 987 ZV_HBFS_offen 3;
BA_ "GenSigSwitchedByIgnition" SG_ 987 VS_VD_offen_ver 0;
BA_ "GenSigSendType" SG_ 987 VS_VD_offen_ver 0;
BA_ "GenSigSwitchedByIgnition" SG_ 987 VS_VD_zu_ver 0;
BA_ "GenSigSendType" SG_ 987 VS_VD_zu_ver 0;
BA_ "GenSigSwitchedByIgnition" SG_ 987 ZV_BT_offen 0;
BA_ "GenSigSendType" SG_ 987 ZV_BT_offen 3;
BA_ "GenSigSwitchedByIgnition" SG_ 987 BCM1_Rueckfahrlicht_Schalter 0;
BA_ "GenSigSendType" SG_ 987 BCM1_Rueckfahrlicht_Schalter 3;
BA_ "GenSigSwitchedByIgnition" SG_ 987 ZV_FT_offen 0;
BA_ "GenSigSendType" SG_ 987 ZV_FT_offen 3;
BA_ "GenSigSwitchedByIgnition" SG_ 987 Wischer_vorne_aktiv 0;
BA_ "GenSigSendType" SG_ 987 Wischer_vorne_aktiv 3;
BA_ "GenSigSwitchedByIgnition" SG_ 987 AAG_Anhaenger_erkannt 0;
BA_ "NWM-WakeupAllowed" SG_ 987 AAG_Anhaenger_erkannt 1;
BA_ "GenSigSendType" SG_ 987 AAG_Anhaenger_erkannt 0;
BA_ "GenSigSwitchedByIgnition" SG_ 987 BCM1_MH_Schalter 0;
BA_ "GenSigSendType" SG_ 987 BCM1_MH_Schalter 3;
BA_ "GenSigSwitchedByIgnition" SG_ 987 ZV_HD_offen 0;
BA_ "GenSigSendType" SG_ 987 ZV_HD_offen 3;
BA_ "GenSigSwitchedByIgnition" SG_ 987 Waschen_vorne_aktiv 0;
BA_ "GenSigSendType" SG_ 987 Waschen_vorne_aktiv 3;
BA_ "GenSigSwitchedByIgnition" SG_ 987 KL_Thermomanagement 0;
BA_ "GenSigSendType" SG_ 987 KL_Thermomanagement 0;
BA_ "GenSigSwitchedByIgnition" SG_ 987 WFS_Schluessel_Fahrberecht 0;
BA_ "GenSigSendType" SG_ 987 WFS_Schluessel_Fahrberecht 0;
BA_ "GenSigSwitchedByIgnition" SG_ 987 BCM_Rueckfahrlicht_Anf 0;
BA_ "GenSigSendType" SG_ 987 BCM_Rueckfahrlicht_Anf 0;
BA_ "GenSigSwitchedByIgnition" SG_ 987 WWSs_01_alt 0;
BA_ "GenSigFuncType" SG_ 987 WWSs_01_alt 5;
BA_ "GenSigStartValue" SG_ 987 WWSs_01_alt 1;
BA_ "GenSigSendType" SG_ 987 WWSs_01_alt 3;
BA_ "Fehlerwert" SG_ 987 BCM_Tankklappensteller_Fehler 1;
BA_ "GenSigSwitchedByIgnition" SG_ 987 BCM_Tankklappensteller_Fehler 0;
BA_ "GenSigSendType" SG_ 987 BCM_Tankklappensteller_Fehler 0;
BA_ "GenSigSwitchedByIgnition" SG_ 987 AAG_LED_aktiv 0;
BA_ "GenSigSwitchedByIgnition" SG_ 987 ZV_verriegelt_soll 0;
BA_ "GenSigSwitchedByIgnition" SG_ 987 ZV_Schluessel_Zugang 0;
BA_ "GenSigSendType" SG_ 987 ZV_Schluessel_Zugang 0;
BA_ "GenSigSwitchedByIgnition" SG_ 987 WFS_ID_Geb_autorisiert_in_Kl15 0;
BA_ "GenSigSendType" SG_ 987 WFS_ID_Geb_autorisiert_in_Kl15 0;
BA_ "GenSigSwitchedByIgnition" SG_ 987 BH_Fernlicht 0;
BA_ "GenSigSendType" SG_ 987 BH_Fernlicht 3;
BA_ "GenSigSwitchedByIgnition" SG_ 987 BH_Blinker_li 0;
BA_ "GenSigSendType" SG_ 987 BH_Blinker_li 3;
BA_ "GenSigSwitchedByIgnition" SG_ 987 BH_Blinker_re 0;
BA_ "GenSigSendType" SG_ 987 BH_Blinker_re 3;
BA_ "GenSigSwitchedByIgnition" SG_ 987 BCM1_OBD_FStatus_ATemp 0;
BA_ "GenSigSendType" SG_ 987 BCM1_OBD_FStatus_ATemp 0;
BA_ "Fehlerwert" SG_ 987 BCM1_Aussen_Temp_ungef 255;
BA_ "GenSigSwitchedByIgnition" SG_ 987 BCM1_Aussen_Temp_ungef 0;
BA_ "GenSigStartValue" SG_ 987 BCM1_Aussen_Temp_ungef 254;
BA_ "GenSigSendType" SG_ 987 BCM1_Aussen_Temp_ungef 0;
BA_ "GenSigSwitchedByIgnition" SG_ 2589284280 DU1_KSV_Value_1 0;
BA_ "GenSigSendType" SG_ 2589284280 DU1_KSV_Value_1 3;
BA_ "GenSigSwitchedByIgnition" SG_ 2589284280 DU1_KSV_Value_2 0;
BA_ "GenSigSendType" SG_ 2589284280 DU1_KSV_Value_2 3;
BA_ "Fehlerwert" SG_ 2589284280 DU1_HDCP_Auth_Status_Out_1 5;
BA_ "GenSigSwitchedByIgnition" SG_ 2589284280 DU1_HDCP_Auth_Status_Out_1 0;
BA_ "GenSigStartValue" SG_ 2589284280 DU1_HDCP_Auth_Status_Out_1 7;
BA_ "GenSigSendType" SG_ 2589284280 DU1_HDCP_Auth_Status_Out_1 3;
BA_ "Fehlerwert" SG_ 2589284280 DU1_HDCP_Auth_Status_Out_2 5;
BA_ "GenSigSwitchedByIgnition" SG_ 2589284280 DU1_HDCP_Auth_Status_Out_2 0;
BA_ "GenSigStartValue" SG_ 2589284280 DU1_HDCP_Auth_Status_Out_2 7;
BA_ "GenSigSendType" SG_ 2589284280 DU1_HDCP_Auth_Status_Out_2 3;
BA_ "Fehlerwert" SG_ 2589284280 DU1_HDCP_Auth_Status_Out_3 5;
BA_ "GenSigSwitchedByIgnition" SG_ 2589284280 DU1_HDCP_Auth_Status_Out_3 0;
BA_ "GenSigStartValue" SG_ 2589284280 DU1_HDCP_Auth_Status_Out_3 7;
BA_ "GenSigSendType" SG_ 2589284280 DU1_HDCP_Auth_Status_Out_3 3;
BA_ "Fehlerwert" SG_ 2589284280 DU1_HDCP_Auth_Status_Out_4 5;
BA_ "GenSigSwitchedByIgnition" SG_ 2589284280 DU1_HDCP_Auth_Status_Out_4 0;
BA_ "GenSigStartValue" SG_ 2589284280 DU1_HDCP_Auth_Status_Out_4 7;
BA_ "GenSigSendType" SG_ 2589284280 DU1_HDCP_Auth_Status_Out_4 3;
BA_ "Fehlerwert" SG_ 2589284280 DU1_HDCP_Auth_Status_Out_5 5;
BA_ "GenSigSwitchedByIgnition" SG_ 2589284280 DU1_HDCP_Auth_Status_Out_5 0;
BA_ "GenSigStartValue" SG_ 2589284280 DU1_HDCP_Auth_Status_Out_5 7;
BA_ "GenSigSendType" SG_ 2589284280 DU1_HDCP_Auth_Status_Out_5 3;
BA_ "Fehlerwert" SG_ 2589284280 DU1_HDCP_Auth_Status_Out_6 5;
BA_ "GenSigSwitchedByIgnition" SG_ 2589284280 DU1_HDCP_Auth_Status_Out_6 0;
BA_ "GenSigStartValue" SG_ 2589284280 DU1_HDCP_Auth_Status_Out_6 7;
BA_ "GenSigSendType" SG_ 2589284280 DU1_HDCP_Auth_Status_Out_6 3;
BA_ "Fehlerwert" SG_ 2589284280 DU1_HDCP_Auth_Status_Out_7 5;
BA_ "GenSigSwitchedByIgnition" SG_ 2589284280 DU1_HDCP_Auth_Status_Out_7 0;
BA_ "GenSigStartValue" SG_ 2589284280 DU1_HDCP_Auth_Status_Out_7 7;
BA_ "GenSigSendType" SG_ 2589284280 DU1_HDCP_Auth_Status_Out_7 3;
BA_ "Fehlerwert" SG_ 2589284280 DU1_HDCP_Auth_Status_Out_8 5;
BA_ "GenSigSwitchedByIgnition" SG_ 2589284280 DU1_HDCP_Auth_Status_Out_8 0;
BA_ "GenSigStartValue" SG_ 2589284280 DU1_HDCP_Auth_Status_Out_8 7;
BA_ "GenSigSendType" SG_ 2589284280 DU1_HDCP_Auth_Status_Out_8 3;
BA_ "GenSigSwitchedByIgnition" SG_ 2589284281 DU2_KSV_Value_1 0;
BA_ "GenSigSendType" SG_ 2589284281 DU2_KSV_Value_1 3;
BA_ "GenSigSwitchedByIgnition" SG_ 2589284281 DU2_KSV_Value_2 0;
BA_ "GenSigSendType" SG_ 2589284281 DU2_KSV_Value_2 3;
BA_ "Fehlerwert" SG_ 2589284281 DU2_HDCP_Auth_Status_Out_1 5;
BA_ "GenSigSwitchedByIgnition" SG_ 2589284281 DU2_HDCP_Auth_Status_Out_1 0;
BA_ "GenSigStartValue" SG_ 2589284281 DU2_HDCP_Auth_Status_Out_1 7;
BA_ "GenSigSendType" SG_ 2589284281 DU2_HDCP_Auth_Status_Out_1 3;
BA_ "Fehlerwert" SG_ 2589284281 DU2_HDCP_Auth_Status_Out_2 5;
BA_ "GenSigSwitchedByIgnition" SG_ 2589284281 DU2_HDCP_Auth_Status_Out_2 0;
BA_ "GenSigStartValue" SG_ 2589284281 DU2_HDCP_Auth_Status_Out_2 7;
BA_ "GenSigSendType" SG_ 2589284281 DU2_HDCP_Auth_Status_Out_2 3;
BA_ "Fehlerwert" SG_ 2589284281 DU2_HDCP_Auth_Status_Out_3 5;
BA_ "GenSigSwitchedByIgnition" SG_ 2589284281 DU2_HDCP_Auth_Status_Out_3 0;
BA_ "GenSigStartValue" SG_ 2589284281 DU2_HDCP_Auth_Status_Out_3 7;
BA_ "GenSigSendType" SG_ 2589284281 DU2_HDCP_Auth_Status_Out_3 3;
BA_ "Fehlerwert" SG_ 2589284281 DU2_HDCP_Auth_Status_Out_4 5;
BA_ "GenSigSwitchedByIgnition" SG_ 2589284281 DU2_HDCP_Auth_Status_Out_4 0;
BA_ "GenSigStartValue" SG_ 2589284281 DU2_HDCP_Auth_Status_Out_4 7;
BA_ "GenSigSendType" SG_ 2589284281 DU2_HDCP_Auth_Status_Out_4 3;
BA_ "Fehlerwert" SG_ 2589284281 DU2_HDCP_Auth_Status_Out_5 5;
BA_ "GenSigSwitchedByIgnition" SG_ 2589284281 DU2_HDCP_Auth_Status_Out_5 0;
BA_ "GenSigStartValue" SG_ 2589284281 DU2_HDCP_Auth_Status_Out_5 7;
BA_ "GenSigSendType" SG_ 2589284281 DU2_HDCP_Auth_Status_Out_5 3;
BA_ "Fehlerwert" SG_ 2589284281 DU2_HDCP_Auth_Status_Out_6 5;
BA_ "GenSigSwitchedByIgnition" SG_ 2589284281 DU2_HDCP_Auth_Status_Out_6 0;
BA_ "GenSigStartValue" SG_ 2589284281 DU2_HDCP_Auth_Status_Out_6 7;
BA_ "GenSigSendType" SG_ 2589284281 DU2_HDCP_Auth_Status_Out_6 3;
BA_ "Fehlerwert" SG_ 2589284281 DU2_HDCP_Auth_Status_Out_7 5;
BA_ "GenSigSwitchedByIgnition" SG_ 2589284281 DU2_HDCP_Auth_Status_Out_7 0;
BA_ "GenSigStartValue" SG_ 2589284281 DU2_HDCP_Auth_Status_Out_7 7;
BA_ "GenSigSendType" SG_ 2589284281 DU2_HDCP_Auth_Status_Out_7 3;
BA_ "Fehlerwert" SG_ 2589284281 DU2_HDCP_Auth_Status_Out_8 5;
BA_ "GenSigSwitchedByIgnition" SG_ 2589284281 DU2_HDCP_Auth_Status_Out_8 0;
BA_ "GenSigStartValue" SG_ 2589284281 DU2_HDCP_Auth_Status_Out_8 7;
BA_ "GenSigSendType" SG_ 2589284281 DU2_HDCP_Auth_Status_Out_8 3;
BA_ "GenSigSwitchedByIgnition" SG_ 2589284283 DU3_KSV_Value_1 0;
BA_ "GenSigSendType" SG_ 2589284283 DU3_KSV_Value_1 3;
BA_ "GenSigSwitchedByIgnition" SG_ 2589284283 DU3_KSV_Value_2 0;
BA_ "GenSigSendType" SG_ 2589284283 DU3_KSV_Value_2 3;
BA_ "Fehlerwert" SG_ 2589284283 DU3_HDCP_Auth_Status_Out_1 5;
BA_ "GenSigSwitchedByIgnition" SG_ 2589284283 DU3_HDCP_Auth_Status_Out_1 0;
BA_ "GenSigStartValue" SG_ 2589284283 DU3_HDCP_Auth_Status_Out_1 7;
BA_ "GenSigSendType" SG_ 2589284283 DU3_HDCP_Auth_Status_Out_1 3;
BA_ "Fehlerwert" SG_ 2589284283 DU3_HDCP_Auth_Status_Out_2 5;
BA_ "GenSigSwitchedByIgnition" SG_ 2589284283 DU3_HDCP_Auth_Status_Out_2 0;
BA_ "GenSigStartValue" SG_ 2589284283 DU3_HDCP_Auth_Status_Out_2 7;
BA_ "GenSigSendType" SG_ 2589284283 DU3_HDCP_Auth_Status_Out_2 3;
BA_ "Fehlerwert" SG_ 2589284283 DU3_HDCP_Auth_Status_Out_3 5;
BA_ "GenSigSwitchedByIgnition" SG_ 2589284283 DU3_HDCP_Auth_Status_Out_3 0;
BA_ "GenSigStartValue" SG_ 2589284283 DU3_HDCP_Auth_Status_Out_3 7;
BA_ "GenSigSendType" SG_ 2589284283 DU3_HDCP_Auth_Status_Out_3 3;
BA_ "Fehlerwert" SG_ 2589284283 DU3_HDCP_Auth_Status_Out_4 5;
BA_ "GenSigSwitchedByIgnition" SG_ 2589284283 DU3_HDCP_Auth_Status_Out_4 0;
BA_ "GenSigStartValue" SG_ 2589284283 DU3_HDCP_Auth_Status_Out_4 7;
BA_ "GenSigSendType" SG_ 2589284283 DU3_HDCP_Auth_Status_Out_4 3;
BA_ "Fehlerwert" SG_ 2589284283 DU3_HDCP_Auth_Status_Out_5 5;
BA_ "GenSigSwitchedByIgnition" SG_ 2589284283 DU3_HDCP_Auth_Status_Out_5 0;
BA_ "GenSigStartValue" SG_ 2589284283 DU3_HDCP_Auth_Status_Out_5 7;
BA_ "GenSigSendType" SG_ 2589284283 DU3_HDCP_Auth_Status_Out_5 3;
BA_ "Fehlerwert" SG_ 2589284283 DU3_HDCP_Auth_Status_Out_6 5;
BA_ "GenSigSwitchedByIgnition" SG_ 2589284283 DU3_HDCP_Auth_Status_Out_6 0;
BA_ "GenSigStartValue" SG_ 2589284283 DU3_HDCP_Auth_Status_Out_6 7;
BA_ "GenSigSendType" SG_ 2589284283 DU3_HDCP_Auth_Status_Out_6 3;
BA_ "Fehlerwert" SG_ 2589284283 DU3_HDCP_Auth_Status_Out_7 5;
BA_ "GenSigSwitchedByIgnition" SG_ 2589284283 DU3_HDCP_Auth_Status_Out_7 0;
BA_ "GenSigStartValue" SG_ 2589284283 DU3_HDCP_Auth_Status_Out_7 7;
BA_ "GenSigSendType" SG_ 2589284283 DU3_HDCP_Auth_Status_Out_7 3;
BA_ "Fehlerwert" SG_ 2589284283 DU3_HDCP_Auth_Status_Out_8 5;
BA_ "GenSigSwitchedByIgnition" SG_ 2589284283 DU3_HDCP_Auth_Status_Out_8 0;
BA_ "GenSigStartValue" SG_ 2589284283 DU3_HDCP_Auth_Status_Out_8 7;
BA_ "GenSigSendType" SG_ 2589284283 DU3_HDCP_Auth_Status_Out_8 3;
BA_ "GenSigSwitchedByIgnition" SG_ 2549674355 HID_ABT_1_ZR_Req_Data 0;
BA_ "GenSigSendType" SG_ 2549674355 HID_ABT_1_ZR_Req_Data 3;
BA_ "GenSigSwitchedByIgnition" SG_ 2549773297 HID_ABT_1_ZR_Resp_Data 0;
BA_ "GenSigSendType" SG_ 2549773297 HID_ABT_1_ZR_Resp_Data 3;
BA_ "GenSigSwitchedByIgnition" SG_ 2549674099 HID_BT_1_ZR_Req_Data 0;
BA_ "GenSigSendType" SG_ 2549674099 HID_BT_1_ZR_Req_Data 3;
BA_ "GenSigSwitchedByIgnition" SG_ 2549773296 HID_BT_1_ZR_Resp_Data 0;
BA_ "GenSigFuncType" SG_ 2549773296 HID_BT_1_ZR_Resp_Data 9;
BA_ "GenSigSendType" SG_ 2549773296 HID_BT_1_ZR_Resp_Data 3;
BA_ "GenSigSwitchedByIgnition" SG_ 2549674611 HID_DU_1_ZR_Req_Data 0;
BA_ "GenSigSendType" SG_ 2549674611 HID_DU_1_ZR_Req_Data 3;
BA_ "GenSigSwitchedByIgnition" SG_ 2549773298 HID_DU_1_ZR_Resp_Data 0;
BA_ "GenSigFuncType" SG_ 2549773298 HID_DU_1_ZR_Resp_Data 9;
BA_ "GenSigSendType" SG_ 2549773298 HID_DU_1_ZR_Resp_Data 3;
BA_ "GenSigSwitchedByIgnition" SG_ 2549675379 HID_DU_2_ZR_Req_Data 0;
BA_ "GenSigSwitchedByIgnition" SG_ 2549773301 HID_DU_2_ZR_Resp_Data 0;
BA_ "GenSigFuncType" SG_ 2549773301 HID_DU_2_ZR_Resp_Data 9;
BA_ "GenSigSwitchedByIgnition" SG_ 2549677683 HID_DU_3_ZR_Req_Data 0;
BA_ "GenSigSwitchedByIgnition" SG_ 2549808755 HID_DU_3_ZR_Resp_Data 0;
BA_ "GenSigSwitchedByIgnition" SG_ 2549675123 HID_DU_4_ZR_Req_Data 0;
BA_ "GenSigSendType" SG_ 2549675123 HID_DU_4_ZR_Req_Data 3;
BA_ "GenSigSwitchedByIgnition" SG_ 2549773300 HID_DU_4_ZR_Resp_Data 0;
BA_ "GenSigSendType" SG_ 2549773300 HID_DU_4_ZR_Resp_Data 3;
BA_ "GenSigSwitchedByIgnition" SG_ 2549675635 HID_LSR_1_ZR_Req 0;
BA_ "GenSigSwitchedByIgnition" SG_ 2549773302 HID_LSR_1_ZR_Resp 0;
BA_ "GenSigSwitchedByIgnition" SG_ 2549656179 HID_SCC1_ZR_Req_Data 0;
BA_ "GenSigSendType" SG_ 2549656179 HID_SCC1_ZR_Req_Data 3;
BA_ "GenSigSwitchedByIgnition" SG_ 2549787251 HID_SCC1_ZR_Resp_Data 0;
BA_ "GenSigSendType" SG_ 2549787251 HID_SCC1_ZR_Resp_Data 3;
BA_ "GenSigSwitchedByIgnition" SG_ 2549656435 HID_SCC2_ZR_Req_Data 0;
BA_ "GenSigSendType" SG_ 2549656435 HID_SCC2_ZR_Req_Data 3;
BA_ "GenSigSwitchedByIgnition" SG_ 2549787507 HID_SCC2_ZR_Resp_Data 0;
BA_ "GenSigSendType" SG_ 2549787507 HID_SCC2_ZR_Resp_Data 3;
BA_ "GenSigSwitchedByIgnition" SG_ 2549655411 HID_SDC1_ZR_Req_Data 0;
BA_ "GenSigSendType" SG_ 2549655411 HID_SDC1_ZR_Req_Data 3;
BA_ "GenSigSwitchedByIgnition" SG_ 2549786483 HID_SDC1_ZR_Resp_Data 0;
BA_ "GenSigSendType" SG_ 2549786483 HID_SDC1_ZR_Resp_Data 3;
BA_ "GenSigSwitchedByIgnition" SG_ 2549655667 HID_SDC2_ZR_Req_Data 0;
BA_ "GenSigSendType" SG_ 2549655667 HID_SDC2_ZR_Req_Data 3;
BA_ "GenSigSwitchedByIgnition" SG_ 2549786739 HID_SDC2_ZR_Resp_Data 0;
BA_ "GenSigSendType" SG_ 2549786739 HID_SDC2_ZR_Resp_Data 3;
BA_ "GenSigSwitchedByIgnition" SG_ 2549642225 HID_ZR_ABT_1_Req_Data 0;
BA_ "GenSigSendType" SG_ 2549642225 HID_ZR_ABT_1_Req_Data 3;
BA_ "GenSigSwitchedByIgnition" SG_ 2549805427 HID_ZR_ABT_1_Resp_Data 0;
BA_ "GenSigSendType" SG_ 2549805427 HID_ZR_ABT_1_Resp_Data 3;
BA_ "GenSigSwitchedByIgnition" SG_ 2549642224 HID_ZR_BT_1_Req_Data 0;
BA_ "GenSigSendType" SG_ 2549642224 HID_ZR_BT_1_Req_Data 3;
BA_ "GenSigSwitchedByIgnition" SG_ 2549805171 HID_ZR_BT_1_Resp_Data 0;
BA_ "GenSigFuncType" SG_ 2549805171 HID_ZR_BT_1_Resp_Data 9;
BA_ "GenSigSendType" SG_ 2549805171 HID_ZR_BT_1_Resp_Data 3;
BA_ "GenSigSwitchedByIgnition" SG_ 2549642226 HID_ZR_DU_1_Req_Data 0;
BA_ "GenSigSendType" SG_ 2549642226 HID_ZR_DU_1_Req_Data 3;
BA_ "GenSigSwitchedByIgnition" SG_ 2549805683 HID_ZR_DU_1_Resp_Data 0;
BA_ "GenSigFuncType" SG_ 2549805683 HID_ZR_DU_1_Resp_Data 9;
BA_ "GenSigSendType" SG_ 2549805683 HID_ZR_DU_1_Resp_Data 3;
BA_ "GenSigSwitchedByIgnition" SG_ 2549642229 HID_ZR_DU_2_Req_Data 0;
BA_ "GenSigSwitchedByIgnition" SG_ 2549806451 HID_ZR_DU_2_Resp_Data 0;
BA_ "GenSigFuncType" SG_ 2549806451 HID_ZR_DU_2_Resp_Data 9;
BA_ "GenSigSwitchedByIgnition" SG_ 2549642238 HID_ZR_DU_3_Req_Data 0;
BA_ "GenSigSwitchedByIgnition" SG_ 2549773310 HID_ZR_DU_3_Resp_Data 0;
BA_ "GenSigSwitchedByIgnition" SG_ 2549642228 HID_ZR_DU_4_Req_Data 0;
BA_ "GenSigSendType" SG_ 2549642228 HID_ZR_DU_4_Req_Data 3;
BA_ "GenSigSwitchedByIgnition" SG_ 2549806195 HID_ZR_DU_4_Resp_Data 0;
BA_ "GenSigSendType" SG_ 2549806195 HID_ZR_DU_4_Resp_Data 3;
BA_ "GenSigSwitchedByIgnition" SG_ 2549642230 HID_ZR_LSR_1_Req 0;
BA_ "GenSigSwitchedByIgnition" SG_ 2549806707 HID_ZR_LSR_1_Resp 0;
BA_ "GenSigSwitchedByIgnition" SG_ 2549642154 HID_ZR_SCC_01_Req_Data 0;
BA_ "GenSigSendType" SG_ 2549642154 HID_ZR_SCC_01_Req_Data 3;
BA_ "GenSigSwitchedByIgnition" SG_ 2549773226 HID_ZR_SCC_01_Resp_Data 0;
BA_ "GenSigSendType" SG_ 2549773226 HID_ZR_SCC_01_Resp_Data 3;
BA_ "GenSigSwitchedByIgnition" SG_ 2549642155 HID_ZR_SCC_02_Req_Data 0;
BA_ "GenSigSendType" SG_ 2549642155 HID_ZR_SCC_02_Req_Data 3;
BA_ "GenSigSwitchedByIgnition" SG_ 2549773227 HID_ZR_SCC_02_Resp_Data 0;
BA_ "GenSigSendType" SG_ 2549773227 HID_ZR_SCC_02_Resp_Data 3;
BA_ "GenSigSwitchedByIgnition" SG_ 2549642151 HID_ZR_SDC1_Req_Data 0;
BA_ "GenSigSendType" SG_ 2549642151 HID_ZR_SDC1_Req_Data 3;
BA_ "GenSigSwitchedByIgnition" SG_ 2549773223 HID_ZR_SDC1_Resp_Data 0;
BA_ "GenSigSendType" SG_ 2549773223 HID_ZR_SDC1_Resp_Data 3;
BA_ "GenSigSwitchedByIgnition" SG_ 2549642152 HID_ZR_SDC2_Req_Data 0;
BA_ "GenSigSendType" SG_ 2549642152 HID_ZR_SDC2_Req_Data 3;
BA_ "GenSigSwitchedByIgnition" SG_ 2549773224 HID_ZR_SDC2_Resp_Data 0;
BA_ "GenSigSendType" SG_ 2549773224 HID_ZR_SDC2_Resp_Data 3;
BA_ "GenSigSwitchedByIgnition" SG_ 1792 ISO_ALL_01_Req_Data 0;
BA_ "GenSigFuncType" SG_ 1792 ISO_ALL_01_Req_Data 9;
BA_ "GenSigSendType" SG_ 1792 ISO_ALL_01_Req_Data 3;
BA_ "GenSigSwitchedByIgnition" SG_ 2549874858 ISOx_SCC1_Req_Data 0;
BA_ "GenSigSwitchedByIgnition" SG_ 2550005930 ISOx_SCC1_Resp_Data 0;
BA_ "GenSigSwitchedByIgnition" SG_ 2549874859 ISOx_SCC2_Req_Data 0;
BA_ "GenSigSwitchedByIgnition" SG_ 2550005931 ISOx_SCC2_Resp_Data 0;
BA_ "GenSigSwitchedByIgnition" SG_ 2549874855 ISOx_SDC1_Req_Data 0;
BA_ "GenSigSendType" SG_ 2549874855 ISOx_SDC1_Req_Data 3;
BA_ "GenSigSwitchedByIgnition" SG_ 2550005927 ISOx_SDC1_Resp_Data 0;
BA_ "GenSigSendType" SG_ 2550005927 ISOx_SDC1_Resp_Data 3;
BA_ "GenSigSwitchedByIgnition" SG_ 2549874856 ISOx_SDC2_Req_Data 0;
BA_ "GenSigSendType" SG_ 2549874856 ISOx_SDC2_Req_Data 3;
BA_ "GenSigSwitchedByIgnition" SG_ 2550005928 ISOx_SDC2_Resp_Data 0;
BA_ "GenSigSendType" SG_ 2550005928 ISOx_SDC2_Resp_Data 3;
BA_ "GenSigSwitchedByIgnition" SG_ 2549874853 ISOx_WLC1_Req_Data 0;
BA_ "GenSigSwitchedByIgnition" SG_ 2550005925 ISOx_WLC1_Resp_Data 0;
BA_ "GenSigSwitchedByIgnition" SG_ 2549874854 ISOx_WLC2_Req_Data 0;
BA_ "GenSigSwitchedByIgnition" SG_ 2550005926 ISOx_WLC2_Resp_Data 0;
BA_ "GenSigSwitchedByIgnition" SG_ 960 Klemmen_Status_01_CRC 0;
BA_ "GenSigFuncType" SG_ 960 Klemmen_Status_01_CRC 2;
BA_ "GenSigSendType" SG_ 960 Klemmen_Status_01_CRC 0;
BA_ "GenSigSwitchedByIgnition" SG_ 960 Klemmen_Status_01_BZ 0;
BA_ "GenSigFuncType" SG_ 960 Klemmen_Status_01_BZ 1;
BA_ "GenSigSendType" SG_ 960 Klemmen_Status_01_BZ 0;
BA_ "GenSigSwitchedByIgnition" SG_ 960 RSt_Fahrerhinweise 0;
BA_ "GenSigSendType" SG_ 960 RSt_Fahrerhinweise 3;
BA_ "GenSigSwitchedByIgnition" SG_ 960 ZAS_Kl_S 0;
BA_ "GenSigSendType" SG_ 960 ZAS_Kl_S 3;
BA_ "GenSigSwitchedByIgnition" SG_ 960 ZAS_Kl_15 0;
BA_ "GenSigFuncType" SG_ 960 ZAS_Kl_15 6;
BA_ "NWM-WakeupAllowed" SG_ 960 ZAS_Kl_15 1;
BA_ "GenSigSendType" SG_ 960 ZAS_Kl_15 3;
BA_ "GenSigSwitchedByIgnition" SG_ 960 ZAS_Kl_X 0;
BA_ "GenSigSendType" SG_ 960 ZAS_Kl_X 3;
BA_ "GenSigSwitchedByIgnition" SG_ 960 ZAS_Kl_50_Startanforderung 0;
BA_ "GenSigSendType" SG_ 960 ZAS_Kl_50_Startanforderung 3;
BA_ "GenSigSwitchedByIgnition" SG_ 960 BCM_Remotestart_Betrieb 0;
BA_ "GenSigSendType" SG_ 960 BCM_Remotestart_Betrieb 3;
BA_ "GenSigSwitchedByIgnition" SG_ 960 ZAS_Kl_Infotainment 0;
BA_ "GenSigSendType" SG_ 960 ZAS_Kl_Infotainment 3;
BA_ "GenSigSwitchedByIgnition" SG_ 960 BCM_Remotestart_KL15_Anf 0;
BA_ "GenSigSendType" SG_ 960 BCM_Remotestart_KL15_Anf 3;
BA_ "GenSigSwitchedByIgnition" SG_ 960 BCM_Remotestart_MO_Start 0;
BA_ "GenSigSendType" SG_ 960 BCM_Remotestart_MO_Start 3;
BA_ "GenSigSwitchedByIgnition" SG_ 960 KST_Warn_P1_ZST_def 0;
BA_ "GenSigSendType" SG_ 960 KST_Warn_P1_ZST_def 3;
BA_ "GenSigSwitchedByIgnition" SG_ 960 KST_Warn_P2_ZST_def 0;
BA_ "GenSigSendType" SG_ 960 KST_Warn_P2_ZST_def 3;
BA_ "GenSigSwitchedByIgnition" SG_ 960 KST_Fahrerhinweis_1 0;
BA_ "GenSigSendType" SG_ 960 KST_Fahrerhinweis_1 3;
BA_ "GenSigSwitchedByIgnition" SG_ 960 KST_Fahrerhinweis_2 0;
BA_ "GenSigSendType" SG_ 960 KST_Fahrerhinweis_2 3;
BA_ "GenSigSwitchedByIgnition" SG_ 960 BCM_Ausparken_Betrieb 0;
BA_ "GenSigSendType" SG_ 960 BCM_Ausparken_Betrieb 3;
BA_ "GenSigSwitchedByIgnition" SG_ 960 KST_Fahrerhinweis_4 0;
BA_ "GenSigSendType" SG_ 960 KST_Fahrerhinweis_4 3;
BA_ "GenSigSwitchedByIgnition" SG_ 960 KST_Fahrerhinweis_5 0;
BA_ "GenSigSendType" SG_ 960 KST_Fahrerhinweis_5 3;
BA_ "GenSigSwitchedByIgnition" SG_ 960 KST_Fahrerhinweis_6 0;
BA_ "GenSigSendType" SG_ 960 KST_Fahrerhinweis_6 3;
BA_ "GenSigSwitchedByIgnition" SG_ 2549088276 Kombi_KompSchutz 0;
BA_ "GenSigSendType" SG_ 2549088276 Kombi_KompSchutz 0;
BA_ "GenSigSwitchedByIgnition" SG_ 2549088276 Kombi_Abschaltstufe 0;
BA_ "GenSigSendType" SG_ 2549088276 Kombi_Abschaltstufe 0;
BA_ "GenSigSwitchedByIgnition" SG_ 2549088276 Kombi_Transport_Mode 0;
BA_ "GenSigSendType" SG_ 2549088276 Kombi_Transport_Mode 0;
BA_ "GenSigSwitchedByIgnition" SG_ 2549088276 Kombi_Nachlauftyp 0;
BA_ "GenSigStartValue" SG_ 2549088276 Kombi_Nachlauftyp 2;
BA_ "GenSigSendType" SG_ 2549088276 Kombi_Nachlauftyp 0;
BA_ "GenSigSwitchedByIgnition" SG_ 2549088276 Kombi_SNI 0;
BA_ "GenSigStartValue" SG_ 2549088276 Kombi_SNI 20;
BA_ "GenSigSendType" SG_ 2549088276 Kombi_SNI 0;
BA_ "GenSigSwitchedByIgnition" SG_ 2549088276 KN_KBI_DiagPfad 0;
BA_ "GenSigSendType" SG_ 2549088276 KN_KBI_DiagPfad 0;
BA_ "GenSigSwitchedByIgnition" SG_ 2549088276 KBI_KD_Fehler 0;
BA_ "GenSigSendType" SG_ 2549088276 KBI_KD_Fehler 0;
BA_ "GenSigSwitchedByIgnition" SG_ 2549088426 SCC1_KompSchutz 0;
BA_ "GenSigSendType" SG_ 2549088426 SCC1_KompSchutz 0;
BA_ "GenSigSwitchedByIgnition" SG_ 2549088426 SCC1_Abschaltstufe 0;
BA_ "GenSigSendType" SG_ 2549088426 SCC1_Abschaltstufe 0;
BA_ "GenSigSwitchedByIgnition" SG_ 2549088426 SCC1_Transport_Mode 0;
BA_ "GenSigSendType" SG_ 2549088426 SCC1_Transport_Mode 0;
BA_ "GenSigSwitchedByIgnition" SG_ 2549088426 SCC1_Nachlauftyp 0;
BA_ "GenSigStartValue" SG_ 2549088426 SCC1_Nachlauftyp 2;
BA_ "GenSigSendType" SG_ 2549088426 SCC1_Nachlauftyp 0;
BA_ "GenSigSwitchedByIgnition" SG_ 2549088426 SCC1_SNI 0;
BA_ "GenSigStartValue" SG_ 2549088426 SCC1_SNI 170;
BA_ "GenSigSendType" SG_ 2549088426 SCC1_SNI 0;
BA_ "GenSigSwitchedByIgnition" SG_ 2549088426 KN_SCC1_BusKnockOutTimer 0;
BA_ "GenSigStartValue" SG_ 2549088426 KN_SCC1_BusKnockOutTimer 255;
BA_ "GenSigSendType" SG_ 2549088426 KN_SCC1_BusKnockOutTimer 0;
BA_ "GenSigSwitchedByIgnition" SG_ 2549088426 NM_SCC1_Wakeup 0;
BA_ "GenSigSwitchedByIgnition" SG_ 2549088426 NM_SCC1_Lokalaktiv 0;
BA_ "GenSigSendType" SG_ 2549088426 NM_SCC1_Lokalaktiv 0;
BA_ "GenSigSwitchedByIgnition" SG_ 2549088426 SCC1_KD_Fehler 0;
BA_ "GenSigSendType" SG_ 2549088426 SCC1_KD_Fehler 0;
BA_ "GenSigSwitchedByIgnition" SG_ 2549088427 SCC2_KompSchutz 0;
BA_ "GenSigSendType" SG_ 2549088427 SCC2_KompSchutz 0;
BA_ "GenSigSwitchedByIgnition" SG_ 2549088427 SCC2_Abschaltstufe 0;
BA_ "GenSigSendType" SG_ 2549088427 SCC2_Abschaltstufe 0;
BA_ "GenSigSwitchedByIgnition" SG_ 2549088427 SCC2_Transport_Mode 0;
BA_ "GenSigSendType" SG_ 2549088427 SCC2_Transport_Mode 0;
BA_ "GenSigSwitchedByIgnition" SG_ 2549088427 SCC2_Nachlauftyp 0;
BA_ "GenSigStartValue" SG_ 2549088427 SCC2_Nachlauftyp 2;
BA_ "GenSigSendType" SG_ 2549088427 SCC2_Nachlauftyp 0;
BA_ "GenSigSwitchedByIgnition" SG_ 2549088427 SCC2_SNI 0;
BA_ "GenSigStartValue" SG_ 2549088427 SCC2_SNI 171;
BA_ "GenSigSendType" SG_ 2549088427 SCC2_SNI 0;
BA_ "GenSigSwitchedByIgnition" SG_ 2549088427 KN_SCC2_BusKnockOutTimer 0;
BA_ "GenSigStartValue" SG_ 2549088427 KN_SCC2_BusKnockOutTimer 255;
BA_ "GenSigSendType" SG_ 2549088427 KN_SCC2_BusKnockOutTimer 0;
BA_ "GenSigSwitchedByIgnition" SG_ 2549088427 NM_SCC2_Wakeup 0;
BA_ "GenSigSwitchedByIgnition" SG_ 2549088427 NM_SCC2_Lokalaktiv 0;
BA_ "GenSigSendType" SG_ 2549088427 NM_SCC2_Lokalaktiv 0;
BA_ "GenSigSwitchedByIgnition" SG_ 2549088427 SCC2_KD_Fehler 0;
BA_ "GenSigSendType" SG_ 2549088427 SCC2_KD_Fehler 0;
BA_ "GenSigSwitchedByIgnition" SG_ 2549088423 SDC1_KompSchutz 0;
BA_ "GenSigSendType" SG_ 2549088423 SDC1_KompSchutz 0;
BA_ "GenSigSwitchedByIgnition" SG_ 2549088423 SDC1_Abschaltstufe 0;
BA_ "GenSigSendType" SG_ 2549088423 SDC1_Abschaltstufe 0;
BA_ "GenSigSwitchedByIgnition" SG_ 2549088423 SDC1_Transport_Mode 0;
BA_ "GenSigSendType" SG_ 2549088423 SDC1_Transport_Mode 0;
BA_ "GenSigSwitchedByIgnition" SG_ 2549088423 SDC1_Nachlauftyp 0;
BA_ "GenSigStartValue" SG_ 2549088423 SDC1_Nachlauftyp 2;
BA_ "GenSigSendType" SG_ 2549088423 SDC1_Nachlauftyp 0;
BA_ "GenSigSwitchedByIgnition" SG_ 2549088423 SDC1_SNI 0;
BA_ "GenSigStartValue" SG_ 2549088423 SDC1_SNI 167;
BA_ "GenSigSendType" SG_ 2549088423 SDC1_SNI 0;
BA_ "GenSigSwitchedByIgnition" SG_ 2549088423 KN_SDC1_BusKnockOutTimer 0;
BA_ "GenSigStartValue" SG_ 2549088423 KN_SDC1_BusKnockOutTimer 255;
BA_ "GenSigSendType" SG_ 2549088423 KN_SDC1_BusKnockOutTimer 0;
BA_ "GenSigSwitchedByIgnition" SG_ 2549088423 NM_SDC1_Wakeup 0;
BA_ "GenSigSwitchedByIgnition" SG_ 2549088423 NM_SDC1_Lokalaktiv 0;
BA_ "GenSigSendType" SG_ 2549088423 NM_SDC1_Lokalaktiv 0;
BA_ "GenSigSwitchedByIgnition" SG_ 2549088423 SDC1_KD_Fehler 0;
BA_ "GenSigSendType" SG_ 2549088423 SDC1_KD_Fehler 0;
BA_ "GenSigSwitchedByIgnition" SG_ 2549088424 SDC2_KompSchutz 0;
BA_ "GenSigSendType" SG_ 2549088424 SDC2_KompSchutz 0;
BA_ "GenSigSwitchedByIgnition" SG_ 2549088424 SDC2_Abschaltstufe 0;
BA_ "GenSigSendType" SG_ 2549088424 SDC2_Abschaltstufe 0;
BA_ "GenSigSwitchedByIgnition" SG_ 2549088424 SDC2_Transport_Mode 0;
BA_ "GenSigSendType" SG_ 2549088424 SDC2_Transport_Mode 0;
BA_ "GenSigSwitchedByIgnition" SG_ 2549088424 SDC2_Nachlauftyp 0;
BA_ "GenSigStartValue" SG_ 2549088424 SDC2_Nachlauftyp 2;
BA_ "GenSigSendType" SG_ 2549088424 SDC2_Nachlauftyp 0;
BA_ "GenSigSwitchedByIgnition" SG_ 2549088424 SDC2_SNI 0;
BA_ "GenSigStartValue" SG_ 2549088424 SDC2_SNI 168;
BA_ "GenSigSendType" SG_ 2549088424 SDC2_SNI 0;
BA_ "GenSigSwitchedByIgnition" SG_ 2549088424 KN_SDC2_BusKnockOutTimer 0;
BA_ "GenSigStartValue" SG_ 2549088424 KN_SDC2_BusKnockOutTimer 255;
BA_ "GenSigSendType" SG_ 2549088424 KN_SDC2_BusKnockOutTimer 0;
BA_ "GenSigSwitchedByIgnition" SG_ 2549088424 NM_SDC2_Wakeup 0;
BA_ "GenSigSwitchedByIgnition" SG_ 2549088424 NM_SDC2_Lokalaktiv 0;
BA_ "GenSigSendType" SG_ 2549088424 NM_SDC2_Lokalaktiv 0;
BA_ "GenSigSwitchedByIgnition" SG_ 2549088424 SDC2_KD_Fehler 0;
BA_ "GenSigSendType" SG_ 2549088424 SDC2_KD_Fehler 0;
BA_REL_ "GenSigTimeoutTime" BU_SG_REL_ ZR_High SG_ 2589283759 DU3_Betriebsdauer_min 5000;
BA_REL_ "GenSigTimeoutTime" BU_SG_REL_ ZR_MIB_TOP_ab_Gen3 SG_ 2589283759 DU3_Betriebsdauer_min 5000;
BA_REL_ "GenSigTimeoutTime" BU_SG_REL_ ZR_High SG_ 2589283759 DU3_Betriebsdauer_std 5000;
BA_REL_ "GenSigTimeoutTime" BU_SG_REL_ ZR_MIB_TOP_ab_Gen3 SG_ 2589283759 DU3_Betriebsdauer_std 5000;
BA_REL_ "GenSigTimeoutTime" BU_SG_REL_ ZR_High SG_ 2589283759 DU3_HintGrdBelKurzschl 5000;
BA_REL_ "GenSigTimeoutTime" BU_SG_REL_ ZR_MIB_TOP_ab_Gen3 SG_ 2589283759 DU3_HintGrdBelKurzschl 5000;
BA_REL_ "GenSigTimeoutTime" BU_SG_REL_ ZR_High SG_ 2589283759 DU3_HintGrdBelUnterbr 5000;
BA_REL_ "GenSigTimeoutTime" BU_SG_REL_ ZR_MIB_TOP_ab_Gen3 SG_ 2589283759 DU3_HintGrdBelUnterbr 5000;
BA_REL_ "GenSigTimeoutTime" BU_SG_REL_ ZR_High SG_ 2589283759 DU3_EEPROM_Fehler 5000;
BA_REL_ "GenSigTimeoutTime" BU_SG_REL_ ZR_MIB_TOP_ab_Gen3 SG_ 2589283759 DU3_EEPROM_Fehler 5000;
BA_REL_ "GenSigTimeoutTime" BU_SG_REL_ ZR_High SG_ 2589283759 DU3_SW_inkonsistent 5000;
BA_REL_ "GenSigTimeoutTime" BU_SG_REL_ ZR_MIB_TOP_ab_Gen3 SG_ 2589283759 DU3_SW_inkonsistent 5000;
BA_REL_ "GenSigTimeoutTime" BU_SG_REL_ ZR_High SG_ 2589283759 DU3_HDCP_Status 5000;
BA_REL_ "GenSigTimeoutTime" BU_SG_REL_ ZR_MIB_TOP_ab_Gen3 SG_ 2589283759 DU3_HDCP_Status 5000;
BA_REL_ "GenSigTimeoutTime" BU_SG_REL_ ZR_High SG_ 2589283759 DU3_LVDS_Status 5000;
BA_REL_ "GenSigTimeoutTime" BU_SG_REL_ ZR_MIB_TOP_ab_Gen3 SG_ 2589283759 DU3_LVDS_Status 5000;
BA_REL_ "GenSigTimeoutTime" BU_SG_REL_ ZR_High SG_ 2589283759 DU3_ZR_Lenkerpos_Status 5000;
BA_REL_ "GenSigTimeoutTime" BU_SG_REL_ ZR_MIB_TOP_ab_Gen3 SG_ 2589283759 DU3_ZR_Lenkerpos_Status 5000;
BA_REL_ "GenSigTimeoutTime" BU_SG_REL_ ZR_High SG_ 2589283759 DU3_Touch_Fehlerstatus 5000;
BA_REL_ "GenSigTimeoutTime" BU_SG_REL_ ZR_MIB_TOP_ab_Gen3 SG_ 2589283759 DU3_Touch_Fehlerstatus 5000;
BA_REL_ "GenSigTimeoutTime" BU_SG_REL_ ZR_High SG_ 2589283759 DU3_Haptik_Fehlerstatus 5000;
BA_REL_ "GenSigTimeoutTime" BU_SG_REL_ ZR_MIB_TOP_ab_Gen3 SG_ 2589283759 DU3_Haptik_Fehlerstatus 5000;
BA_REL_ "GenSigTimeoutTime" BU_SG_REL_ ExBox SG_ 1603 KBI_Einheit_Datum 5000;
BA_REL_ "GenSigTimeoutTime" BU_SG_REL_ ExBox SG_ 1603 KBI_Einheit_Streckenanz 5000;
BA_REL_ "GenSigTimeoutTime" BU_SG_REL_ ExBox SG_ 1603 KBI_MFA_v_Einheit_02 5000;
BA_REL_ "GenSigTimeoutTime" BU_SG_REL_ ExBox SG_ 1603 KBI_Einheit_Temp 5000;
BA_REL_ "GenSigTimeoutTime" BU_SG_REL_ ExBox SG_ 1603 KBI_Einheit_Uhrzeit 5000;
BA_REL_ "GenSigTimeoutTime" BU_SG_REL_ ExBox SG_ 1603 KBI_Einheit_Verbrauch 5000;
BA_REL_ "GenSigTimeoutTime" BU_SG_REL_ ExBox SG_ 1603 KBI_Einheit_Volumen 5000;
BA_REL_ "GenSigTimeoutTime" BU_SG_REL_ ExBox SG_ 1603 KBI_Einheit_Sprache 5000;
BA_REL_ "GenSigTimeoutTime" BU_SG_REL_ ExBox SG_ 278 ESP_10_BZ 2000;
BA_REL_ "GenSigTimeoutTime" BU_SG_REL_ ExBox SG_ 278 ESP_QBit_Wegimpuls_VL 2000;
BA_REL_ "GenSigTimeoutTime" BU_SG_REL_ ExBox SG_ 278 ESP_QBit_Wegimpuls_VR 2000;
BA_REL_ "GenSigTimeoutTime" BU_SG_REL_ ExBox SG_ 278 ESP_QBit_Wegimpuls_HL 2000;
BA_REL_ "GenSigTimeoutTime" BU_SG_REL_ ExBox SG_ 278 ESP_QBit_Wegimpuls_HR 2000;
BA_REL_ "GenSigTimeoutTime" BU_SG_REL_ ExBox SG_ 278 ESP_Wegimpuls_VL 2000;
BA_REL_ "GenSigTimeoutTime" BU_SG_REL_ ExBox SG_ 278 ESP_Wegimpuls_VR 2000;
BA_REL_ "GenSigTimeoutTime" BU_SG_REL_ ExBox SG_ 278 ESP_Wegimpuls_HL 2000;
BA_REL_ "GenSigTimeoutTime" BU_SG_REL_ ExBox SG_ 278 ESP_Wegimpuls_HR 2000;
BA_REL_ "GenSigTimeoutTime" BU_SG_REL_ ExBox SG_ 278 ESP_VL_Fahrtrichtung 2000;
BA_REL_ "GenSigTimeoutTime" BU_SG_REL_ ExBox SG_ 278 ESP_VR_Fahrtrichtung 2000;
BA_REL_ "GenSigTimeoutTime" BU_SG_REL_ ExBox SG_ 278 ESP_HL_Fahrtrichtung 2000;
BA_REL_ "GenSigTimeoutTime" BU_SG_REL_ ExBox SG_ 278 ESP_HR_Fahrtrichtung 2000;
BA_REL_ "GenSigTimeoutTime" BU_SG_REL_ ExBox SG_ 1629 ESP_Zaehnezahl 5000;
BA_REL_ "GenSigTimeoutTime" BU_SG_REL_ ExBox SG_ 795 ESP_Wegimp_VA 500;
BA_REL_ "GenSigTimeoutTime" BU_SG_REL_ ExBox SG_ 795 ESP_Fehlerstatus_Wegimp 500;
BA_REL_ "GenSigTimeoutTime" BU_SG_REL_ ExBox SG_ 795 ESP_Wegimp_Ueberlauf 500;
BA_REL_ "GenSigTimeoutTime" BU_SG_REL_ ExBox SG_ 795 ESP_QBit_Wegimp_VA 500;
BA_REL_ "GenSigTimeoutTime" BU_SG_REL_ ZR_High_Korea SG_ 2589283409 EB_Jahr 5000;
BA_REL_ "GenSigTimeoutTime" BU_SG_REL_ ZR_High_Korea SG_ 2589283409 EB_Monat 5000;
BA_REL_ "GenSigTimeoutTime" BU_SG_REL_ ZR_High_Korea SG_ 2589283409 EB_Tag 5000;
BA_REL_ "GenSigTimeoutTime" BU_SG_REL_ ZR_High_Korea SG_ 2589283409 EB_Stunde 5000;
BA_REL_ "GenSigTimeoutTime" BU_SG_REL_ ZR_High_Korea SG_ 2589283409 EB_Minute 5000;
BA_REL_ "GenSigTimeoutTime" BU_SG_REL_ ZR_High_Korea SG_ 2589283409 EB_Sekunde 5000;
BA_REL_ "GenSigTimeoutTime" BU_SG_REL_ ZR_High_Korea SG_ 2589283409 EB_Zeit_gueltig 5000;
BA_REL_ "GenSigTimeoutTime" BU_SG_REL_ ExBox SG_ 986 ESP_21_alt 1000;
BA_REL_ "GenSigTimeoutTime" BU_SG_REL_ ExBox SG_ 986 LWI_01_alt 1000;
BA_REL_ "GenSigTimeoutTime" BU_SG_REL_ ExBox SG_ 986 ESP_QBit_v_Signal 1000;
BA_REL_ "GenSigTimeoutTime" BU_SG_REL_ ExBox SG_ 986 ESP_v_Signal 1000;
BA_REL_ "GenSigTimeoutTime" BU_SG_REL_ ExBox SG_ 986 LWI_QBit_Lenkradwinkel 1000;
BA_REL_ "GenSigTimeoutTime" BU_SG_REL_ ExBox SG_ 986 LWI_Sensorstatus 1000;
BA_REL_ "GenSigTimeoutTime" BU_SG_REL_ ExBox SG_ 986 LWI_VZ_Lenkradwinkel 1000;
BA_REL_ "GenSigTimeoutTime" BU_SG_REL_ ExBox SG_ 986 LWI_Lenkradwinkel 1000;
BA_REL_ "GenSigTimeoutTime" BU_SG_REL_ ExBox SG_ 987 SMLS_01_alt 1000;
BA_REL_ "GenSigTimeoutTime" BU_SG_REL_ ExBox SG_ 987 Anhaenger_01_alt 1000;
BA_REL_ "GenSigTimeoutTime" BU_SG_REL_ ExBox SG_ 987 Licht_Anf_01_alt 1000;
BA_REL_ "GenSigTimeoutTime" BU_SG_REL_ ExBox SG_ 987 AAG_Anhaenger_erkannt 1000;
BA_REL_ "GenSigTimeoutTime" BU_SG_REL_ ExBox SG_ 987 BCM_Rueckfahrlicht_Anf 1000;
BA_REL_ "GenSigTimeoutTime" BU_SG_REL_ ExBox SG_ 987 BH_Blinker_li 1000;
BA_REL_ "GenSigTimeoutTime" BU_SG_REL_ ExBox SG_ 987 BH_Blinker_re 1000;
BA_REL_ "GenSigTimeoutTime" BU_SG_REL_ ZR_Entry SG_ 2589284280 DU1_KSV_Value_1 5000;
BA_REL_ "GenSigTimeoutTime" BU_SG_REL_ ZR_High SG_ 2589284280 DU1_KSV_Value_1 5000;
BA_REL_ "GenSigTimeoutTime" BU_SG_REL_ ZR_High_Korea SG_ 2589284280 DU1_KSV_Value_1 5000;
BA_REL_ "GenSigTimeoutTime" BU_SG_REL_ ZR_High_TT3 SG_ 2589284280 DU1_KSV_Value_1 5000;
BA_REL_ "GenSigTimeoutTime" BU_SG_REL_ ZR_MIB_OPTION_ab_Gen3 SG_ 2589284280 DU1_KSV_Value_1 5000;
BA_REL_ "GenSigTimeoutTime" BU_SG_REL_ ZR_MIB_TOP_ab_Gen3 SG_ 2589284280 DU1_KSV_Value_1 5000;
BA_REL_ "GenSigTimeoutTime" BU_SG_REL_ ZR_Standard SG_ 2589284280 DU1_KSV_Value_1 5000;
BA_REL_ "GenSigTimeoutTime" BU_SG_REL_ ZR_Entry SG_ 2589284280 DU1_KSV_Value_2 5000;
BA_REL_ "GenSigTimeoutTime" BU_SG_REL_ ZR_High SG_ 2589284280 DU1_KSV_Value_2 5000;
BA_REL_ "GenSigTimeoutTime" BU_SG_REL_ ZR_High_Korea SG_ 2589284280 DU1_KSV_Value_2 5000;
BA_REL_ "GenSigTimeoutTime" BU_SG_REL_ ZR_High_TT3 SG_ 2589284280 DU1_KSV_Value_2 5000;
BA_REL_ "GenSigTimeoutTime" BU_SG_REL_ ZR_MIB_OPTION_ab_Gen3 SG_ 2589284280 DU1_KSV_Value_2 5000;
BA_REL_ "GenSigTimeoutTime" BU_SG_REL_ ZR_MIB_TOP_ab_Gen3 SG_ 2589284280 DU1_KSV_Value_2 5000;
BA_REL_ "GenSigTimeoutTime" BU_SG_REL_ ZR_Standard SG_ 2589284280 DU1_KSV_Value_2 5000;
BA_REL_ "GenSigTimeoutTime" BU_SG_REL_ ZR_Entry SG_ 2589284280 DU1_HDCP_Auth_Status_Out_1 5000;
BA_REL_ "GenSigTimeoutTime" BU_SG_REL_ ZR_High SG_ 2589284280 DU1_HDCP_Auth_Status_Out_1 5000;
BA_REL_ "GenSigTimeoutTime" BU_SG_REL_ ZR_High_Korea SG_ 2589284280 DU1_HDCP_Auth_Status_Out_1 5000;
BA_REL_ "GenSigTimeoutTime" BU_SG_REL_ ZR_High_TT3 SG_ 2589284280 DU1_HDCP_Auth_Status_Out_1 5000;
BA_REL_ "GenSigTimeoutTime" BU_SG_REL_ ZR_MIB_OPTION_ab_Gen3 SG_ 2589284280 DU1_HDCP_Auth_Status_Out_1 5000;
BA_REL_ "GenSigTimeoutTime" BU_SG_REL_ ZR_MIB_TOP_ab_Gen3 SG_ 2589284280 DU1_HDCP_Auth_Status_Out_1 5000;
BA_REL_ "GenSigTimeoutTime" BU_SG_REL_ ZR_Standard SG_ 2589284280 DU1_HDCP_Auth_Status_Out_1 5000;
BA_REL_ "GenSigTimeoutTime" BU_SG_REL_ ZR_Entry SG_ 2589284280 DU1_HDCP_Auth_Status_Out_2 5000;
BA_REL_ "GenSigTimeoutTime" BU_SG_REL_ ZR_High SG_ 2589284280 DU1_HDCP_Auth_Status_Out_2 5000;
BA_REL_ "GenSigTimeoutTime" BU_SG_REL_ ZR_High_Korea SG_ 2589284280 DU1_HDCP_Auth_Status_Out_2 5000;
BA_REL_ "GenSigTimeoutTime" BU_SG_REL_ ZR_High_TT3 SG_ 2589284280 DU1_HDCP_Auth_Status_Out_2 5000;
BA_REL_ "GenSigTimeoutTime" BU_SG_REL_ ZR_MIB_OPTION_ab_Gen3 SG_ 2589284280 DU1_HDCP_Auth_Status_Out_2 5000;
BA_REL_ "GenSigTimeoutTime" BU_SG_REL_ ZR_MIB_TOP_ab_Gen3 SG_ 2589284280 DU1_HDCP_Auth_Status_Out_2 5000;
BA_REL_ "GenSigTimeoutTime" BU_SG_REL_ ZR_Standard SG_ 2589284280 DU1_HDCP_Auth_Status_Out_2 5000;
BA_REL_ "GenSigTimeoutTime" BU_SG_REL_ ZR_Entry SG_ 2589284280 DU1_HDCP_Auth_Status_Out_3 5000;
BA_REL_ "GenSigTimeoutTime" BU_SG_REL_ ZR_High SG_ 2589284280 DU1_HDCP_Auth_Status_Out_3 5000;
BA_REL_ "GenSigTimeoutTime" BU_SG_REL_ ZR_High_Korea SG_ 2589284280 DU1_HDCP_Auth_Status_Out_3 5000;
BA_REL_ "GenSigTimeoutTime" BU_SG_REL_ ZR_High_TT3 SG_ 2589284280 DU1_HDCP_Auth_Status_Out_3 5000;
BA_REL_ "GenSigTimeoutTime" BU_SG_REL_ ZR_MIB_OPTION_ab_Gen3 SG_ 2589284280 DU1_HDCP_Auth_Status_Out_3 5000;
BA_REL_ "GenSigTimeoutTime" BU_SG_REL_ ZR_MIB_TOP_ab_Gen3 SG_ 2589284280 DU1_HDCP_Auth_Status_Out_3 5000;
BA_REL_ "GenSigTimeoutTime" BU_SG_REL_ ZR_Standard SG_ 2589284280 DU1_HDCP_Auth_Status_Out_3 5000;
BA_REL_ "GenSigTimeoutTime" BU_SG_REL_ ZR_Entry SG_ 2589284280 DU1_HDCP_Auth_Status_Out_4 5000;
BA_REL_ "GenSigTimeoutTime" BU_SG_REL_ ZR_High SG_ 2589284280 DU1_HDCP_Auth_Status_Out_4 5000;
BA_REL_ "GenSigTimeoutTime" BU_SG_REL_ ZR_High_Korea SG_ 2589284280 DU1_HDCP_Auth_Status_Out_4 5000;
BA_REL_ "GenSigTimeoutTime" BU_SG_REL_ ZR_High_TT3 SG_ 2589284280 DU1_HDCP_Auth_Status_Out_4 5000;
BA_REL_ "GenSigTimeoutTime" BU_SG_REL_ ZR_MIB_OPTION_ab_Gen3 SG_ 2589284280 DU1_HDCP_Auth_Status_Out_4 5000;
BA_REL_ "GenSigTimeoutTime" BU_SG_REL_ ZR_MIB_TOP_ab_Gen3 SG_ 2589284280 DU1_HDCP_Auth_Status_Out_4 5000;
BA_REL_ "GenSigTimeoutTime" BU_SG_REL_ ZR_Standard SG_ 2589284280 DU1_HDCP_Auth_Status_Out_4 5000;
BA_REL_ "GenSigTimeoutTime" BU_SG_REL_ ZR_Entry SG_ 2589284280 DU1_HDCP_Auth_Status_Out_5 5000;
BA_REL_ "GenSigTimeoutTime" BU_SG_REL_ ZR_High SG_ 2589284280 DU1_HDCP_Auth_Status_Out_5 5000;
BA_REL_ "GenSigTimeoutTime" BU_SG_REL_ ZR_High_Korea SG_ 2589284280 DU1_HDCP_Auth_Status_Out_5 5000;
BA_REL_ "GenSigTimeoutTime" BU_SG_REL_ ZR_High_TT3 SG_ 2589284280 DU1_HDCP_Auth_Status_Out_5 5000;
BA_REL_ "GenSigTimeoutTime" BU_SG_REL_ ZR_MIB_OPTION_ab_Gen3 SG_ 2589284280 DU1_HDCP_Auth_Status_Out_5 5000;
BA_REL_ "GenSigTimeoutTime" BU_SG_REL_ ZR_MIB_TOP_ab_Gen3 SG_ 2589284280 DU1_HDCP_Auth_Status_Out_5 5000;
BA_REL_ "GenSigTimeoutTime" BU_SG_REL_ ZR_Standard SG_ 2589284280 DU1_HDCP_Auth_Status_Out_5 5000;
BA_REL_ "GenSigTimeoutTime" BU_SG_REL_ ZR_Entry SG_ 2589284280 DU1_HDCP_Auth_Status_Out_6 5000;
BA_REL_ "GenSigTimeoutTime" BU_SG_REL_ ZR_High SG_ 2589284280 DU1_HDCP_Auth_Status_Out_6 5000;
BA_REL_ "GenSigTimeoutTime" BU_SG_REL_ ZR_High_Korea SG_ 2589284280 DU1_HDCP_Auth_Status_Out_6 5000;
BA_REL_ "GenSigTimeoutTime" BU_SG_REL_ ZR_High_TT3 SG_ 2589284280 DU1_HDCP_Auth_Status_Out_6 5000;
BA_REL_ "GenSigTimeoutTime" BU_SG_REL_ ZR_MIB_OPTION_ab_Gen3 SG_ 2589284280 DU1_HDCP_Auth_Status_Out_6 5000;
BA_REL_ "GenSigTimeoutTime" BU_SG_REL_ ZR_MIB_TOP_ab_Gen3 SG_ 2589284280 DU1_HDCP_Auth_Status_Out_6 5000;
BA_REL_ "GenSigTimeoutTime" BU_SG_REL_ ZR_Standard SG_ 2589284280 DU1_HDCP_Auth_Status_Out_6 5000;
BA_REL_ "GenSigTimeoutTime" BU_SG_REL_ ZR_Entry SG_ 2589284280 DU1_HDCP_Auth_Status_Out_7 5000;
BA_REL_ "GenSigTimeoutTime" BU_SG_REL_ ZR_High SG_ 2589284280 DU1_HDCP_Auth_Status_Out_7 5000;
BA_REL_ "GenSigTimeoutTime" BU_SG_REL_ ZR_High_Korea SG_ 2589284280 DU1_HDCP_Auth_Status_Out_7 5000;
BA_REL_ "GenSigTimeoutTime" BU_SG_REL_ ZR_High_TT3 SG_ 2589284280 DU1_HDCP_Auth_Status_Out_7 5000;
BA_REL_ "GenSigTimeoutTime" BU_SG_REL_ ZR_MIB_OPTION_ab_Gen3 SG_ 2589284280 DU1_HDCP_Auth_Status_Out_7 5000;
BA_REL_ "GenSigTimeoutTime" BU_SG_REL_ ZR_MIB_TOP_ab_Gen3 SG_ 2589284280 DU1_HDCP_Auth_Status_Out_7 5000;
BA_REL_ "GenSigTimeoutTime" BU_SG_REL_ ZR_Standard SG_ 2589284280 DU1_HDCP_Auth_Status_Out_7 5000;
BA_REL_ "GenSigTimeoutTime" BU_SG_REL_ ZR_Entry SG_ 2589284280 DU1_HDCP_Auth_Status_Out_8 5000;
BA_REL_ "GenSigTimeoutTime" BU_SG_REL_ ZR_High SG_ 2589284280 DU1_HDCP_Auth_Status_Out_8 5000;
BA_REL_ "GenSigTimeoutTime" BU_SG_REL_ ZR_High_Korea SG_ 2589284280 DU1_HDCP_Auth_Status_Out_8 5000;
BA_REL_ "GenSigTimeoutTime" BU_SG_REL_ ZR_High_TT3 SG_ 2589284280 DU1_HDCP_Auth_Status_Out_8 5000;
BA_REL_ "GenSigTimeoutTime" BU_SG_REL_ ZR_MIB_OPTION_ab_Gen3 SG_ 2589284280 DU1_HDCP_Auth_Status_Out_8 5000;
BA_REL_ "GenSigTimeoutTime" BU_SG_REL_ ZR_MIB_TOP_ab_Gen3 SG_ 2589284280 DU1_HDCP_Auth_Status_Out_8 5000;
BA_REL_ "GenSigTimeoutTime" BU_SG_REL_ ZR_Standard SG_ 2589284280 DU1_HDCP_Auth_Status_Out_8 5000;
BA_REL_ "GenSigTimeoutTime" BU_SG_REL_ ZR_High SG_ 2589284281 DU2_KSV_Value_1 5000;
BA_REL_ "GenSigTimeoutTime" BU_SG_REL_ ZR_MIB_OPTION_ab_Gen3 SG_ 2589284281 DU2_KSV_Value_1 5000;
BA_REL_ "GenSigTimeoutTime" BU_SG_REL_ ZR_MIB_TOP_ab_Gen3 SG_ 2589284281 DU2_KSV_Value_1 5000;
BA_REL_ "GenSigTimeoutTime" BU_SG_REL_ ZR_Standard SG_ 2589284281 DU2_KSV_Value_1 5000;
BA_REL_ "GenSigTimeoutTime" BU_SG_REL_ ZR_High SG_ 2589284281 DU2_KSV_Value_2 5000;
BA_REL_ "GenSigTimeoutTime" BU_SG_REL_ ZR_MIB_OPTION_ab_Gen3 SG_ 2589284281 DU2_KSV_Value_2 5000;
BA_REL_ "GenSigTimeoutTime" BU_SG_REL_ ZR_MIB_TOP_ab_Gen3 SG_ 2589284281 DU2_KSV_Value_2 5000;
BA_REL_ "GenSigTimeoutTime" BU_SG_REL_ ZR_Standard SG_ 2589284281 DU2_KSV_Value_2 5000;
BA_REL_ "GenSigTimeoutTime" BU_SG_REL_ ZR_High SG_ 2589284281 DU2_HDCP_Auth_Status_Out_1 5000;
BA_REL_ "GenSigTimeoutTime" BU_SG_REL_ ZR_MIB_OPTION_ab_Gen3 SG_ 2589284281 DU2_HDCP_Auth_Status_Out_1 5000;
BA_REL_ "GenSigTimeoutTime" BU_SG_REL_ ZR_MIB_TOP_ab_Gen3 SG_ 2589284281 DU2_HDCP_Auth_Status_Out_1 5000;
BA_REL_ "GenSigTimeoutTime" BU_SG_REL_ ZR_Standard SG_ 2589284281 DU2_HDCP_Auth_Status_Out_1 5000;
BA_REL_ "GenSigTimeoutTime" BU_SG_REL_ ZR_High SG_ 2589284281 DU2_HDCP_Auth_Status_Out_2 5000;
BA_REL_ "GenSigTimeoutTime" BU_SG_REL_ ZR_MIB_OPTION_ab_Gen3 SG_ 2589284281 DU2_HDCP_Auth_Status_Out_2 5000;
BA_REL_ "GenSigTimeoutTime" BU_SG_REL_ ZR_MIB_TOP_ab_Gen3 SG_ 2589284281 DU2_HDCP_Auth_Status_Out_2 5000;
BA_REL_ "GenSigTimeoutTime" BU_SG_REL_ ZR_Standard SG_ 2589284281 DU2_HDCP_Auth_Status_Out_2 5000;
BA_REL_ "GenSigTimeoutTime" BU_SG_REL_ ZR_High SG_ 2589284281 DU2_HDCP_Auth_Status_Out_3 5000;
BA_REL_ "GenSigTimeoutTime" BU_SG_REL_ ZR_MIB_OPTION_ab_Gen3 SG_ 2589284281 DU2_HDCP_Auth_Status_Out_3 5000;
BA_REL_ "GenSigTimeoutTime" BU_SG_REL_ ZR_MIB_TOP_ab_Gen3 SG_ 2589284281 DU2_HDCP_Auth_Status_Out_3 5000;
BA_REL_ "GenSigTimeoutTime" BU_SG_REL_ ZR_Standard SG_ 2589284281 DU2_HDCP_Auth_Status_Out_3 5000;
BA_REL_ "GenSigTimeoutTime" BU_SG_REL_ ZR_High SG_ 2589284281 DU2_HDCP_Auth_Status_Out_4 5000;
BA_REL_ "GenSigTimeoutTime" BU_SG_REL_ ZR_MIB_OPTION_ab_Gen3 SG_ 2589284281 DU2_HDCP_Auth_Status_Out_4 5000;
BA_REL_ "GenSigTimeoutTime" BU_SG_REL_ ZR_MIB_TOP_ab_Gen3 SG_ 2589284281 DU2_HDCP_Auth_Status_Out_4 5000;
BA_REL_ "GenSigTimeoutTime" BU_SG_REL_ ZR_Standard SG_ 2589284281 DU2_HDCP_Auth_Status_Out_4 5000;
BA_REL_ "GenSigTimeoutTime" BU_SG_REL_ ZR_High SG_ 2589284281 DU2_HDCP_Auth_Status_Out_5 5000;
BA_REL_ "GenSigTimeoutTime" BU_SG_REL_ ZR_MIB_OPTION_ab_Gen3 SG_ 2589284281 DU2_HDCP_Auth_Status_Out_5 5000;
BA_REL_ "GenSigTimeoutTime" BU_SG_REL_ ZR_MIB_TOP_ab_Gen3 SG_ 2589284281 DU2_HDCP_Auth_Status_Out_5 5000;
BA_REL_ "GenSigTimeoutTime" BU_SG_REL_ ZR_Standard SG_ 2589284281 DU2_HDCP_Auth_Status_Out_5 5000;
BA_REL_ "GenSigTimeoutTime" BU_SG_REL_ ZR_High SG_ 2589284281 DU2_HDCP_Auth_Status_Out_6 5000;
BA_REL_ "GenSigTimeoutTime" BU_SG_REL_ ZR_MIB_OPTION_ab_Gen3 SG_ 2589284281 DU2_HDCP_Auth_Status_Out_6 5000;
BA_REL_ "GenSigTimeoutTime" BU_SG_REL_ ZR_MIB_TOP_ab_Gen3 SG_ 2589284281 DU2_HDCP_Auth_Status_Out_6 5000;
BA_REL_ "GenSigTimeoutTime" BU_SG_REL_ ZR_Standard SG_ 2589284281 DU2_HDCP_Auth_Status_Out_6 5000;
BA_REL_ "GenSigTimeoutTime" BU_SG_REL_ ZR_High SG_ 2589284281 DU2_HDCP_Auth_Status_Out_7 5000;
BA_REL_ "GenSigTimeoutTime" BU_SG_REL_ ZR_MIB_OPTION_ab_Gen3 SG_ 2589284281 DU2_HDCP_Auth_Status_Out_7 5000;
BA_REL_ "GenSigTimeoutTime" BU_SG_REL_ ZR_MIB_TOP_ab_Gen3 SG_ 2589284281 DU2_HDCP_Auth_Status_Out_7 5000;
BA_REL_ "GenSigTimeoutTime" BU_SG_REL_ ZR_Standard SG_ 2589284281 DU2_HDCP_Auth_Status_Out_7 5000;
BA_REL_ "GenSigTimeoutTime" BU_SG_REL_ ZR_High SG_ 2589284281 DU2_HDCP_Auth_Status_Out_8 5000;
BA_REL_ "GenSigTimeoutTime" BU_SG_REL_ ZR_MIB_OPTION_ab_Gen3 SG_ 2589284281 DU2_HDCP_Auth_Status_Out_8 5000;
BA_REL_ "GenSigTimeoutTime" BU_SG_REL_ ZR_MIB_TOP_ab_Gen3 SG_ 2589284281 DU2_HDCP_Auth_Status_Out_8 5000;
BA_REL_ "GenSigTimeoutTime" BU_SG_REL_ ZR_Standard SG_ 2589284281 DU2_HDCP_Auth_Status_Out_8 5000;
BA_REL_ "GenSigTimeoutTime" BU_SG_REL_ ZR_High SG_ 2589284283 DU3_HDCP_Auth_Status_Out_1 5000;
BA_REL_ "GenSigTimeoutTime" BU_SG_REL_ ZR_MIB_TOP_ab_Gen3 SG_ 2589284283 DU3_HDCP_Auth_Status_Out_1 5000;
BA_REL_ "GenSigTimeoutTime" BU_SG_REL_ ZR_High SG_ 2589284283 DU3_HDCP_Auth_Status_Out_2 5000;
BA_REL_ "GenSigTimeoutTime" BU_SG_REL_ ZR_MIB_TOP_ab_Gen3 SG_ 2589284283 DU3_HDCP_Auth_Status_Out_2 5000;
BA_REL_ "GenSigTimeoutTime" BU_SG_REL_ ZR_High SG_ 2589284283 DU3_HDCP_Auth_Status_Out_3 5000;
BA_REL_ "GenSigTimeoutTime" BU_SG_REL_ ZR_MIB_TOP_ab_Gen3 SG_ 2589284283 DU3_HDCP_Auth_Status_Out_3 5000;
BA_REL_ "GenSigTimeoutTime" BU_SG_REL_ ZR_High SG_ 2589284283 DU3_HDCP_Auth_Status_Out_4 5000;
BA_REL_ "GenSigTimeoutTime" BU_SG_REL_ ZR_MIB_TOP_ab_Gen3 SG_ 2589284283 DU3_HDCP_Auth_Status_Out_4 5000;
BA_REL_ "GenSigTimeoutTime" BU_SG_REL_ ZR_High SG_ 2589284283 DU3_HDCP_Auth_Status_Out_5 5000;
BA_REL_ "GenSigTimeoutTime" BU_SG_REL_ ZR_MIB_TOP_ab_Gen3 SG_ 2589284283 DU3_HDCP_Auth_Status_Out_5 5000;
BA_REL_ "GenSigTimeoutTime" BU_SG_REL_ ZR_High SG_ 2589284283 DU3_HDCP_Auth_Status_Out_6 5000;
BA_REL_ "GenSigTimeoutTime" BU_SG_REL_ ZR_MIB_TOP_ab_Gen3 SG_ 2589284283 DU3_HDCP_Auth_Status_Out_6 5000;
BA_REL_ "GenSigTimeoutTime" BU_SG_REL_ ZR_High SG_ 2589284283 DU3_HDCP_Auth_Status_Out_7 5000;
BA_REL_ "GenSigTimeoutTime" BU_SG_REL_ ZR_MIB_TOP_ab_Gen3 SG_ 2589284283 DU3_HDCP_Auth_Status_Out_7 5000;
BA_REL_ "GenSigTimeoutTime" BU_SG_REL_ ZR_High SG_ 2589284283 DU3_HDCP_Auth_Status_Out_8 5000;
BA_REL_ "GenSigTimeoutTime" BU_SG_REL_ ZR_MIB_TOP_ab_Gen3 SG_ 2589284283 DU3_HDCP_Auth_Status_Out_8 5000;
BA_REL_ "GenSigTimeoutTime" BU_SG_REL_ ExBox SG_ 960 ZAS_Kl_S 1000;
BA_REL_ "GenSigTimeoutTime" BU_SG_REL_ SCC1 SG_ 960 ZAS_Kl_S 1000;
BA_REL_ "GenSigTimeoutTime" BU_SG_REL_ SCC2 SG_ 960 ZAS_Kl_S 1000;
BA_REL_ "GenSigTimeoutTime" BU_SG_REL_ SDC1 SG_ 960 ZAS_Kl_S 1000;
BA_REL_ "GenSigTimeoutTime" BU_SG_REL_ SDC2 SG_ 960 ZAS_Kl_S 1000;
BA_REL_ "GenSigTimeoutTime" BU_SG_REL_ WLC_01 SG_ 960 ZAS_Kl_S 1000;
BA_REL_ "GenSigTimeoutTime" BU_SG_REL_ WLC_02 SG_ 960 ZAS_Kl_S 1000;
BA_REL_ "GenSigTimeoutTime" BU_SG_REL_ ABT_1_MIB_ab_Gen3 SG_ 960 ZAS_Kl_15 1000;
BA_REL_ "GenSigTimeoutTime" BU_SG_REL_ ABT_1_MQB SG_ 960 ZAS_Kl_15 1000;
BA_REL_ "GenSigTimeoutTime" BU_SG_REL_ BT_1_MQB SG_ 960 ZAS_Kl_15 1000;
BA_REL_ "GenSigTimeoutTime" BU_SG_REL_ DU_1_MQB SG_ 960 ZAS_Kl_15 1000;
BA_REL_ "GenSigTimeoutTime" BU_SG_REL_ DU_2 SG_ 960 ZAS_Kl_15 1000;
BA_REL_ "GenSigTimeoutTime" BU_SG_REL_ DU_3 SG_ 960 ZAS_Kl_15 1000;
BA_REL_ "GenSigTimeoutTime" BU_SG_REL_ DU_4 SG_ 960 ZAS_Kl_15 1000;
BA_REL_ "GenSigTimeoutTime" BU_SG_REL_ ExBox SG_ 960 ZAS_Kl_15 1000;
BA_REL_ "GenSigTimeoutTime" BU_SG_REL_ LSR_1 SG_ 960 ZAS_Kl_15 1000;
BA_REL_ "GenSigTimeoutTime" BU_SG_REL_ SCC1 SG_ 960 ZAS_Kl_15 1000;
BA_REL_ "GenSigTimeoutTime" BU_SG_REL_ SCC2 SG_ 960 ZAS_Kl_15 1000;
BA_REL_ "GenSigTimeoutTime" BU_SG_REL_ SDC1 SG_ 960 ZAS_Kl_15 1000;
BA_REL_ "GenSigTimeoutTime" BU_SG_REL_ SDC2 SG_ 960 ZAS_Kl_15 1000;
BA_REL_ "GenSigTimeoutTime" BU_SG_REL_ WLC_01 SG_ 960 ZAS_Kl_15 1000;
BA_REL_ "GenSigTimeoutTime" BU_SG_REL_ WLC_02 SG_ 960 ZAS_Kl_15 1000;
BA_REL_ "GenSigTimeoutTime" BU_SG_REL_ BT_1_MQB SG_ 960 ZAS_Kl_50_Startanforderung 1000;
BA_REL_ "GenSigTimeoutTime" BU_SG_REL_ ZR_High_TT3 SG_ 2549088276 KBI_KD_Fehler 5000;
BA_REL_ "GenSigTimeoutTime" BU_SG_REL_ ZR_High SG_ 2549088426 SCC1_Nachlauftyp 5000;
BA_REL_ "GenSigTimeoutTime" BU_SG_REL_ ZR_High SG_ 2549088426 SCC1_SNI 5000;
BA_REL_ "GenSigTimeoutTime" BU_SG_REL_ ZR_High SG_ 2549088426 NM_SCC1_Wakeup 5000;
BA_REL_ "GenSigTimeoutTime" BU_SG_REL_ ZR_High SG_ 2549088426 NM_SCC1_Lokalaktiv 5000;
BA_REL_ "GenSigTimeoutTime" BU_SG_REL_ ZR_High SG_ 2549088426 SCC1_KD_Fehler 5000;
BA_REL_ "GenSigTimeoutTime" BU_SG_REL_ ZR_High SG_ 2549088427 SCC2_Nachlauftyp 5000;
BA_REL_ "GenSigTimeoutTime" BU_SG_REL_ ZR_High SG_ 2549088427 SCC2_SNI 5000;
BA_REL_ "GenSigTimeoutTime" BU_SG_REL_ ZR_High SG_ 2549088427 NM_SCC2_Lokalaktiv 5000;
BA_REL_ "GenSigTimeoutTime" BU_SG_REL_ ZR_High SG_ 2549088427 SCC2_KD_Fehler 5000;
BA_REL_ "GenSigTimeoutTime" BU_SG_REL_ ZR_High SG_ 2549088423 SDC1_Nachlauftyp 5000;
BA_REL_ "GenSigTimeoutTime" BU_SG_REL_ ZR_High SG_ 2549088423 SDC1_SNI 5000;
BA_REL_ "GenSigTimeoutTime" BU_SG_REL_ ZR_High SG_ 2549088423 NM_SDC1_Lokalaktiv 5000;
BA_REL_ "GenSigTimeoutTime" BU_SG_REL_ ZR_High SG_ 2549088423 SDC1_KD_Fehler 5000;
BA_REL_ "GenSigTimeoutTime" BU_SG_REL_ ZR_High SG_ 2549088424 SDC2_Nachlauftyp 5000;
BA_REL_ "GenSigTimeoutTime" BU_SG_REL_ ZR_High SG_ 2549088424 SDC2_SNI 5000;
BA_REL_ "GenSigTimeoutTime" BU_SG_REL_ ZR_High SG_ 2549088424 NM_SDC2_Lokalaktiv 5000;
BA_REL_ "GenSigTimeoutTime" BU_SG_REL_ ZR_High SG_ 2549088424 SDC2_KD_Fehler 5000;
VAL_ 2589283759 DU3_LVDS_Splitter_Fehlerstatus 0 "kein_Fehler" 1 "SW_Fehler" 2 "HW_Fehler" ;
VAL_ 2589283759 DU3_Betriebsdauer_min 254 "Init" 255 "Fehler" ;
VAL_ 2589283759 DU3_Betriebsdauer_std 65534 "Init" 65535 "Fehler" ;
VAL_ 2589283759 DU3_HintGrdBelKurzschl 0 "normal" 1 "Fehler" ;
VAL_ 2589283759 DU3_HintGrdBelUnterbr 0 "normal" 1 "Fehler" ;
VAL_ 2589283759 DU3_EEPROM_Fehler 0 "normal" 1 "Fehler" ;
VAL_ 2589283759 DU3_SW_inkonsistent 0 "kein_Fehler" 1 "Fehler" ;
VAL_ 2589283759 DU3_HDCP_Status 0 "kein_Fehler" 1 "Fehler" ;
VAL_ 2589283759 DU3_LVDS_Status 0 "LVDS_Unlocked" 1 "LVDS_Lock" ;
VAL_ 2589283759 DU3_ZR_Lenkerpos_Status 0 "links" 1 "rechts" ;
VAL_ 2589283759 DU3_Touch_Fehlerstatus 0 "kein_Fehler" 1 "SW_Fehler" 2 "HW_Fehler" ;
VAL_ 2589283759 DU3_Haptik_Fehlerstatus 0 "kein_Fehler" 1 "SW_Fehler" 2 "HW_Fehler" ;
VAL_ 1603 KBI_Einheit_Datum 0 "Tag/Monat/Jahr" 1 "Monat/Tag/Jahr" 2 "Jahr/Monat/Tag" 3 "reserviert" ;
VAL_ 1603 KBI_Einheit_Druck 0 "Druckangabe in bar" 1 "Druckangabe in psi" 2 "Druckangabe in kPa" 3 "tbd." ;
VAL_ 1603 KBI_Einheit_Streckenanz 0 "Kilometer" 1 "Meilen" ;
VAL_ 1603 KBI_MFA_v_Einheit_02 0 "kmh" 1 "mph" ;
VAL_ 1603 KBI_Einheit_Temp 0 "Grad Celsius °C" 1 "Grad Fahrenheit °F" ;
VAL_ 1603 KBI_Einheit_Uhrzeit 0 "24h" 1 " 12h AM/PM" ;
VAL_ 1603 KBI_Einheit_Verbrauch 0 "mpg UK" 1 "mpg USA" 2 "Liter/100km" 3 "km/Liter" ;
VAL_ 1603 KBI_Einheit_Volumen 0 "Liter" 1 "Gallonen UK" 2 "Gallonen USA" 3 "reserviert" ;
VAL_ 1603 KBI_Einheit_Verbrauch_elektr 0 "kWh_pro_100km" 1 "km_pro_kWh" 2 "kWh_pro_100mls" 3 "mls_pro_kWh" 4 "MPGe" ;
VAL_ 1603 KBI_Einheit_Verbrauch_Gas 0 "kg_per_100km" 1 "km_per_kg" 2 "m3_per_100km" 3 "km_per_m3" 4 "miles_per_lbs" 5 "miles_per_yard3" 6 "miles_per_kg" 7 "miles_per_m3" 8 "miles_per_gallon_equivalent_US" ;
VAL_ 1603 KBI_Einheit_Masse 0 "kg" 1 "lbs" 2 "reserviert" ;
VAL_ 278 ESP_QBit_Wegimpuls_VL 0 "gueltiger_Wert" 1 "Ersatz_Init_oder_Fehlerwert" ;
VAL_ 278 ESP_QBit_Wegimpuls_VR 0 "gueltiger_Wert" 1 "Ersatz_Init_oder_Fehlerwert" ;
VAL_ 278 ESP_QBit_Wegimpuls_HL 0 "gueltiger_Wert" 1 "Ersatz_Init_oder_Fehlerwert" ;
VAL_ 278 ESP_QBit_Wegimpuls_HR 0 "gueltiger_Wert" 1 "Ersatz_Init_oder_Fehlerwert" ;
VAL_ 278 ESP_Wegimpuls_VL 1021 "Init" 1022 "Unterspannung" 1023 "Fehler" ;
VAL_ 278 ESP_Wegimpuls_VR 1021 "Init" 1022 "Unterspannung" 1023 "Fehler" ;
VAL_ 278 ESP_Wegimpuls_HL 1021 "Init" 1022 "Unterspannung" 1023 "Fehler" ;
VAL_ 278 ESP_Wegimpuls_HR 1021 "Init" 1022 "Unterspannung" 1023 "Fehler" ;
VAL_ 278 ESP_VL_Fahrtrichtung 0 "Vorwaerts" 1 "Rueckwaerts" 2 "Init" 3 "ungueltig_oder_nicht_verbaut" ;
VAL_ 278 ESP_VR_Fahrtrichtung 0 "Vorwaerts" 1 "Rueckwaerts" 2 "Init" 3 "ungueltig_oder_nicht_verbaut" ;
VAL_ 278 ESP_HL_Fahrtrichtung 0 "Vorwaerts" 1 "Rueckwaerts" 2 "Init" 3 "ungueltig_oder_nicht_verbaut" ;
VAL_ 278 ESP_HR_Fahrtrichtung 0 "Vorwaerts" 1 "Rueckwaerts" 2 "Init" 3 "ungueltig_oder_nicht_verbaut" ;
VAL_ 1629 BR_Systemart 0 "ABS" 1 "ABS_ASR" 2 "ESP" 3 "ESP_mit_integrierter_EPB" ;
VAL_ 1629 ESP_SpannungsAnf_02 0 "keine_Anforderung" 1 "Anforderung_Stufe1" 2 "Anforderung_Stufe2" 3 "Anforderung_Stufe3" ;
VAL_ 1629 ESP_Charisma_FahrPr 0 "keine_Funktion" 1 "Programm_1" 2 "Programm_2" 3 "Programm_3" 4 "Programm_4" 5 "Programm_5" 6 "Programm_6" 7 "Programm_7" 8 "Programm_8" 9 "Programm_9" 10 "Programm_10" 11 "Programm_11" 12 "Programm_12" 13 "Programm_13" 14 "Programm_14" 15 "Programm_15" ;
VAL_ 1629 ESP_Charisma_Status 0 "Init" 1 "verfuegbar" 2 "nicht_verfuegbar" 3 "asynchron_durch_Fahrerwunsch" ;
VAL_ 1629 ESP_Wiederstart_Anz_01 0 "keine_Anzeige" 1 "Rueckwaertsrollen" ;
VAL_ 1629 ESP_Wiederstart_Anz_02 0 "keine_Anzeige" 1 "Autohold_Rutschen" ;
VAL_ 1629 ESP_Wiederstart_Anz_03 0 "keine_Anzeige" 1 "Offroad_HDC" ;
VAL_ 1629 ESP_Wiederstart_Anz_04 0 "keine_Anzeige" 1 "ESC_Off" ;
VAL_ 1629 ESP_Stoppverbot_Anz_01 0 "keine_Anzeige" 1 "Notbremsung_aktiv" ;
VAL_ 1629 ESP_Stoppverbot_Anz_02 0 "keine_Anzeige" 1 "Autohold_AVH_Rutschen" ;
VAL_ 1629 ESP_Stoppverbot_Anz_03 0 "keine_Anzeige" 1 "Rueckwaertsrollen" ;
VAL_ 1629 ESP_Stoppverbot_Anz_04 0 "keine_Anzeige" 1 "ESP_Pumpenlauf" ;
VAL_ 1629 ESP_Stoppverbot_Anz_05 0 "keine_Anzeige" 1 "ESP_OFF" ;
VAL_ 1629 ESP_Stoppverbot_Anz_06 0 "keine_Anzeige" 1 "Offroad_HDC" ;
VAL_ 1629 ESP_Stoppverbot_Anz_07 0 "keine_Anzeige" 1 "ESP_Haltefunktion_nicht_verfuegbar" ;
VAL_ 1629 ESP_Stoppverbot_Anz_Std 0 "keine_Anzeige" 1 "Standard_Stoppvetogrund" ;
VAL_ 1629 ESP_Dachrelingsensor 0 "Sensor_nicht_verbaut" 1 "Quertraeger_montiert" 2 "Quertraeger_nicht_montiert" 3 "Fehler" ;
VAL_ 1629 ESP_Stoppverbot_Anz_08 0 "keine_Anzeige" 1 "Neigungsbegrenzung" ;
VAL_ 1629 HDC_Charisma_FahrPr 0 "keine_Funktion" 1 "Programm_1" 2 "Programm_2" 3 "Programm_3" 4 "Programm_4" 5 "Programm_5" 6 "Programm_6" 7 "Programm_7" 8 "Programm_8" 9 "Programm_9" 10 "Programm_10" 11 "Programm_11" 12 "Programm_12" 13 "Programm_13" 14 "Programm_14" 15 "Programm_15" ;
VAL_ 1629 HDC_Charisma_Status 0 "Init" 1 "verfuegbar" 2 "nicht_verfuegbar" 3 "asynchron_durch_Fahrerwunsch" ;
VAL_ 1629 BR_QBit_Reifenumfang 0 "gueltiger_Wert" 1 "Ersatz_Init_oder_Fehlerwert" ;
VAL_ 795 ESP_Lampe 0 "Aus" 1 "Ein" ;
VAL_ 795 ABS_Lampe 0 "Aus" 1 "Ein" ;
VAL_ 795 BK_Lampe_02 0 "aus" 1 "ein_statisch" 3 "Warnung" ;
VAL_ 795 TC_Lampe 0 "Aus" 1 "Ein" ;
VAL_ 795 ESP_m_Raddrehz 32765 "Unterspannung" 32766 "Init" 32767 "Fehler" ;
VAL_ 795 ESP_Textanzeigen_03 0 "kein_Text" 1 "ESP_Stoerung" 2 "ABS_Stoerung" 3 "ESP_ABS_Stoerung" 4 "Werkstatt_Bremse" 5 "ASR_Stoerung" 6 "ESP_switched_off" 7 "ASR_off" 8 "ESP_ASR_on" 10 "keine_Bremskraftverstaerkung" 11 "ASR_aktiviert" 12 "ABS_ASR_Stoerung" 15 "ESP_offroad" 17 "ESP_sport" 18 "ESP_Zwangsaktivierung" 19 "ESP_Taster_Info" 20 "TC_aktiv" 21 "reserviert_fuer_Verlwarn" 22 "TC_switched_off" 23 "Verlwarn_akt_Rollsicher_inakt" 24 "ESP_SuperSport" 25 "ESP_Offroad_nicht_verfuegbar" ;
VAL_ 795 ESP_Meldungen 0 "keine_Anzeige" 1 "Autohold_Hinweis_1" 2 "Stoerung_Autohold" 3 "Stoerung_Hillholder" 4 "Uebernehmen" 5 "Autohold_aus" 6 "Autohold_Hinweis_2" ;
VAL_ 795 ESP_Fehlerstatus_Wegimp 0 "Wegimpulse_iO" 1 "Fehler" ;
VAL_ 795 ESP_Wegimp_Ueberlauf 0 "Reset_und_kein_Ueberlauf" 1 "mindestens_1x_Ueberlauf" ;
VAL_ 795 ESP_QBit_Wegimp_VA 0 "gueltiger_Wert" 1 "Ersatz_Init_oder_Fehlerwert" ;
VAL_ 795 ESP_HDC_FktLampe 0 "Aus" 1 "Ein" ;
VAL_ 795 ESP_Off_Lampe 0 "Lampe_aus" 1 "Lampe_ein" ;
VAL_ 795 ESP_HDC_Regelgeschw 0 "nicht_verbaut" 125 "HDC_Standby" 126 "Init" 127 "Fehler" ;
VAL_ 795 ESP_BKV_Warnung 0 "keine_Anzeige" 1 "keine_Bremskraftverstaerkung" ;
VAL_ 2589283409 EB_Monat 0 "Init" 14 "reserviert" 15 "Fehler" ;
VAL_ 2589283409 EB_Tag 0 "Init" ;
VAL_ 2589283409 EB_Zeit_gueltig 0 "ungueltig" 1 "gueltig" ;
VAL_ 986 ESP_05_alt 0 "aktuell" 1 "veraltet" ;
VAL_ 986 EPB_01_alt 0 "aktuell" 1 "veraltet" ;
VAL_ 986 ESP_21_alt 0 "aktuell" 1 "veraltet" ;
VAL_ 986 LWI_01_alt 0 "aktuell" 1 "veraltet" ;
VAL_ 986 Parkhilfe_01_alt 0 "aktuell" 1 "veraltet" ;
VAL_ 986 Kamera_Status_alt 0 "aktuell" 1 "veraltet" ;
VAL_ 986 ESP_HDC_Standby 0 "HDC_Funktion_nicht_im_Standby" 1 "HDC_Funktion_im_Standby" ;
VAL_ 986 ECD_Bremslicht 0 "Aus" 1 "Ein" ;
VAL_ 986 EPB_Status 0 "offen" 1 "Bremse_geschl_(Spannkraft_voll/reduziert)" 2 "Aktuator_im_Lauf" 3 "Fehler_oder_unbekannt" ;
VAL_ 986 EPB_QBit_Pedalweg_Kuppl 0 "gültiger Wert" 1 "Ersatz-, Init- oder Fehlerwert" ;
VAL_ 986 ESP_QBit_v_Signal 0 "gueltiger_Wert" 1 "Ersatz_Init_oder_Fehlerwert" ;
VAL_ 986 ABS_Bremsung 0 "keine_ABS_Regelung" 1 "ABS_Regelung_aktiv" ;
VAL_ 986 ESP_Eingriff 0 "kein_ESP_Eingriff" 1 "ESP_Eingriff_aktiv" ;
VAL_ 986 Kamera_FSH_aktiv 0 "Kamera_Frontscheibenheizung_nicht_aktiviert" 1 "Kamera_Frontscheibenheizung_aktiviert" ;
VAL_ 986 EPB_Pedalweg_Kuppl 0 "Init" 255 "Fehler" ;
VAL_ 986 ESP_v_Signal 65533 "Unterspannung" 65534 "Init" 65535 "Fehler" ;
VAL_ 986 LWI_QBit_Lenkradwinkel 0 "gültiger Wert" 1 "ausserhalb der Spezifikation" ;
VAL_ 986 LWI_Sensorstatus 0 "iO" 1 "nicht kalibriert" ;
VAL_ 986 LWI_VZ_Lenkradwinkel 0 "positiv_links_von_der_Nullstellung" 1 "negativ" ;
VAL_ 986 LWI_Lenkradwinkel 8190 "Init" 8191 "Fehler" ;
VAL_ 986 PH_Anf_Audioabsenkung 0 "keine Absenkung der Lautstärke" 1 "Anforderung an das Audiosystem für Absenkung der Lautstärke" ;
VAL_ 986 PH_Systemzustand 0 "Anlage aus" 1 "Anlage durch einlegen R-Gang aktiviert" 2 "Anlage manuell durch Taster aktiviert" 3 "Anlage automatisch aktiviert" 4 "Anlage durch ARA aktiviert" 6 "Init - Initialisierungsphase nach Kl. 15 ein / Reset" 7 "Fehler-/gestört Zustand, System noch aktiv" ;
VAL_ 986 PH_Taster 0 "Taster_nicht_gedrueckt" 1 "Taster_gedrueckt" 2 "reserviert" 3 "Fehler" ;
VAL_ 986 ESP_MKB_Abbruch_Geschw 0 "MKB_nicht_beendet_wg_v_Schwelle" 1 "MKB_beendet_wg_v_Schwelle" ;
VAL_ 986 PLA_Anf_Aufschaltung_RVC 0 "Keine_RVC_Aufschalteanf" 1 "RVC_Aufschalteanforderung" ;
VAL_ 987 BCM_01_alt 0 "aktuell" 1 "veraltet" ;
VAL_ 987 SMLS_01_alt 0 "aktuell" 1 "veraltet" ;
VAL_ 987 ZV_02_alt 0 "aktuell" 1 "veraltet" ;
VAL_ 987 Wischer_01_alt 0 "aktuell" 1 "veraltet" ;
VAL_ 987 Anhaenger_01_alt 0 "aktuell" 1 "veraltet" ;
VAL_ 987 Klima_Sensor_02_alt 0 "aktuell" 1 "veraltet" ;
VAL_ 987 Verdeck_01_alt 0 "aktuell" 1 "veraltet" ;
VAL_ 987 Klima_11_alt 0 "aktuell" 1 "veraltet" ;
VAL_ 987 WFS_01_alt 0 "aktuell" 1 "veraltet" ;
VAL_ 987 Licht_Anf_01_alt 0 "aktuell" 1 "veraltet" ;
VAL_ 987 ZV_verriegelt_extern_soll 1 "Fahrzeug verriegelt extern; Sollzusstand" ;
VAL_ 987 BH_Lichthupe 0 "nicht_betaetigt" 1 "Blinkerhebel in Richtung Lichthupe betaetigt" ;
VAL_ 987 WFS_Klemmenfreigabe 0 "keine_Freigabe" 1 "Freigabe" ;
VAL_ 987 ZV_Tankklappe_offen 0 "Tankklappe_geschlossen" 1 "Tankklappe_offen" ;
VAL_ 987 AAG_Anhaenger_abgesteckt 1 "Anhaenger_wurde_bei_KL15_aus_abgesteckt" ;
VAL_ 987 BCM1_LDS_Stellung 0 "Init" 1 "Stellung_0" 2 "Auto" 3 "Standlicht" 4 "Abblendlicht" 7 "Fehler" ;
VAL_ 987 VS_VD_entriegelt 1 "Zustand des Verdeck entriegelt" ;
VAL_ 987 ZV_HFS_offen 0 "geschlossen" 1 "offen" ;
VAL_ 987 ZV_HBFS_offen 0 "geschlossen" 1 "offen" ;
VAL_ 987 VS_VD_offen_ver 0 "Init" 1 "Verdeck_verriegelt_und_offen" ;
VAL_ 987 VS_VD_zu_ver 1 "Zustand des Verdecks verriegelt und geschlossen" ;
VAL_ 987 ZV_BT_offen 1 "BT_geoeffnet" ;
VAL_ 987 BCM1_Rueckfahrlicht_Schalter 0 "nicht_betaetigt" 1 "betaetigt" ;
VAL_ 987 ZV_FT_offen 1 "FT_geoeffnet" ;
VAL_ 987 Wischer_vorne_aktiv 1 "Wischer vorne läuft" ;
VAL_ 987 AAG_Anhaenger_erkannt 0 "kein_Anhaenger_erkannt" 1 "AAG_Anhaenger_erkannt" ;
VAL_ 987 BCM1_MH_Schalter 0 "MH_geschlossen" 1 "MH_offen" ;
VAL_ 987 ZV_HD_offen 1 "Heckdeckel_auf" ;
VAL_ 987 Waschen_vorne_aktiv 1 "Waschen aktiv" ;
VAL_ 987 KL_Thermomanagement 0 "keine_Freigabe_TMM__max_Heizbedarf" 1 "kleine_Freigabe_TMM" 2 "mittlere_Freigabe_TMM" 3 "volle_Freigabe_TMM__kein_Heizbedarf" ;
VAL_ 987 WFS_Schluessel_Fahrberecht 0 "kein authorisierter Schluessel erkannt" 1 "aktive_Funkschluessel_Nr_01" 2 "aktive_Funkschluessel_Nr_02" 3 "aktive_Funkschluessel_Nr_03" 4 "aktive_Funkschluessel_Nr_04" 5 "aktive_Funkschluessel_Nr_05" 6 "aktive_Funkschluessel_Nr_06" 7 "aktive_Funkschluessel_Nr_07" 8 "aktive_Funkschluessel_Nr_08" 9 "ungueltig_09" 10 "ungueltig_10" 11 "ungueltig_11" 12 "ungueltig_12" 13 "ungueltig_13" 14 "ungueltig_14" 15 "digitaler_Schluessel_aktiv" ;
VAL_ 987 BCM_Rueckfahrlicht_Anf 0 "Licht_nicht_angefordert" 1 "Licht_angefordert" ;
VAL_ 987 WWSs_01_alt 0 "aktuell" 1 "veraltet" ;
VAL_ 987 BCM_Tankklappensteller_Fehler 0 "kein_Fehler" 1 "Fehler" ;
VAL_ 987 AAG_LED_aktiv 0 "Lampen" 1 "LED" ;
VAL_ 987 ZV_verriegelt_soll 0 "Init" 1 "nicht_verriegelt" 2 "verriegelt" ;
VAL_ 987 ZV_Schluessel_Zugang 0 "kein authorisierter Schluessel erkannt " 1 "aktive_Funkschluessel_Nr_01" 2 "aktive_Funkschluessel_Nr_02" 3 "aktive_Funkschluessel_Nr_03" 4 "aktive_Funkschluessel_Nr_04" 5 "aktive_Funkschluessel_Nr_05" 6 "aktive_Funkschluessel_Nr_06" 7 "aktive_Funkschluessel_Nr_07" 8 "aktive_Funkschluessel_Nr_08" 9 "ungueltig_09" 10 "ungueltig_10" 11 "ungueltig_11" 12 "ungueltig_12" 13 "ungueltig_13" 14 "ungueltig_14" 15 "ungueltig_15" ;
VAL_ 987 WFS_ID_Geb_autorisiert_in_Kl15 0 "nicht_authorisiert_in_Kl15" 1 "authorisiert_in_Kl15" ;
VAL_ 987 BH_Fernlicht 0 "nicht_betaetigt" 1 "Blinkerhebel_in_Richtung_Fernlicht_betaetigt" ;
VAL_ 987 BH_Blinker_li 0 "nicht_betaetigt" 1 "Blinkerhebel_Richtung_links_betaetigt" ;
VAL_ 987 BH_Blinker_re 0 "nicht_betaetigt" 1 "Blinkerhebel_Richtung_rechts_betaetigt" ;
VAL_ 987 BCM1_OBD_FStatus_ATemp 0 "kein Fehler / Init / nicht verbaut" 1 "KS- (Kurzschluss nach minus)" 2 "KS+ (Kurzschluss nach plus)" 3 "OC (Leitungsunterbrechung)" 4 "OOR+ (Signal zu gross)" 5 "OOR- (Signal zu klein)" 6 "RC+ (Signal unplausibel zu gross)" 7 "RC- (Signal unplausibel zu klein)" 8 "KS+/OC (Kurzschluss nach plus/Unterbrechung)" 9 "KS-/OC  (Kurzschluss nach minus/Unterbrechung)" 10 "KS-/KS+  (Kurzschluss nach minus/plus)" 11 "KS-/KS+/OC (Kurzschluss nach minus/plus/Unterbrechung)" 12 "frei" 13 "frei" 14 "frei" 15 "frei" ;
VAL_ 987 BCM1_Aussen_Temp_ungef 253 "nicht_verbaut" 254 "Initwert" 255 "Fehler" ;
VAL_ 2589284280 DU1_KSV_Value_1 0 "Init" ;
VAL_ 2589284280 DU1_KSV_Value_2 0 "Init" ;
VAL_ 2589284280 DU1_HDCP_Auth_Status_Out_1 0 "HDCP_ON" 1 "HDCP_OFF" 2 "HDCP_OFF_UNSUPPORTED" 3 "HDCP_OFF_AKE_FAILED" 4 "reserviert" 5 "Fehler" 6 "reserviert" 7 "Init" ;
VAL_ 2589284280 DU1_HDCP_Auth_Status_Out_2 0 "HDCP_ON" 1 "HDCP_OFF" 2 "HDCP_OFF_UNSUPPORTED" 3 "HDCP_OFF_AKE_FAILED" 4 "reserviert" 5 "Fehler" 6 "reserviert" 7 "Init" ;
VAL_ 2589284280 DU1_HDCP_Auth_Status_Out_3 0 "HDCP_ON" 1 "HDCP_OFF" 2 "HDCP_OFF_UNSUPPORTED" 3 "HDCP_OFF_AKE_FAILED" 4 "reserviert" 5 "Fehler" 6 "reserviert" 7 "Init" ;
VAL_ 2589284280 DU1_HDCP_Auth_Status_Out_4 0 "HDCP_ON" 1 "HDCP_OFF" 2 "HDCP_OFF_UNSUPPORTED" 3 "HDCP_OFF_AKE_FAILED" 4 "reserviert" 5 "Fehler" 6 "reserviert" 7 "Init" ;
VAL_ 2589284280 DU1_HDCP_Auth_Status_Out_5 0 "HDCP_ON" 1 "HDCP_OFF" 2 "HDCP_OFF_UNSUPPORTED" 3 "HDCP_OFF_AKE_FAILED" 4 "reserviert" 5 "Fehler" 6 "reserviert" 7 "Init" ;
VAL_ 2589284280 DU1_HDCP_Auth_Status_Out_6 0 "HDCP_ON" 1 "HDCP_OFF" 2 "HDCP_OFF_UNSUPPORTED" 3 "HDCP_OFF_AKE_FAILED" 4 "reserviert" 5 "Fehler" 6 "reserviert" 7 "Init" ;
VAL_ 2589284280 DU1_HDCP_Auth_Status_Out_7 0 "HDCP_ON" 1 "HDCP_OFF" 2 "HDCP_OFF_UNSUPPORTED" 3 "HDCP_OFF_AKE_FAILED" 4 "reserviert" 5 "Fehler" 6 "reserviert" 7 "Init" ;
VAL_ 2589284280 DU1_HDCP_Auth_Status_Out_8 0 "HDCP_ON" 1 "HDCP_OFF" 2 "HDCP_OFF_UNSUPPORTED" 3 "HDCP_OFF_AKE_FAILED" 4 "reserviert" 5 "Fehler" 6 "reserviert" 7 "Init" ;
VAL_ 2589284281 DU2_KSV_Value_1 0 "Init" ;
VAL_ 2589284281 DU2_KSV_Value_2 0 "Init" ;
VAL_ 2589284281 DU2_HDCP_Auth_Status_Out_1 0 "HDCP_ON" 1 "HDCP_OFF" 2 "HDCP_OFF_UNSUPPORTED" 3 "HDCP_OFF_AKE_FAILED" 4 "reserviert" 5 "Fehler" 6 "reserviert" 7 "Init" ;
VAL_ 2589284281 DU2_HDCP_Auth_Status_Out_2 0 "HDCP_ON" 1 "HDCP_OFF" 2 "HDCP_OFF_UNSUPPORTED" 3 "HDCP_OFF_AKE_FAILED" 4 "reserviert" 5 "Fehler" 6 "reserviert" 7 "Init" ;
VAL_ 2589284281 DU2_HDCP_Auth_Status_Out_3 0 "HDCP_ON" 1 "HDCP_OFF" 2 "HDCP_OFF_UNSUPPORTED" 3 "HDCP_OFF_AKE_FAILED" 4 "reserviert" 5 "Fehler" 6 "reserviert" 7 "Init" ;
VAL_ 2589284281 DU2_HDCP_Auth_Status_Out_4 0 "HDCP_ON" 1 "HDCP_OFF" 2 "HDCP_OFF_UNSUPPORTED" 3 "HDCP_OFF_AKE_FAILED" 4 "reserviert" 5 "Fehler" 6 "reserviert" 7 "Init" ;
VAL_ 2589284281 DU2_HDCP_Auth_Status_Out_5 0 "HDCP_ON" 1 "HDCP_OFF" 2 "HDCP_OFF_UNSUPPORTED" 3 "HDCP_OFF_AKE_FAILED" 4 "reserviert" 5 "Fehler" 6 "reserviert" 7 "Init" ;
VAL_ 2589284281 DU2_HDCP_Auth_Status_Out_6 0 "HDCP_ON" 1 "HDCP_OFF" 2 "HDCP_OFF_UNSUPPORTED" 3 "HDCP_OFF_AKE_FAILED" 4 "reserviert" 5 "Fehler" 6 "reserviert" 7 "Init" ;
VAL_ 2589284281 DU2_HDCP_Auth_Status_Out_7 0 "HDCP_ON" 1 "HDCP_OFF" 2 "HDCP_OFF_UNSUPPORTED" 3 "HDCP_OFF_AKE_FAILED" 4 "reserviert" 5 "Fehler" 6 "reserviert" 7 "Init" ;
VAL_ 2589284281 DU2_HDCP_Auth_Status_Out_8 0 "HDCP_ON" 1 "HDCP_OFF" 2 "HDCP_OFF_UNSUPPORTED" 3 "HDCP_OFF_AKE_FAILED" 4 "reserviert" 5 "Fehler" 6 "reserviert" 7 "Init" ;
VAL_ 2589284283 DU3_KSV_Value_1 0 "Init" ;
VAL_ 2589284283 DU3_KSV_Value_2 0 "Init" ;
VAL_ 2589284283 DU3_HDCP_Auth_Status_Out_1 0 "HDCP_ON" 1 "HDCP_OFF" 2 "HDCP_OFF_UNSUPPORTED" 3 "HDCP_OFF_AKE_FAILED" 4 "reserviert" 5 "Fehler" 6 "reserviert" 7 "Init" ;
VAL_ 2589284283 DU3_HDCP_Auth_Status_Out_2 0 "HDCP_ON" 1 "HDCP_OFF" 2 "HDCP_OFF_UNSUPPORTED" 3 "HDCP_OFF_AKE_FAILED" 4 "reserviert" 5 "Fehler" 6 "reserviert" 7 "Init" ;
VAL_ 2589284283 DU3_HDCP_Auth_Status_Out_3 0 "HDCP_ON" 1 "HDCP_OFF" 2 "HDCP_OFF_UNSUPPORTED" 3 "HDCP_OFF_AKE_FAILED" 4 "reserviert" 5 "Fehler" 6 "reserviert" 7 "Init" ;
VAL_ 2589284283 DU3_HDCP_Auth_Status_Out_4 0 "HDCP_ON" 1 "HDCP_OFF" 2 "HDCP_OFF_UNSUPPORTED" 3 "HDCP_OFF_AKE_FAILED" 4 "reserviert" 5 "Fehler" 6 "reserviert" 7 "Init" ;
VAL_ 2589284283 DU3_HDCP_Auth_Status_Out_5 0 "HDCP_ON" 1 "HDCP_OFF" 2 "HDCP_OFF_UNSUPPORTED" 3 "HDCP_OFF_AKE_FAILED" 4 "reserviert" 5 "Fehler" 6 "reserviert" 7 "Init" ;
VAL_ 2589284283 DU3_HDCP_Auth_Status_Out_6 0 "HDCP_ON" 1 "HDCP_OFF" 2 "HDCP_OFF_UNSUPPORTED" 3 "HDCP_OFF_AKE_FAILED" 4 "reserviert" 5 "Fehler" 6 "reserviert" 7 "Init" ;
VAL_ 2589284283 DU3_HDCP_Auth_Status_Out_7 0 "HDCP_ON" 1 "HDCP_OFF" 2 "HDCP_OFF_UNSUPPORTED" 3 "HDCP_OFF_AKE_FAILED" 4 "reserviert" 5 "Fehler" 6 "reserviert" 7 "Init" ;
VAL_ 2589284283 DU3_HDCP_Auth_Status_Out_8 0 "HDCP_ON" 1 "HDCP_OFF" 2 "HDCP_OFF_UNSUPPORTED" 3 "HDCP_OFF_AKE_FAILED" 4 "reserviert" 5 "Fehler" 6 "reserviert" 7 "Init" ;
VAL_ 960 RSt_Fahrerhinweise 0 "Init" 1 "Fahreruebernahme_Hinweis_ZAT_Automat_ohne_Gong" 2 "Fahreruebernahme_Hinweis_ZAT_Automat_mit_Gong" 3 "Fahreruebernahme_Hinweis_ZAT_Handschalter_ohne_Gong" 4 "Fahreruebernahme_Hinweis_ZAT_Handschalter_mit_Gong" 5 "Fahreruebernahme_Hinweis_ZAS_Automat_ohne_Gong" 6 "Fahreruebernahme_Hinweis_ZAS_Automat_mit_Gong" 7 "Fahreruebernahme_Hinweis_ZAS_Handschalter_ohne_Gong" 8 "Fahreruebernahme_Hinweis_ZAS_Handschalter_mit_Gong" 9 "RemoteStart_aktiv_ohne_Gong" 10 "RemoteStart_aktiv_mit_Gong" 11 "void" 12 "void" 13 "void" 14 "void" 15 "void" ;
VAL_ 960 ZAS_Kl_S 0 "aus" 1 "S_Kontakt_ein" ;
VAL_ 960 ZAS_Kl_15 0 "aus" 1 "ein" ;
VAL_ 960 ZAS_Kl_X 0 "aus" 1 "ein" ;
VAL_ 960 ZAS_Kl_50_Startanforderung 0 "aus" 1 "KL50_ein_Startwunsch_Fahrer" ;
VAL_ 960 BCM_Remotestart_Betrieb 0 "kein_RS_Betrieb" 1 "RS_Betrieb" ;
VAL_ 960 ZAS_Kl_Infotainment 0 "inaktiv" 1 "aktiv" ;
VAL_ 960 BCM_Remotestart_KL15_Anf 0 "inaktiv" 1 "aktiv" ;
VAL_ 960 BCM_Remotestart_MO_Start 0 "nicht_angefordert" 1 "angefordert" ;
VAL_ 960 KST_Warn_P1_ZST_def 0 "nicht_defekt" 1 "defekt" ;
VAL_ 960 KST_Warn_P2_ZST_def 0 "nicht_defekt" 1 "defekt" ;
VAL_ 960 KST_Fahrerhinweis_1 0 "inaktiv" 1 "aktiv" ;
VAL_ 960 KST_Fahrerhinweis_2 0 "inaktiv" 1 "aktiv" ;
VAL_ 960 BCM_Ausparken_Betrieb 0 "kein_Betrieb" 1 "Ausparkvorgang_aktiv" ;
VAL_ 960 KST_Fahrerhinweis_4 0 "inaktiv" 1 "aktiv" ;
VAL_ 960 KST_Fahrerhinweis_5 0 "inaktiv" 1 "aktiv" ;
VAL_ 960 KST_Fahrerhinweis_6 0 "inaktiv" 1 "aktiv" ;
VAL_ 2549088276 Kombi_KompSchutz 0 "inaktiv" 1 "aktiv" ;
VAL_ 2549088276 Kombi_Abschaltstufe 0 "keine_Einschraenkung" 1 "Funktionseinschraenkung" ;
VAL_ 2549088276 Kombi_Transport_Mode 0 "keine_Einschraenkung" 1 "Funktionseinschraenkung" ;
VAL_ 2549088276 Kombi_Nachlauftyp 0 "Komm_bei_KL15_EIN" 1 "Komm_nach_KL15_AUS" 2 "Komm_bei_KL15_AUS" ;
VAL_ 2549088276 Kombi_SNI 20 "Kombi" ;
VAL_ 2549088276 KN_KBI_DiagPfad 0 "aktiv" 1 "inaktiv" ;
VAL_ 2549088276 KBI_KD_Fehler 0 "kein_KD_Fehler" 1 "KD_Fehler" ;
VAL_ 2549088426 SCC1_KompSchutz 0 "inaktiv" 1 "aktiv" ;
VAL_ 2549088426 SCC1_Abschaltstufe 0 "keine_Einschraenkung" 1 "Funktionseinschraenkung" ;
VAL_ 2549088426 SCC1_Transport_Mode 0 "keine_Einschraenkung" 1 "Funktionseinschraenkung" ;
VAL_ 2549088426 SCC1_Nachlauftyp 0 "Komm_bei_KL15_EIN" 1 "Komm_nach_KL15_AUS" 2 "Komm_bei_KL15_AUS" ;
VAL_ 2549088426 SCC1_SNI 170 "SCC1" ;
VAL_ 2549088426 KN_SCC1_BusKnockOutTimer 255 "BusKnockOut_deaktiviert" ;
VAL_ 2549088426 NM_SCC1_Wakeup 0 "Peripherie_Wakeup__Ursache_nicht_bekannt" 1 "Bus_Wakeup" 2 "KL15_HW" 3 "SmartDisplay_Wakeup" ;
VAL_ 2549088426 NM_SCC1_Lokalaktiv 0 "war_nicht_lokal_aktiv" 1 "war_lokal_aktiv" ;
VAL_ 2549088426 SCC1_KD_Fehler 0 "kein_KD_Fehler" 1 "KD_Fehler" ;
VAL_ 2549088427 SCC2_KompSchutz 0 "inaktiv" 1 "aktiv" ;
VAL_ 2549088427 SCC2_Abschaltstufe 0 "keine_Einschraenkung" 1 "Funktionseinschraenkung" ;
VAL_ 2549088427 SCC2_Transport_Mode 0 "keine_Einschraenkung" 1 "Funktionseinschraenkung" ;
VAL_ 2549088427 SCC2_Nachlauftyp 0 "Komm_bei_KL15_EIN" 1 "Komm_nach_KL15_AUS" 2 "Komm_bei_KL15_AUS" ;
VAL_ 2549088427 SCC2_SNI 171 "SCC2" ;
VAL_ 2549088427 KN_SCC2_BusKnockOutTimer 255 "BusKnockOut_deaktiviert" ;
VAL_ 2549088427 NM_SCC2_Wakeup 0 "Peripherie_Wakeup__Ursache_nicht_bekannt" 1 "Bus_Wakeup" 2 "KL15_HW" 3 "SmartDisplay_Wakeup" ;
VAL_ 2549088427 NM_SCC2_Lokalaktiv 0 "war_nicht_lokal_aktiv" 1 "war_lokal_aktiv" ;
VAL_ 2549088427 SCC2_KD_Fehler 0 "kein_KD_Fehler" 1 "KD_Fehler" ;
VAL_ 2549088423 SDC1_KompSchutz 0 "inaktiv" 1 "aktiv" ;
VAL_ 2549088423 SDC1_Abschaltstufe 0 "keine_Einschraenkung" 1 "Funktionseinschraenkung" ;
VAL_ 2549088423 SDC1_Transport_Mode 0 "keine_Einschraenkung" 1 "Funktionseinschraenkung" ;
VAL_ 2549088423 SDC1_Nachlauftyp 0 "Komm_bei_KL15_EIN" 1 "Komm_nach_KL15_AUS" 2 "Komm_bei_KL15_AUS" ;
VAL_ 2549088423 SDC1_SNI 167 "SDC1" ;
VAL_ 2549088423 KN_SDC1_BusKnockOutTimer 255 "BusKnockOut_deaktiviert" ;
VAL_ 2549088423 NM_SDC1_Wakeup 0 "Peripherie_Wakeup__Ursache_nicht_bekannt" 1 "Bus_Wakeup" 2 "KL15_HW" 3 "SmartDisplay_Wakeup" ;
VAL_ 2549088423 NM_SDC1_Lokalaktiv 0 "war_nicht_lokal_aktiv" 1 "war_lokal_aktiv" ;
VAL_ 2549088423 SDC1_KD_Fehler 0 "kein_KD_Fehler" 1 "KD_Fehler" ;
VAL_ 2549088424 SDC2_KompSchutz 0 "inaktiv" 1 "aktiv" ;
VAL_ 2549088424 SDC2_Abschaltstufe 0 "keine_Einschraenkung" 1 "Funktionseinschraenkung" ;
VAL_ 2549088424 SDC2_Transport_Mode 0 "keine_Einschraenkung" 1 "Funktionseinschraenkung" ;
VAL_ 2549088424 SDC2_Nachlauftyp 0 "Komm_bei_KL15_EIN" 1 "Komm_nach_KL15_AUS" 2 "Komm_bei_KL15_AUS" ;
VAL_ 2549088424 SDC2_SNI 168 "SDC2" ;
VAL_ 2549088424 KN_SDC2_BusKnockOutTimer 255 "BusKnockOut_deaktiviert" ;
VAL_ 2549088424 NM_SDC2_Wakeup 0 "Peripherie_Wakeup__Ursache_nicht_bekannt" 1 "Bus_Wakeup" 2 "KL15_HW" 3 "SmartDisplay_Wakeup" ;
VAL_ 2549088424 NM_SDC2_Lokalaktiv 0 "war_nicht_lokal_aktiv" 1 "war_lokal_aktiv" ;
VAL_ 2549088424 SDC2_KD_Fehler 0 "kein_KD_Fehler" 1 "KD_Fehler" ;
